VERSION ""

NS_ :

BS_:

BU_: SHVU_CCS_FD ARS_FD WPC_FD WPC2_FD SCM_FD SHVU_FRNT_FD FLLR_FD vDummy_FD_B2 GW_SAU_DRV_FD ATS_FD PSB_FD GW_PSU_RR_FD SHVU_RL_FD RWPC_FD CGW_CCU OHCL_FD SHVU_REAR_FD BLTN_CAM_FD GW_PSU_DRV_FD FCS_FD GW_PSU_AST_FD GW_PSU_3RD_FD RCS_FD GW_PSU_RL_FD SHVU_3RD_FD SHVU_RR_FD RCM_FD DCM_FD SGU_FD vFD_B2

BO_ 745 PDC_FD_15_300ms: 32 CGW_CCU
 SG_ PDC_FD_Crc15Val : 0|16@1+ (1,0) [0|0] ""  ARS_FD,ATS_FD,BLTN_CAM_FD,FCS_FD,GW_PSU_3RD_FD,GW_PSU_AST_FD,GW_PSU_DRV_FD,GW_PSU_RL_FD,GW_PSU_RR_FD,GW_SAU_DRV_FD,OHCL_FD,PSB_FD,RCM_FD,RCS_FD,RWPC_FD,SCM_FD,SGU_FD,SHVU_3RD_FD,SHVU_FRNT_FD,SHVU_REAR_FD,SHVU_RL_FD,SHVU_RR_FD,WPC2_FD,WPC_FD
 SG_ PDC_CurrAtReset : 104|12@1+ (10,-40940) [-40940|0] "mA" Vector__XXX
 SG_ PDC_AvgCurrAtReset : 120|12@1+ (10,-40940) [-40940|0] "mA" Vector__XXX
 SG_ PDC_ResetReason : 132|3@1+ (1,0) [0|0] "" Vector__XXX
 SG_ PDC_CumulativeCountOf12VReq : 136|10@1+ (1,0) [0|0] "" Vector__XXX
 SG_ PDC_CumulativeCountOfCCUReq : 146|10@1+ (1,0) [0|0] "" Vector__XXX
 SG_ PDC_VehCondiForReset : 156|2@1+ (1,0) [0|0] "" Vector__XXX
 SG_ PDC_FD_AlvCnt15Val : 16|8@1+ (1,0) [0|0] ""  ARS_FD,ATS_FD,BLTN_CAM_FD,FCS_FD,GW_PSU_3RD_FD,GW_PSU_AST_FD,GW_PSU_DRV_FD,GW_PSU_RL_FD,GW_PSU_RR_FD,GW_SAU_DRV_FD,OHCL_FD,PSB_FD,RCM_FD,RCS_FD,RWPC_FD,SCM_FD,SGU_FD,SHVU_3RD_FD,SHVU_FRNT_FD,SHVU_REAR_FD,SHVU_RL_FD,SHVU_RR_FD,WPC2_FD,WPC_FD
 SG_ PDC_LDConReq : 184|2@1+ (1,0) [0|0] ""  BLTN_CAM_FD
 SG_ PDC_LDConReq_By_LVBat : 186|2@1+ (1,0) [0|0] ""  BLTN_CAM_FD
 SG_ PDC_LDConReq_By_OTA : 188|2@1+ (1,0) [0|0] "" Vector__XXX
 SG_ PDC_LDConReq_By_Load : 190|2@1+ (1,0) [0|0] "" Vector__XXX
 SG_ PDC_LDConReq_By_ActiveOn : 192|2@1+ (1,0) [0|0] ""  BLTN_CAM_FD
 SG_ PDC_ResetPreWrngForCCU : 40|2@1+ (1,0) [0|0] "" Vector__XXX
 SG_ PDC_ResetPreWrngForOthers : 42|2@1+ (1,0) [0|0] ""  ARS_FD,ATS_FD,BLTN_CAM_FD,DCM_FD,FCS_FD,GW_PSU_3RD_FD,GW_PSU_AST_FD,GW_PSU_DRV_FD,GW_PSU_RL_FD,GW_PSU_RR_FD,GW_SAU_DRV_FD,OHCL_FD,PSB_FD,RCM_FD,RCS_FD,RWPC_FD,SCM_FD,SGU_FD,SHVU_3RD_FD,SHVU_FRNT_FD,SHVU_REAR_FD,SHVU_RL_FD,SHVU_RR_FD,WPC2_FD,WPC_FD
 SG_ PDC_ResetReqForCCU : 44|2@1+ (1,0) [0|0] "" Vector__XXX
 SG_ PDC_ResetReqForOthers : 46|2@1+ (1,0) [0|0] ""  ARS_FD,ATS_FD,BLTN_CAM_FD,DCM_FD,FCS_FD,GW_PSU_3RD_FD,GW_PSU_AST_FD,GW_PSU_DRV_FD,GW_PSU_RL_FD,GW_PSU_RR_FD,GW_SAU_DRV_FD,OHCL_FD,PSB_FD,RCM_FD,RCS_FD,RWPC_FD,SCM_FD,SGU_FD,SHVU_3RD_FD,SHVU_FRNT_FD,SHVU_REAR_FD,SHVU_RL_FD,SHVU_RR_FD,WPC2_FD,WPC_FD
 SG_ PDC_ResetFuncOpt : 48|2@1+ (1,0) [0|0] ""  DCM_FD,RWPC_FD,WPC2_FD,WPC_FD
 SG_ PDC_12VRlyCtrl : 50|2@1+ (1,0) [0|0] "" Vector__XXX
 SG_ PDC_CurrentValueForReset : 52|8@1+ (50,0) [0|0] "mA" Vector__XXX
 SG_ PDC_WakeUpReqForReset : 60|2@1+ (1,0) [0|0] "" Vector__XXX
 SG_ PDC_TimeValueForReset : 64|8@1+ (0.5,0) [0|0] "h" Vector__XXX
 SG_ PDC_12VRlyOffHoldingTime : 72|5@1+ (0.5,0) [0|0] "s" Vector__XXX
 SG_ PDC_ResetCountSetting : 77|2@1+ (1,0) [0|0] "" Vector__XXX
 SG_ PDC_ResetCount : 79|2@1+ (1,0) [0|0] "" Vector__XXX
 SG_ PDC_ResetCumulativeCount : 81|10@1+ (1,0) [0|0] "" Vector__XXX
 SG_ PDC_ResetOpsta : 91|2@1+ (1,0) [0|0] "" Vector__XXX
 SG_ PDC_ReadyTimeValueForReset : 96|8@1+ (10,0) [0|255] "Min" Vector__XXX

BO_ 64 TCU_01_10ms: 32 CGW_CCU
 SG_ TCU_Crc1Val : 0|16@1+ (1,0) [0|0] "" Vector__XXX
 SG_ TCU_DcmlVehSpdKphVal : 104|8@1+ (0.0078125,0) [0|0] "km/h" Vector__XXX
 SG_ TCU_SprkRtrdReq : 112|8@1+ (0.375,-23.625) [0|0] "˚" Vector__XXX
 SG_ TCU_EngRpmDisSta : 120|2@1+ (1,0) [0|0] "" Vector__XXX
 SG_ TCU_GearLmpBlnkngReq : 122|2@1+ (1,0) [0|0] "" Vector__XXX
 SG_ TCU_FuelCutInhbtReq : 124|2@1+ (1,0) [0|0] "" Vector__XXX
 SG_ TCU_IdleUpReq : 126|2@1+ (1,0) [0|0] "" Vector__XXX
 SG_ TCU_EngRpmDis : 128|16@1+ (0.25,0) [0|0] "rpm" Vector__XXX
 SG_ TCU_SlpVal : 144|6@1+ (0.5,-16) [0|0] "%" Vector__XXX
 SG_ TCU_EngSpdIncReq : 150|2@1+ (1,0) [0|0] "" Vector__XXX
 SG_ TCU_ObdSta : 152|3@1+ (1,0) [0|0] "" Vector__XXX
 SG_ TCU_SprtyIndxSta : 155|5@1+ (1,0) [0|0] "" Vector__XXX
 SG_ TCU_AlvCnt1Val : 16|8@1+ (1,0) [0|0] "" Vector__XXX
 SG_ TCU_DrvngModDis : 160|3@1+ (1,0) [0|0] "" Vector__XXX
 SG_ TCU_DrvngModReq : 163|3@1+ (1,0) [0|0] "" Vector__XXX
 SG_ TCU_SmrtShftSta : 166|2@1+ (1,0) [0|0] "" Vector__XXX
 SG_ TCU_LupTrgtEngSpdVal : 168|8@1+ (10,500) [0|0] "rpm" Vector__XXX
 SG_ TCU_FrtStcShftSta : 176|2@1+ (1,0) [0|0] "" Vector__XXX
 SG_ TCU_IsgInhbtReq : 178|2@1+ (1,0) [0|0] "" Vector__XXX
 SG_ TCU_CdaInhbtReq : 180|2@1+ (1,0) [0|0] "" Vector__XXX
 SG_ TCU_BrkOnReq : 182|2@1+ (1,0) [0|0] "" Vector__XXX
 SG_ TCU_TqGrdntLimVal : 184|8@1+ (10,0) [0|0] "Nm/s" Vector__XXX
 SG_ TCU_NetrlCtrlSta : 192|2@1+ (1,0) [0|0] "" Vector__XXX
 SG_ TCU_ShftPtrnSta : 194|4@1+ (1,0) [0|0] "" Vector__XXX
 SG_ TCU_VgisInhbtReq : 198|2@1+ (1,0) [0|0] "" Vector__XXX
 SG_ TCU_EngTqIncReqVal : 200|12@1- (1,0) [0|0] "Nm" Vector__XXX
 SG_ TCU_EPBReq : 212|1@1+ (1,0) [0|0] "" Vector__XXX
 SG_ IMT_EOLstate : 213|1@1+ (1,0) [0|0] "" Vector__XXX
 SG_ IMT_DisCmd : 214|2@1+ (1,0) [0|0] "" Vector__XXX
 SG_ IMT_CltchPdlPos : 216|8@1+ (0.390625,0) [0|0] "%" Vector__XXX
 SG_ DCT_RegenInhbt : 224|2@1+ (1,0) [0|0] "" Vector__XXX
 SG_ DCT_EngIdleReq : 226|2@1+ (1,0) [0|0] "" Vector__XXX
 SG_ DCT_CltchState : 228|2@1+ (1,0) [0|0] "" Vector__XXX
 SG_ DCT_FuelCutReq : 230|2@1+ (1,0) [0|0] "" Vector__XXX
 SG_ DCT_TqIncReq : 232|2@1+ (1,0) [0|0] "" Vector__XXX
 SG_ DCT_CrpTqReq : 234|10@1+ (1,-512) [0|0] "Nm" Vector__XXX
 SG_ DCT_ShftTqReq : 244|12@1- (1,0) [0|0] "Nm" Vector__XXX
 SG_ TCU_GearSlctDis : 32|4@1+ (1,0) [0|0] ""  BLTN_CAM_FD,DCM_FD,FCS_FD,GW_PSU_3RD_FD,GW_PSU_AST_FD,GW_PSU_RL_FD,GW_PSU_RR_FD,SHVU_RL_FD,SHVU_RR_FD
 SG_ TCU_Typ : 36|4@1+ (1,0) [0|0] ""  GW_PSU_3RD_FD,GW_PSU_AST_FD
 SG_ TCU_TqRdctnVal : 40|12@1- (1,0) [0|0] "Nm" Vector__XXX
 SG_ CF_TCU_AES_Flag : 52|1@1+ (1,0) [0|0] "" Vector__XXX
 SG_ TCU_GearStepTyp : 56|4@1+ (1,0) [0|0] "" Vector__XXX
 SG_ TCU_GearShftSta : 60|2@1+ (1,0) [0|0] "" Vector__XXX
 SG_ TCU_TqCnvrtrSta : 62|2@1+ (1,0) [0|0] "" Vector__XXX
 SG_ TCU_CurrGearSta : 64|4@1+ (1,0) [0|0] "" Vector__XXX
 SG_ TCU_TrgtGearSta : 68|4@1+ (1,0) [0|0] "" Vector__XXX
 SG_ TCU_CluTrgtGearSta : 72|4@1+ (1,0) [0|0] "" Vector__XXX
 SG_ TCH_EngTrgtGearSta : 76|4@1+ (1,0) [0|0] "" Vector__XXX
 SG_ TCU_EngTqLimVal : 80|12@1- (1,0) [0|0] "Nm" Vector__XXX
 SG_ TCU_CluTrgtGearConfg : 92|2@1+ (1,0) [0|0] "" Vector__XXX
 SG_ TCU_DesiBoost : 94|1@1+ (1,0) [0|0] "" Vector__XXX
 SG_ TCU_VehSpdKphVal : 96|8@1+ (1,0) [0|0] "km/h" Vector__XXX

BO_ 1308 CCU_VAPI_BLTNCAM_01_00ms: 32 CGW_CCU
 SG_ VAPI_BltnCamInsideSwEnable_Set : 24|2@1+ (1,0) [0|0] ""  BLTN_CAM_FD

BO_ 613 EMS_08_100ms: 32 CGW_CCU
 SG_ EMS_Crc8Val : 0|16@1+ (1,0) [0|0] "" Vector__XXX
 SG_ HEV_EstClntTempVal : 128|8@1+ (0.75,-48) [0|0] "℃" Vector__XXX
 SG_ HEV_AptVal : 136|8@1+ (2,0) [0|0] "PSI" Vector__XXX
 SG_ HEV_EstAmbtAirTempVal : 144|8@1+ (0.75,-48) [0|0] "℃" Vector__XXX
 SG_ HEV_RbmSta : 152|7@1+ (1,0) [0|0] "" Vector__XXX
 SG_ HEV_WarmUpReq_For_DATC : 159|1@1+ (1,0) [0|0] "" Vector__XXX
 SG_ EMS_AlvCnt8Val : 16|8@1+ (1,0) [0|0] "" Vector__XXX
 SG_ HEV_RbmInhbtSta : 160|2@1+ (1,0) [0|0] "" Vector__XXX
 SG_ HEV_EhrsTempSta : 162|2@1+ (1,0) [0|0] "" Vector__XXX
 SG_ HEV_Aaf_WrnLamp : 164|2@1+ (1,0) [0|0] "" Vector__XXX
 SG_ HEV_OPSFail : 166|2@1+ (1,0) [0|0] "" Vector__XXX
 SG_ HEV_EngDsplceTyp : 168|8@1+ (0.1,0) [0|0] "liter" Vector__XXX
 SG_ HEV_EngTyp2 : 176|4@1+ (1,0) [0|0] "" Vector__XXX
 SG_ HEV_EngTyp1 : 180|4@1+ (1,0) [0|0] "" Vector__XXX
 SG_ HEV_S_F : 184|2@1+ (1,0) [0|0] "" Vector__XXX
 SG_ HEV_S_F_GEN : 186|3@1+ (1,0) [0|0] "" Vector__XXX
 SG_ HEV_RbmSta_2nd : 192|7@1+ (1,0) [0|0] "" Vector__XXX
 SG_ HEV_RECTrigSta : 200|1@1+ (1,0) [0|0] "" Vector__XXX
 SG_ HEV_PendingTrigSta : 201|1@1+ (1,0) [0|0] "" Vector__XXX
 SG_ HEV_OilLifeRatio : 202|7@1+ (1,0) [0|0] "%" Vector__XXX
 SG_ HEV_OilLifeEna : 209|2@1+ (1,0) [0|0] "" Vector__XXX
 SG_ HEV_OilLifeWarn : 211|3@1+ (1,0) [0|0] "" Vector__XXX
 SG_ HEV_ExtSoakTimeVal : 214|6@1+ (5,0) [0|0] "" Vector__XXX
 SG_ HEV_AmbPrs : 220|12@1+ (1.3269841,0) [0|0] "hPa" Vector__XXX
 SG_ HEV_EngClntTempVal : 24|8@1+ (0.75,-48) [0|0] "℃" Vector__XXX
 SG_ HEV_EngOilTempVal : 32|8@1+ (1,-40) [0|0] "℃" Vector__XXX
 SG_ HEV_VbOffActSta : 40|2@1+ (1,0) [0|0] "" Vector__XXX
 SG_ HEV_AirCompOffReq : 42|2@1+ (1,0) [0|0] "" Vector__XXX
 SG_ HEV_MilConfgVal : 44|3@1+ (1,0) [0|0] "" Vector__XXX
 SG_ HEV_CF_EMS_LOCKUP : 47|1@1+ (1,0) [0|0] "" Vector__XXX
 SG_ HEV_OilLvlSta : 48|2@1+ (1,0) [0|0] "" Vector__XXX
 SG_ HEV_ImmoLmpReq : 50|2@1+ (1,0) [0|0] "" Vector__XXX
 SG_ HEV_MilReq : 52|2@1+ (1,0) [0|0] "" Vector__XXX
 SG_ HEV_WiperSwSta : 54|2@1+ (1,0) [0|0] "" Vector__XXX
 SG_ HEV_FanOpSta : 56|2@1+ (1,0) [0|0] "" Vector__XXX
 SG_ HEV_FanSta : 58|2@1+ (1,0) [0|0] "" Vector__XXX
 SG_ HEV_BrkLtSwSta : 62|2@1+ (1,0) [0|0] ""  BLTN_CAM_FD
 SG_ HEV_IgnCycCntVal : 64|16@1+ (1,0) [0|0] "" Vector__XXX
 SG_ HEV_SoakTimeVal : 80|8@1+ (1,0) [0|0] "Min" Vector__XXX
 SG_ HEV_SoakTimeErrSta : 88|2@1+ (1,0) [0|0] "" Vector__XXX
 SG_ HEV_SoakTimeOvrSta : 90|2@1+ (1,0) [0|0] "" Vector__XXX
 SG_ HEV_FuelRunOutSta : 92|2@1+ (1,0) [0|0] "" Vector__XXX
 SG_ HEV_FuelRunOutDetSta : 94|2@1+ (1,0) [0|0] "" Vector__XXX
 SG_ HEV_FuelCnsmptSumVal : 96|32@1+ (0.0001280018,0) [0|0] "ml" Vector__XXX

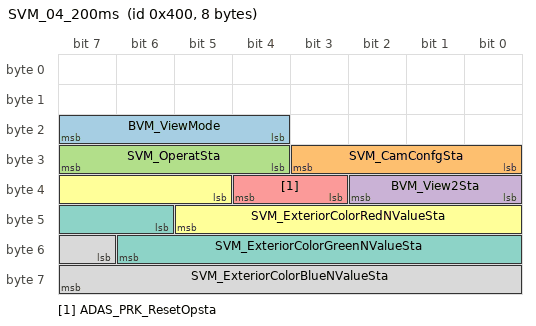
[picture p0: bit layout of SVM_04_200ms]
BO_ 1024 SVM_04_200ms: 8 CGW_CCU
 SG_ BVM_ViewMode : 20|4@1+ (1,0) [0|0] "" Vector__XXX
 SG_ SVM_CamConfgSta : 24|4@1+ (1,0) [0|0] ""  BLTN_CAM_FD
 SG_ SVM_OperatSta : 28|4@1+ (1,0) [0|0] ""  BLTN_CAM_FD
 SG_ BVM_View2Sta : 32|3@1+ (1,0) [0|0] "" Vector__XXX
 SG_ ADAS_PRK_ResetOpsta : 35|2@1+ (1,0) [0|0] "" Vector__XXX
 SG_ SVM_ExteriorColorRedNValueSta : 37|9@1+ (1,0) [0|0] "" Vector__XXX
 SG_ SVM_ExteriorColorGreenNValueSta : 46|9@1+ (1,0) [0|0] "" Vector__XXX
 SG_ SVM_ExteriorColorBlueNValueSta : 55|9@1+ (1,0) [0|0] "" Vector__XXX

BO_ 1026 BDC_FD_SMK_03_200ms: 32 CGW_CCU
 SG_ BDC_FD_SMK_Crc3Val : 0|16@1+ (1,0) [0|0] "" Vector__XXX
 SG_ SMK_TrmnlCtrlStaBDCEV : 104|5@1+ (1,0) [0|0] ""  BLTN_CAM_FD
 SG_ SMK_PwrOnModeSta : 109|2@1+ (1,0) [0|0] ""  SGU_FD
 SG_ SMK_StndbyMdTmrMin : 112|6@1+ (1,0) [0|0] "" Vector__XXX
 SG_ SMK_PwrTransitionReq : 118|2@1+ (1,0) [0|0] "" Vector__XXX
 SG_ SMK_StndbyMdTmrSec : 120|6@1+ (1,0) [0|0] "" Vector__XXX
 SG_ SMK_VhclSlpSta : 126|2@1+ (1,0) [0|0] "" Vector__XXX
 SG_ USM_SmrtSldngModSta : 128|3@1+ (1,0) [0|0] "" Vector__XXX
 SG_ SMK_EVPwrOffReq : 131|2@1+ (1,0) [0|0] "" Vector__XXX
 SG_ SMK_MaintenanceSrvMdReq : 133|2@1+ (1,0) [0|0] "" Vector__XXX
 SG_ Warn_DisWrngSta3 : 135|5@1+ (1,0) [0|0] ""  ATS_FD
 SG_ SMK_CCUOTACrankInhState : 140|2@1+ (1,0) [0|0] "" Vector__XXX
 SG_ SMK_NParkModePwrOFFResult : 142|2@1+ (1,0) [0|0] "" Vector__XXX
 SG_ SMK_TwoPressStrtSta : 144|2@1+ (1,0) [0|0] "" Vector__XXX
 SG_ SMK_PwrOffDspBtnActvSta : 146|2@1+ (1,0) [0|0] "" Vector__XXX
 SG_ SMK_GetOffPopUpReq : 148|2@1+ (1,0) [0|0] "" Vector__XXX
 SG_ SMK_PwrOffHardBtnPopupReq : 150|3@1+ (1,0) [0|0] "" Vector__XXX
 SG_ SMK_EVRdyOffReq : 153|2@1+ (1,0) [0|0] "" Vector__XXX
 SG_ SMK_NTowMdAuthFailSta : 155|2@1+ (1,0) [0|0] "" Vector__XXX
 SG_ SMK_SftyMdExitOKSta : 157|2@1+ (1,0) [0|0] "" Vector__XXX
 SG_ SMK_SftyMdPopup : 159|3@1+ (1,0) [0|0] "" Vector__XXX
 SG_ BDC_FD_SMK_AlvCnt3Val : 16|8@1+ (1,0) [0|0] "" Vector__XXX
 SG_ SMK_HUOTACrankInhState : 162|2@1+ (1,0) [0|0] "" Vector__XXX
 SG_ SMK_EasyPwrOffOpt : 164|2@1+ (1,0) [0|0] "" Vector__XXX
 SG_ SMK_EasyPwrOffInProgress : 166|2@1+ (1,0) [0|0] "" Vector__XXX
 SG_ ESCL_EsclMngrSta : 24|4@1+ (1,0) [0|0] "" Vector__XXX
 SG_ ESCL_EsclPwrSupSta : 28|2@1+ (1,0) [0|0] "" Vector__XXX
 SG_ Fob_FoundExtrnlIntArea : 30|2@1+ (1,0) [0|0] "" Vector__XXX
 SG_ ESCL_EsclEnaSta : 32|2@1+ (1,0) [0|0] "" Vector__XXX
 SG_ ESCL_EsclUnitSta : 34|3@1+ (1,0) [0|0] "" Vector__XXX
 SG_ ESCL_EsclBoltSta : 37|3@1+ (1,0) [0|0] "" Vector__XXX
 SG_ ESCL_EsclLoBattSta : 40|3@1+ (1,0) [0|0] "" Vector__XXX
 SG_ ESCL_EsclUnLkSwSta : 43|3@1+ (1,0) [0|0] "" Vector__XXX
 SG_ Fob_FoundRrLftArea : 46|2@1+ (1,0) [0|0] "" Vector__XXX
 SG_ Fob_FoundRrRtArea : 48|2@1+ (1,0) [0|0] "" Vector__XXX
 SG_ Warn_StrtStpBtnWrngSta : 50|2@1+ (1,0) [0|0] "" Vector__XXX
 SG_ Warn_DeActvWrngSta : 52|2@1+ (1,0) [0|0] "" Vector__XXX
 SG_ Warn_GearPosPWrngReq : 54|2@1+ (1,0) [0|0] "" Vector__XXX
 SG_ Warn_ExtrnlBuzWrngSta : 56|4@1+ (1,0) [0|0] "" Vector__XXX
 SG_ Warn_IdOutWrngSta : 60|2@1+ (1,0) [0|0] "" Vector__XXX
 SG_ Warn_KeyBattLoWrngSta : 62|2@1+ (1,0) [0|0] "" Vector__XXX
 SG_ Warn_KeyOutLmpOnReq : 64|2@1+ (1,0) [0|0] "" Vector__XXX
 SG_ Warn_NotGearPosPWrngSta : 66|2@1+ (1,0) [0|0] "" Vector__XXX
 SG_ Warn_EsclFlWrngSta : 68|2@1+ (1,0) [0|0] "" Vector__XXX
 SG_ Warn_EsclNotLkWrngSta : 70|2@1+ (1,0) [0|0] "" Vector__XXX
 SG_ Warn_EsclNotUnLkWrngSta : 72|2@1+ (1,0) [0|0] "" Vector__XXX
 SG_ Warn_ImmoLmpOnReq : 74|2@1+ (1,0) [0|0] "" Vector__XXX
 SG_ Warn_DisWrngSta2 : 76|4@1+ (1,0) [0|0] "" Vector__XXX
 SG_ Warn_DisWrngSta : 80|5@1+ (1,0) [0|0] "" Vector__XXX
 SG_ SMK_OTACrankInhState : 85|3@1+ (1,0) [0|0] "" Vector__XXX
 SG_ SMK_TgltAwaySrchResult : 88|2@1+ (1,0) [0|0] "" Vector__XXX
 SG_ SMKFOBID_CHNAVNT : 90|3@1+ (1,0) [0|0] "" Vector__XXX
 SG_ SMK_TrmnlCtrlGrpStaBDC : 93|3@1+ (1,0) [0|0] ""  BLTN_CAM_FD
 SG_ SMK_TrmnlCtrlGrpStaBDCEV : 96|3@1+ (1,0) [0|0] ""  BLTN_CAM_FD
 SG_ SMK_TrmnlCtrlStaBDC : 99|5@1+ (1,0) [0|0] "" Vector__XXX

BO_ 193 BLTN_CAM_FD_01_00ms: 16 BLTN_CAM_FD
 SG_ BLTN_CAM_FD_Crc1Val : 0|16@1+ (1,0) [0|0] "" Vector__XXX
 SG_ BLTN_CAM_FD_AlvCnt1Val : 16|8@1+ (1,0) [0|0] "" Vector__XXX
 SG_ BLTN_CAM_UI_Mode_Tmt_Req : 64|2@1+ (1,0) [0|0] ""  CGW_CCU
 SG_ BLTN_CAM_PopUp_Req : 66|4@1+ (1,0) [0|0] ""  CGW_CCU
 SG_ BLTN_CAM_File_List_Renew : 70|2@1+ (1,0) [0|0] ""  CGW_CCU
 SG_ BLTN_CAM_Wifi_Pwd_Chg_State : 72|2@1+ (1,0) [0|0] ""  CGW_CCU
 SG_ BLTN_CAM_Dis_Touch_BeepSound : 74|2@1+ (1,0) [0|0] ""  CGW_CCU

BO_ 345 LBM_FD_02_100ms: 32 CGW_CCU
 SG_ LBM_FD_Crc2Val : 0|16@1+ (1,0) [0|0] "" Vector__XXX
 SG_ MainLBM_NormalPwrVal : 112|16@1+ (1,0) [0|0] "Watt" Vector__XXX
 SG_ MainLBM_NormalWhVal : 128|16@1+ (1,0) [0|0] "Wh" Vector__XXX
 SG_ MainLBM_NormalReserveTimeVal : 144|20@1+ (1,0) [0|0] "Sec" Vector__XXX
 SG_ LBM_FD_AlvCnt2Val : 16|8@1+ (1,0) [0|0] "" Vector__XXX
 SG_ MainLBM_SleepReserveTimeVal : 164|20@1+ (1,0) [0|0] "Min" Vector__XXX
 SG_ MainLBM_CurrVal : 24|16@1+ (0.01,-327) [0|0] "A"  BLTN_CAM_FD
 SG_ MainLBM_SocVal : 40|8@1+ (1,0) [0|0] ""  BLTN_CAM_FD
 SG_ MainLBM_VtgVal : 48|14@1+ (0.001,6) [0|0] "V"  BLTN_CAM_FD
 SG_ MainLBM_TempVal : 62|9@1+ (0.5,-40) [0|0] "℃"  BLTN_CAM_FD
 SG_ MainLBM_SocErrSta : 71|2@1+ (1,0) [0|0] ""  BLTN_CAM_FD
 SG_ MainLBM_SohVal : 73|8@1+ (1,0) [0|0] "%"  BLTN_CAM_FD
 SG_ MainLBM_SnsrInvldSta : 81|2@1+ (1,0) [0|0] ""  BLTN_CAM_FD
 SG_ MainLBM_RspErrSta : 83|2@1+ (1,0) [0|0] ""  BLTN_CAM_FD
 SG_ MainLBM_CapacityVal : 85|8@1+ (1,0) [0|0] ""  BLTN_CAM_FD
 SG_ MainLBM_SohErrSta : 93|2@1+ (1,0) [0|0] ""  BLTN_CAM_FD
 SG_ MainLBM_PeakLoadPwrVal : 96|16@1+ (1,0) [0|0] "Watt" Vector__XXX

BO_ 74 IMU_01_10ms: 32 CGW_CCU
 SG_ IMU_Crc1Val : 0|16@1+ (1,0) [0|0] "" Vector__XXX
 SG_ IMU_SnsrTempVal : 112|8@1+ (1,-68) [0|0] "℃" Vector__XXX
 SG_ IMU_SeralNumVal : 128|48@1+ (1,0) [0|0] "" Vector__XXX
 SG_ IMU_AlvCnt1Val : 16|8@1+ (1,0) [0|0] "" Vector__XXX
 SG_ IMU_RollRtVal : 192|16@1+ (0.005,-163.84) [0|0] "˚/s" Vector__XXX
 SG_ IMU_VerAccelVal : 208|16@1+ (0.000127465,-4.17677312) [0|0] "g" Vector__XXX
 SG_ IMU_PitchRtVal : 224|16@1+ (0.005,-163.84) [-163.84|163.83] "˚/s" Vector__XXX
 SG_ IMU_YawSigSta : 24|4@1+ (1,0) [0|0] ""  PSB_FD
 SG_ IMU_LatAccelSigSta : 28|4@1+ (1,0) [0|0] ""  BLTN_CAM_FD,PSB_FD
 SG_ IMU_LongAccelSigSta : 32|4@1+ (1,0) [0|0] ""  BLTN_CAM_FD,PSB_FD
 SG_ IMU_VerAccelSigSta : 36|4@1+ (1,0) [0|0] "" Vector__XXX
 SG_ IMU_McuVoltSta : 40|4@1+ (1,0) [0|0] "" Vector__XXX
 SG_ IMU_AcuRstSta : 44|4@1+ (1,0) [0|0] "" Vector__XXX
 SG_ IMU_SnsrTyp : 48|4@1+ (1,0) [0|0] "" Vector__XXX
 SG_ IMU_RollSigSta : 56|4@1+ (1,0) [0|0] "" Vector__XXX
 SG_ IMU_PitchSigSta : 60|4@1+ (1,0) [0|0] "" Vector__XXX
 SG_ IMU_YawRtVal : 64|16@1+ (0.005,-163.84) [0|0] "˚/s"  PSB_FD
 SG_ IMU_LatAccelVal : 80|16@1+ (0.000127465,-4.17677312) [0|0] "g"  BLTN_CAM_FD,PSB_FD
 SG_ IMU_LongAccelVal : 96|16@1+ (0.000127465,-4.17677312) [0|0] "g"  BLTN_CAM_FD,PSB_FD

BO_ 194 BMS_FD_01_00ms: 16 CGW_CCU
 SG_ BMS_FD_Crc1Val : 0|16@1+ (1,0) [0|0] "" Vector__XXX
 SG_ BMS_FD_AlvCnt1Val : 16|8@1+ (1,0) [0|0] "" Vector__XXX
 SG_ xEV_BatEvtAlarm_HS : 64|3@1+ (1,0) [0|0] "" Vector__XXX
 SG_ xEV_BMS_WakeUpReqfor12V : 67|2@1+ (1,0) [0|0] "" Vector__XXX
 SG_ xEV_AuxBattChrgReq_HS : 69|2@1+ (1,0) [0|0] ""  BLTN_CAM_FD
 SG_ xEV_12VBatAlarmReq_HS : 72|2@1+ (1,0) [0|0] ""  BLTN_CAM_FD
 SG_ BMS_ResetWakeup : 74|2@1+ (1,0) [0|0] "" Vector__XXX
 SG_ xEV_IG3OnReq : 76|4@1+ (1,0) [0|0] "" Vector__XXX

BO_ 1048 GNSS_06_1000ms: 32 CGW_CCU
 SG_ GNSS_Crc6Val : 0|16@1+ (1,0) [0|0] "" Vector__XXX
 SG_ HU_MM_Altitude : 128|32@1- (0.01,0) [0|0] "m"  BLTN_CAM_FD
 SG_ GNSS_AlvCnt6Val : 16|8@1+ (1,0) [0|0] "" Vector__XXX
 SG_ HU_MM_Heading : 160|32@1+ (1,0) [0|0] "˚"  BLTN_CAM_FD
 SG_ GNSS_MM_type : 192|4@1+ (1,0) [0|0] ""  BLTN_CAM_FD
 SG_ HU_MM_Latitude : 64|32@1- (1E-006,0) [0|0] "˚"  BLTN_CAM_FD
 SG_ HU_MM_Longitude : 96|32@1- (1E-006,0) [0|0] "˚"  BLTN_CAM_FD

BO_ 1051 HU_CLOCK_01_1000ms: 16 CGW_CCU
 SG_ HU_CLOCK_Crc1Val : 0|16@1+ (1,0) [0|0] "" Vector__XXX
 SG_ HU_DisplayYear1 : 102|2@1+ (1,0) [0|0] ""  ATS_FD,BLTN_CAM_FD
 SG_ HU_DisplayYear2 : 104|8@1+ (1,0) [0|0] ""  ATS_FD,BLTN_CAM_FD
 SG_ HU_DisplayDay : 112|8@1+ (1,0) [0|0] ""  ATS_FD,BLTN_CAM_FD
 SG_ HU_AM_PM_INFO : 120|2@1+ (1,0) [0|0] ""  ATS_FD,BLTN_CAM_FD
 SG_ HU_ComRefresh : 124|2@1+ (1,0) [0|0] ""  ATS_FD,BLTN_CAM_FD
 SG_ HU_ClockInfo : 126|2@1+ (1,0) [0|0] ""  ATS_FD,BLTN_CAM_FD
 SG_ HU_CLOCK_AlvCnt1Val : 16|8@1+ (1,0) [0|0] "" Vector__XXX
 SG_ HU_TimeSetting : 64|2@1+ (1,0) [0|0] ""  ATS_FD,BLTN_CAM_FD
 SG_ HU_Status : 66|4@1+ (1,0) [0|0] ""  ATS_FD,BLTN_CAM_FD
 SG_ HU_TimeFormat : 70|2@1+ (1,0) [0|0] ""  ATS_FD,BLTN_CAM_FD
 SG_ HU_DisplayHour : 72|8@1+ (1,0) [0|0] ""  ATS_FD,BLTN_CAM_FD
 SG_ HU_DisplayMinute : 80|8@1+ (1,0) [0|0] ""  ATS_FD,BLTN_CAM_FD
 SG_ HU_DisplaySecond : 88|8@1+ (1,0) [0|0] ""  ATS_FD,BLTN_CAM_FD
 SG_ HU_DisplayMonth : 98|4@1+ (1,0) [0|0] ""  ATS_FD,BLTN_CAM_FD

BO_ 1052 HU_CLU_02_1000ms: 16 CGW_CCU
 SG_ HU_CLU_Crc2Val : 0|16@1+ (1,0) [0|0] "" Vector__XXX
 SG_ HU_EVSupport : 104|2@1+ (1,0) [0|0] "" Vector__XXX
 SG_ HU_DayNightState : 108|2@1+ (1,0) [0|0] "" Vector__XXX
 SG_ HU_AutoBrightState_New : 118|10@1+ (1,0) [0|0] "" Vector__XXX
 SG_ HU_CLU_AlvCnt2Val : 16|8@1+ (1,0) [0|0] "" Vector__XXX
 SG_ HU_OffloadBtnReq : 24|2@1+ (1,0) [0|0] "" Vector__XXX
 SG_ HU_LanguageInfo : 64|8@1+ (1,0) [0|0] ""  ATS_FD,BLTN_CAM_FD,DCM_FD
 SG_ HU_MuteStatus : 78|2@1+ (1,0) [0|0] "" Vector__XXX
 SG_ HU_WelcomeReady : 80|2@1+ (1,0) [0|0] "" Vector__XXX
 SG_ HU_UsmSupport : 82|2@1+ (1,0) [0|0] "" Vector__XXX
 SG_ HU_NaviStatus : 84|2@1+ (1,0) [0|0] "" Vector__XXX
 SG_ HU_NaviDisp : 86|2@1+ (1,0) [0|0] "" Vector__XXX
 SG_ HU_BVM_Display_Message : 88|3@1+ (1,0) [0|0] "" Vector__XXX
 SG_ HU_NaviCamSettingStatus : 96|8@1+ (1,0) [0|0] "" Vector__XXX

CM_ BO_ 745 "[PE] Periodic and On Event";
CM_ SG_ 745 PDC_FD_Crc15Val "PDC_FD_CyclicRedundancyCheck15Value";
CM_ SG_ 745 PDC_CurrAtReset "This signal indicate the current at reset request";
CM_ SG_ 745 PDC_AvgCurrAtReset "This signal indicate the average current at reset request";
CM_ SG_ 745 PDC_ResetReason "This signal indicate the reason reset is operated";
CM_ SG_ 745 PDC_CumulativeCountOf12VReq "This signal indicates the cumulative number of 12V Controller req.";
CM_ SG_ 745 PDC_CumulativeCountOfCCUReq "This signal indicates the cumulative number of CCU_ForcedPowerOffReq";
CM_ SG_ 745 PDC_VehCondiForReset "This signal indicates whether the vehicle is in a state that allows for a reset or not.";
CM_ SG_ 745 PDC_FD_AlvCnt15Val "PDC_FD_AliveCounter15Value";
CM_ SG_ 745 PDC_LDConReq "LDC on request signal for High Voltage Battery Discharge";
CM_ SG_ 745 PDC_LDConReq_By_LVBat "LDC on request signal for High Voltage Battery Discharge by Low Voltage Battery";
CM_ SG_ 745 PDC_LDConReq_By_OTA "LDC on request signal for High Voltage Battery Discharge by OTA";
CM_ SG_ 745 PDC_LDConReq_By_Load "LDC on request signal for High Voltage Battery Discharge by Load";
CM_ SG_ 745 PDC_LDConReq_By_ActiveOn "LDC on request signal for High Voltage Battery Discharge by Active On";
CM_ SG_ 745 PDC_ResetPreWrngForCCU "This is a warning signal for reset.  This signal is used for preparing sideeffect of reset by Gateway";
CM_ SG_ 745 PDC_ResetPreWrngForOthers "This is a warning signal for reset.  This signal is used for preparing sideeffect of reset by Receivers";
CM_ SG_ 745 PDC_ResetReqForCCU "This is a request signal for SW reset of Gateway";
CM_ SG_ 745 PDC_ResetReqForOthers "This is a request signal for SW reset except for Gateway";
CM_ SG_ 745 PDC_ResetFuncOpt "This signal inform whether reset fucntion at PDC is appiled or not";
CM_ SG_ 745 PDC_12VRlyCtrl "This signal is request signal to control 12V battery internal relay for HW reset";
CM_ SG_ 745 PDC_CurrentValueForReset "This signal sets the average discharge current value to be measured for PDC_TimevalueForReset to be considered as a situation requiring reset.";
CM_ SG_ 745 PDC_WakeUpReqForReset "Request to transmit controller wake-up signal for receiving reset related signal";
CM_ SG_ 745 PDC_TimeValueForReset "This signal sets the time value to be considered as a situation requiring reset.";
CM_ SG_ 745 PDC_12VRlyOffHoldingTime "This signal sets how long the relay will be turned off when performing an HW reset using a 12 V battery internal relay.";
CM_ SG_ 745 PDC_ResetCountSetting "This signal sets the number of resets performed.";
CM_ SG_ 745 PDC_ResetCount "This signal indicates how much reset has occurred.";
CM_ SG_ 745 PDC_ResetCumulativeCount "This signal indicates the cumulative number of resets performed.";
CM_ SG_ 745 PDC_ResetOpsta "This signal indicates whether the reset operation has been completed or not";
CM_ SG_ 745 PDC_ReadyTimeValueForReset "This signal sets the time value to be considered as a situation of quiescent current";
CM_ BO_ 64 "[P] Periodic";
CM_ SG_ 64 TCU_Crc1Val "TCU_CyclicRedundancyCheck1Value";
CM_ SG_ 64 TCU_DcmlVehSpdKphVal "TCU_VehicleSpeedDecimalKphValue";
CM_ SG_ 64 TCU_SprkRtrdReq "TCU_SparkRetardAngleValue";
CM_ SG_ 64 TCU_EngRpmDisSta "TCU_EngineRpmDisplayStatus";
CM_ SG_ 64 TCU_GearLmpBlnkngReq "TCU_GearLampBlinkingRequest";
CM_ SG_ 64 TCU_FuelCutInhbtReq "TCU_FuelCutInhibitionRequest";
CM_ SG_ 64 TCU_IdleUpReq "TCU_IdleUpRequest";
CM_ SG_ 64 TCU_EngRpmDis "TCU_EngineRpmDisplay";
CM_ SG_ 64 TCU_SlpVal "TCU_SlopeValue";
CM_ SG_ 64 TCU_EngSpdIncReq "TCU_EngineSpeedIncreaseRequest";
CM_ SG_ 64 TCU_ObdSta "TCU_ObdStatus";
CM_ SG_ 64 TCU_SprtyIndxSta "TCU_SportyIndexStatus";
CM_ SG_ 64 TCU_AlvCnt1Val "TCU_AliveCounter1Value";
CM_ SG_ 64 TCU_DrvngModDis "TCU_DrivingModeDisplay";
CM_ SG_ 64 TCU_DrvngModReq "TCU_DrivingModeRequest";
CM_ SG_ 64 TCU_SmrtShftSta "TCU_SmartShiftStatus";
CM_ SG_ 64 TCU_LupTrgtEngSpdVal "TCU_LupTargetEngineSpeedValue";
CM_ SG_ 64 TCU_FrtStcShftSta "TCU_FirstStaticShiftStatus";
CM_ SG_ 64 TCU_IsgInhbtReq "TCU_IsgInhibitRequest";
CM_ SG_ 64 TCU_CdaInhbtReq "TCU_CdaInhibitRequest";
CM_ SG_ 64 TCU_BrkOnReq "TCU_BrakeOnRequest";
CM_ SG_ 64 TCU_TqGrdntLimVal "TCU_TorqueGradientLimitationValue";
CM_ SG_ 64 TCU_NetrlCtrlSta "TCU_NeutralControlStatus";
CM_ SG_ 64 TCU_ShftPtrnSta "TCU_ShiftPatternStatus";
CM_ SG_ 64 TCU_VgisInhbtReq "TCU_VgisInhibitionRequest";
CM_ SG_ 64 TCU_EngTqIncReqVal "TCU_EngineTorqueIncreaseReqValue";
CM_ SG_ 64 TCU_EPBReq "EPB Request signal for prevent P-D Shock on hill";
CM_ SG_ 64 IMT_EOLstate "Gear Display for EOL mode to cluster. This signal is for IMT system only.";
CM_ SG_ 64 IMT_DisCmd "Gear Display type command to cluster . this signal is for IMT system only.";
CM_ SG_ 64 IMT_CltchPdlPos "Clutch Pedal Position. This signal is for IMT system only.";
CM_ SG_ 64 DCT_RegenInhbt "The regen inhibit request from TCU";
CM_ SG_ 64 DCT_EngIdleReq "Engine Idle Request";
CM_ SG_ 64 DCT_CltchState "DCT clutch status";
CM_ SG_ 64 DCT_FuelCutReq "TCU require ECU to perform ‘Fuel Cut’";
CM_ SG_ 64 DCT_TqIncReq "Request for Torque Increase";
CM_ SG_ 64 DCT_CrpTqReq "Pre-control torque for creeping";
CM_ SG_ 64 DCT_ShftTqReq "Pre-control torque for shifting";
CM_ SG_ 64 TCU_GearSlctDis "TCU_GearSelectDisplay";
CM_ SG_ 64 TCU_Typ "TCU_Type";
CM_ SG_ 64 TCU_TqRdctnVal "TCU_TorqueReductionValue";
CM_ SG_ 64 CF_TCU_AES_Flag "AES Flag On/Off to ECU";
CM_ SG_ 64 TCU_GearStepTyp "TCU_GearStepType";
CM_ SG_ 64 TCU_GearShftSta "TCU_GearShiftStatus";
CM_ SG_ 64 TCU_TqCnvrtrSta "TCU_TorqueConverterStatus";
CM_ SG_ 64 TCU_CurrGearSta "TCU_CurrentGearStatus";
CM_ SG_ 64 TCU_TrgtGearSta "TCU_TargetGearStatus";
CM_ SG_ 64 TCU_CluTrgtGearSta "TCU_ClusterTargetGear";
CM_ SG_ 64 TCH_EngTrgtGearSta "TCU_EngineTargetGear";
CM_ SG_ 64 TCU_EngTqLimVal "TCU_EngineTorqueLimitValue";
CM_ SG_ 64 TCU_CluTrgtGearConfg "Signal source Configuration of  Target gear for CLU";
CM_ SG_ 64 TCU_DesiBoost "TCU DesiBoost Control On/Off";
CM_ SG_ 64 TCU_VehSpdKphVal "TCU_VehicleSpeedKphValue";
CM_ BO_ 1308 "[EC] On Event and On Change";
CM_ SG_ 1308 VAPI_BltnCamInsideSwEnable_Set "0x0:Default, 0x1:Enable, 0x2:Disable, 0x3:Error indicator";
CM_ BO_ 613 "[P] Periodic";
CM_ SG_ 613 EMS_Crc8Val "EMS_CyclicRedundancyCheck8Value";
CM_ SG_ 613 HEV_EstClntTempVal "HEV_EstimatedCoolantTemperatureValue";
CM_ SG_ 613 HEV_AptVal "HEV_AptValue";
CM_ SG_ 613 HEV_EstAmbtAirTempVal "HEV_EstimatedAmbientAirTemperatureValue";
CM_ SG_ 613 HEV_RbmSta "HEV_RateBasedMonitoringStatus";
CM_ SG_ 613 HEV_WarmUpReq_For_DATC "HEV_WarmUpRequest";
CM_ SG_ 613 EMS_AlvCnt8Val "EMS_AliveCounter8Value";
CM_ SG_ 613 HEV_RbmInhbtSta "HEV_RbmInhibitionStatus";
CM_ SG_ 613 HEV_EhrsTempSta "HEV_EhrsTemperatureStatus";
CM_ SG_ 613 HEV_Aaf_WrnLamp "Air Flap Warning Lamp/Message Request Signal indicates whether Warning Lamp/Message should be displayed in the display screen in order to warn AAF System failure to customer.";
CM_ SG_ 613 HEV_OPSFail "Oil Pressure Warning Lamp Status";
CM_ SG_ 613 HEV_EngDsplceTyp "HEV_EngineDisplacementType ##2G##EMS - EMS12 - ENG_VOL";
CM_ SG_ 613 HEV_EngTyp2 "HEV_EngineType2 ##2G##EMS - EMS23 - ENG_TYPE";
CM_ SG_ 613 HEV_EngTyp1 "HEV_EngineType1 ##2G##EMS - EMS12 - ENG_CHR";
CM_ SG_ 613 HEV_S_F "AMS/ISG system type indicator";
CM_ SG_ 613 HEV_S_F_GEN "system generation type indicator";
CM_ SG_ 613 HEV_RbmSta_2nd "HEV_RateBasedMonitoringStatus";
CM_ SG_ 613 HEV_RECTrigSta "VCRM trigger bit by REC";
CM_ SG_ 613 HEV_PendingTrigSta "VCRM trigger bit by pending DTC";
CM_ SG_ 613 HEV_OilLifeRatio "Remaining engine oil life with % unit";
CM_ SG_ 613 HEV_OilLifeEna "Enabling information if engine oil life monitoring from EMS is applied or not";
CM_ SG_ 613 HEV_OilLifeWarn "Request to activate engine oil life warning";
CM_ SG_ 613 HEV_ExtSoakTimeVal "The additional Soak Time information extended from HEV_SoakTimeVal of EMS_08_100ms";
CM_ SG_ 613 HEV_AmbPrs "Ambient Pressure";
CM_ SG_ 613 HEV_EngClntTempVal "HEV_EngineCoolantTemperatureValue";
CM_ SG_ 613 HEV_EngOilTempVal "HEV_EngineOilTemperatureValue";
CM_ SG_ 613 HEV_VbOffActSta "HEV_VbOffActStatus";
CM_ SG_ 613 HEV_AirCompOffReq "HEV_AirCompressorOffRequest";
CM_ SG_ 613 HEV_MilConfgVal "HEV_MilConfigurationValue";
CM_ SG_ 613 HEV_CF_EMS_LOCKUP "Engine lock up mainentance request state";
CM_ SG_ 613 HEV_OilLvlSta "HEV_OilLevelStatus";
CM_ SG_ 613 HEV_ImmoLmpReq "HEV_ImmobilizerLampRequest";
CM_ SG_ 613 HEV_MilReq "HEV_MalfunctionIndicationLampRequest";
CM_ SG_ 613 HEV_WiperSwSta "HEV_WiperSwitchStatus";
CM_ SG_ 613 HEV_FanOpSta "HEV_CoolingFanOperatingStatus";
CM_ SG_ 613 HEV_FanSta "HEV_CoolingFanStatus";
CM_ SG_ 613 HEV_BrkLtSwSta "HEV_BrakeLightSwitchStatus";
CM_ SG_ 613 HEV_IgnCycCntVal "HEV_IgnitionCycleCounterValue";
CM_ SG_ 613 HEV_SoakTimeVal "HEV_SoakTimeValue";
CM_ SG_ 613 HEV_SoakTimeErrSta "HEV_SoakTimeErrorStatus";
CM_ SG_ 613 HEV_SoakTimeOvrSta "HEV_SoakTimeOverStatus";
CM_ SG_ 613 HEV_FuelRunOutSta "HEV_FuelRunOutStatus";
CM_ SG_ 613 HEV_FuelRunOutDetSta "HEV_FuelRunOutDetectStatus";
CM_ SG_ 613 HEV_FuelCnsmptSumVal "HEV_FuelConsumptionSumValue";
CM_ BO_ 1024 "[PE] Periodic and On Event";
CM_ SG_ 1024 BVM_ViewMode "BVM View Mode";
CM_ SG_ 1024 SVM_CamConfgSta "SVM_CameraConfigurationStatus";
CM_ SG_ 1024 SVM_OperatSta "SVM_OperatSta";
CM_ SG_ 1024 BVM_View2Sta "BVM View 2 State";
CM_ SG_ 1024 ADAS_PRK_ResetOpsta "This signal indicates whether the reset operation has been completed or not";
CM_ BO_ 1026 "[PE] Periodic and On Event";
CM_ SG_ 1026 BDC_FD_SMK_Crc3Val "BDC_FD_SMK_CyclicRedundancyCheck3Value";
CM_ SG_ 1026 SMK_TrmnlCtrlStaBDCEV "SMK_TerminalControlStatus";
CM_ SG_ 1026 SMK_PwrTransitionReq "SMK Power Transition Request";
CM_ SG_ 1026 SMK_VhclSlpSta "This Signal is used to calculate slope of the vehicle and to determine whether vehicle is in inclined condition or vehicle is in flat(inclination within the limits) condition for remote start operation (2nd CAN - C_VehicleSlopeState)";
CM_ SG_ 1026 SMK_EVPwrOffReq "EV Power Off Request";
CM_ SG_ 1026 SMK_MaintenanceSrvMdReq "Maintenance Service mode request from BDC to VCU";
CM_ SG_ 1026 Warn_DisWrngSta3 "SMK Warnng Display signal";
CM_ SG_ 1026 SMK_CCUOTACrankInhState "This signal is state of Cranking Inhibit for CCUOTA";
CM_ SG_ 1026 SMK_NParkModePwrOFFResult "N Parking Mode Cancel Request(SMK→VCU)";
CM_ SG_ 1026 SMK_TwoPressStrtSta "progress state by two brake inputs start";
CM_ SG_ 1026 SMK_PwrOffDspBtnActvSta "This is activation of screen soft key for Power Off";
CM_ SG_ 1026 SMK_GetOffPopUpReq "This signal is used to request a pop-up for convenience when exiting the vehicle.";
CM_ SG_ 1026 SMK_PwrOffHardBtnPopupReq "This signal is used to separate the parking popup or driving popup when the power off hard key is pressed.";
CM_ SG_ 1026 SMK_EVRdyOffReq "This signal is used to request for READY → Power On";
CM_ SG_ 1026 SMK_NTowMdAuthFailSta "This is status about Authentication fail by N Tower Mode";
CM_ SG_ 1026 SMK_SftyMdExitOKSta "This signal is showed information that customer selected OK button to exit Safety Mode.";
CM_ SG_ 1026 SMK_SftyMdPopup "This signal is used to following Scenario 1) To check Safety Mode Exit, 2) Brake Pedal is pushed during Safety Mode, 3) EV is startable.";
CM_ SG_ 1026 BDC_FD_SMK_AlvCnt3Val "BDC_FD_SMK_AliveCounter3Value";
CM_ SG_ 1026 ESCL_EsclMngrSta "ESCL_EsclManagerStatus ##2G##SMK - SMKmsg19 - C_EsclManagerState";
CM_ SG_ 1026 ESCL_EsclPwrSupSta "ESCL_EsclPowerSupplyStatus ##2G##SMK - SMKmsg19 - C_EsclPowerSupplystatus";
CM_ SG_ 1026 ESCL_EsclEnaSta "ESCL_EsclEnableStatus ##2G##SMK - SMKmsg19 - C_EsclEnableStatus";
CM_ SG_ 1026 ESCL_EsclUnitSta "ESCL_EsclUnitStatus ##2G##SMK - SMKmsg19 - C_EsclUnitStatus";
CM_ SG_ 1026 ESCL_EsclBoltSta "ESCL_EsclBoltStatus ##2G##SMK - SMKmsg19 - C_EsclBoltStatus";
CM_ SG_ 1026 ESCL_EsclLoBattSta "ESCL_EsclLowBatteryStatus ##2G##SMK - SMKmsg19 - C_EsclLowBat";
CM_ SG_ 1026 ESCL_EsclUnLkSwSta "ESCL_UnLockSwitchStatus ##2G##SMK - SMKmsg19 - C_EsclUnlock";
CM_ SG_ 1026 Warn_StrtStpBtnWrngSta "Warn_StartStopButtonWarningStatus ##2G##SMK - SMKmsg17 - C_SSBWarn";
CM_ SG_ 1026 Warn_DeActvWrngSta "Warn_DeActivationWarningStatus ##2G##SMK - SMKmsg17 - C_DeactivationWarn";
CM_ SG_ 1026 Warn_GearPosPWrngReq "Warn_GearPositionPWarningRequest ##2G##SMK - SMKmsg17 - C_ShiftPWarn";
CM_ SG_ 1026 Warn_ExtrnlBuzWrngSta "Warn_ExternalBuzzelWarningStatus ##2G##SMK - SMKmsg17 - C_SMKExtBuzWarn";
CM_ SG_ 1026 Warn_IdOutWrngSta "Warn_IdOutWarningStatus ##2G##SMK - SMKmsg17 - C_IDoutWarn";
CM_ SG_ 1026 Warn_KeyBattLoWrngSta "Warn_KeyBatteryLowWarningStatus ##2G##SMK - SMKmsg17 - C_KeyBATDischargeWarn";
CM_ SG_ 1026 Warn_KeyOutLmpOnReq "Warn_KeyOutLampOnRequest ##2G##SMK - SMKmsg17 - C_KeyoutLp";
CM_ SG_ 1026 Warn_NotGearPosPWrngSta "Warn_NotGearPositionPWarningStatus ##2G##SMK - SMKmsg17 - C_VehicleNotPWarn";
CM_ SG_ 1026 Warn_EsclFlWrngSta "Warn_EsclFailWarningStatus ##2G##SMK - SMKmsg17 - C_ESCLFailWarn";
CM_ SG_ 1026 Warn_EsclNotLkWrngSta "Warn_EsclNotLockWarningStatus ##2G##SMK - SMKmsg17 - C_ESCLNotLockedWarn";
CM_ SG_ 1026 Warn_EsclNotUnLkWrngSta "Warn_EsclNotUnLockWarningStatus ##2G##SMK - SMKmsg17 - C_ESCLNotUnlockWarn";
CM_ SG_ 1026 Warn_ImmoLmpOnReq "Warn_ImmobilizerLampOnRequest ##2G##SMK - SMKmsg17 - C_ImmoLp";
CM_ SG_ 1026 Warn_DisWrngSta2 "Request to SMK Display warning on CLU ##2G ## SMK - SMKmsg17 - C_SMKDispWarn2";
CM_ SG_ 1026 Warn_DisWrngSta "Warn_DisplayWarningStatus ##2G##SMK - SMKmsg17 - C_SMKDispWarn";
CM_ SG_ 1026 SMKFOBID_CHNAVNT "SMK FOB ID information for china AVNT personalization function##2G##SMK-SMKmsg17-C_SMKFobID_CHNAVNT";
CM_ SG_ 1026 SMK_TrmnlCtrlGrpStaBDC "SMK_TerminalControlStatus";
CM_ SG_ 1026 SMK_TrmnlCtrlGrpStaBDCEV "SMK_TerminalControlStatus";
CM_ SG_ 1026 SMK_TrmnlCtrlStaBDC "SMK_TerminalControlStatus";
CM_ BO_ 193 "[EC] On Event and On Change";
CM_ SG_ 193 BLTN_CAM_FD_Crc1Val "BLTN_CAM_FD_CyclicRedundancyCheck1Value";
CM_ SG_ 193 BLTN_CAM_FD_AlvCnt1Val "BLTN_CAM_FD_AliveCounter1Value";
CM_ SG_ 193 BLTN_CAM_UI_Mode_Tmt_Req "Built-in Cam UI Mode terminate request.";
CM_ SG_ 193 BLTN_CAM_PopUp_Req "Built-in Cam Operating and SD Card related Popup Request on HU Display.";
CM_ SG_ 193 BLTN_CAM_File_List_Renew "The Storage information is renewed inform to HU.";
CM_ SG_ 193 BLTN_CAM_Wifi_Pwd_Chg_State "The Response, when HU change Wifi Passowrd via SOME/IP";
CM_ SG_ 193 BLTN_CAM_Dis_Touch_BeepSound "Display Touch Beep Sound of valid space touch.";
CM_ BO_ 345 "[P] Periodic";
CM_ SG_ 345 LBM_FD_Crc2Val "LBM_FD_CyclicRedundancyCheck2Value";
CM_ SG_ 345 MainLBM_NormalPwrVal "Main Lithium Battery Normal Power Value";
CM_ SG_ 345 MainLBM_NormalWhVal "Main Lithium Battery Normal Watt Hour Value";
CM_ SG_ 345 MainLBM_NormalReserveTimeVal "Main Lithium Battery Normal Reserved Time Value(Over 1A)";
CM_ SG_ 345 LBM_FD_AlvCnt2Val "LBM_FD_AliveCounter2Value";
CM_ SG_ 345 MainLBM_SleepReserveTimeVal "Main Lithium Battery Sleep Reserved Time Value(Below 1A)";
CM_ SG_ 345 MainLBM_CurrVal "Main Lithium Battery Current";
CM_ SG_ 345 MainLBM_SocVal "Main Lithium Battery Stage Of Charge";
CM_ SG_ 345 MainLBM_VtgVal "Main Lithium Battery Module Voltage";
CM_ SG_ 345 MainLBM_TempVal "Main Lithium Battery Module Temperature";
CM_ SG_ 345 MainLBM_SocErrSta "Main Lithium Battery Soc Error State";
CM_ SG_ 345 MainLBM_SohVal "Main Lithium Battery State Of Health";
CM_ SG_ 345 MainLBM_SnsrInvldSta "Main Lithium Battery Sensor Invalid Status";
CM_ SG_ 345 MainLBM_RspErrSta "Main Lithium Battery Response Error Status";
CM_ SG_ 345 MainLBM_CapacityVal "Battery Capacity Value";
CM_ SG_ 345 MainLBM_SohErrSta "It consists of bits to inform whether the current battery state extraction values are reliable and bits to inform the generation of dark currents at a level that needs to be checked.";
CM_ SG_ 345 MainLBM_PeakLoadPwrVal "Main Lithium Battery Peak Load Power Value";
CM_ BO_ 74 "[P] Periodic";
CM_ SG_ 74 IMU_Crc1Val "IMU_CyclicRedundancyCheck1Value";
CM_ SG_ 74 IMU_SnsrTempVal "IMU_SensorTemperatureValue ##2G##YRS - YRS12 - YRS_Temp";
CM_ SG_ 74 IMU_SeralNumVal "IMU_SerialNumberValue ##2G##YRS - YRS13 - YRS_SeralNo";
CM_ SG_ 74 IMU_AlvCnt1Val "IMU_AliveCounter1Value";
CM_ SG_ 74 IMU_RollRtVal "IMU_Roll rate signal value";
CM_ SG_ 74 IMU_VerAccelVal "IMU_Vertial Acceleration value";
CM_ SG_ 74 IMU_PitchRtVal "IMU_PitchRateValue";
CM_ SG_ 74 IMU_YawSigSta "IMU_YawSignalStatus ##2G##YRS - YRS11 - CF_Yrs_YrStat";
CM_ SG_ 74 IMU_LatAccelSigSta "IMU_LateralAccelerationSignalStatus ##2G##YRS - YRS11 - CF_Yrs_LatAcStat";
CM_ SG_ 74 IMU_LongAccelSigSta "IMU_LongitudinalAccelerationSignalStatus ##2G##YRS - YRS12 - CF_Yrs_LongAcStat";
CM_ SG_ 74 IMU_VerAccelSigSta "IMU_Vertial Acceleration Signal Status";
CM_ SG_ 74 IMU_McuVoltSta "IMU_McuVoltageStatus ##2G##YRS - YRS11 - CF_Yrs_MCUStat";
CM_ SG_ 74 IMU_AcuRstSta "IMU_AcuResetStatus ##2G##YRS - YRS12 - CF_IMU_ResetStat";
CM_ SG_ 74 IMU_SnsrTyp "IMU SensorType (Axis information)##2G##YRS - YRS12 - CF_Yrs_Type";
CM_ SG_ 74 IMU_RollSigSta "IMU Rollrate signal status";
CM_ SG_ 74 IMU_PitchSigSta "IMU_PitchSignalStatus";
CM_ SG_ 74 IMU_YawRtVal "IMU_YawRateValue ##2G##YRS - YRS11 - CR_Yrs_Yr";
CM_ SG_ 74 IMU_LatAccelVal "IMU_LateralAccelerationValue ##2G##YRS - YRS11 - CR_Yrs_LatAc";
CM_ SG_ 74 IMU_LongAccelVal "IMU_LongitudinalAccelerationValue ##2G##YRS - YRS12 - CR_Yrs_LongAc";
CM_ BO_ 194 "[EW] On Event and On Write";
CM_ SG_ 194 BMS_FD_Crc1Val "BMS_FD_CyclicRedundancyCheck1Value";
CM_ SG_ 194 BMS_FD_AlvCnt1Val "BMS_FD_AliveCounter1Value";
CM_ SG_ 194 xEV_BMS_WakeUpReqfor12V "BMS-PDC/ICU Wake Up, PLBM Discharge Reqest Signal for12V Li-thium Battery";
CM_ SG_ 194 xEV_AuxBattChrgReq_HS "(12V Lithium Battery) Aux. Battery Charge Request Flag (HS-CAN)";
CM_ SG_ 194 xEV_12VBatAlarmReq_HS "BMS-PDC/ICU 3rd Cut-off, Alarm Request for12V Li-thium Battery";
CM_ SG_ 194 BMS_ResetWakeup "All vehicle controller reset functions (12V LFP BMS controller only)";
CM_ BO_ 1048 "[P] Periodic";
CM_ SG_ 1048 GNSS_Crc6Val "GNSS_CyclicRedundancyCheck6Value";
CM_ SG_ 1048 HU_MM_Altitude "Mapmatching Altitude";
CM_ SG_ 1048 GNSS_AlvCnt6Val "GNSS_AliveCounter6Value";
CM_ SG_ 1048 HU_MM_Heading "Map matching heading";
CM_ SG_ 1048 GNSS_MM_type "Map matching type info.";
CM_ SG_ 1048 HU_MM_Latitude "Map matching Latitude";
CM_ SG_ 1048 HU_MM_Longitude "Mapmatching Longitude";
CM_ BO_ 1051 "[PE] Periodic and On Event";
CM_ SG_ 1051 HU_CLOCK_Crc1Val "HU_CLOCK_CyclicRedundancyCheck1Value";
CM_ SG_ 1051 HU_DisplayYear1 "Information for Year (XXOO)
XX : HU_DisplayYear1
OO: HU_DisplayYear2";
CM_ SG_ 1051 HU_DisplayYear2 "Information for Year (XXOO)
XX : HU_DisplayYear1
OO: HU_DisplayYear2";
CM_ SG_ 1051 HU_DisplayDay "Information for Day";
CM_ SG_ 1051 HU_AM_PM_INFO "Information for AM/PM";
CM_ SG_ 1051 HU_CLOCK_AlvCnt1Val "HU_CLOCK_AliveCounter1Value";
CM_ SG_ 1051 HU_TimeSetting "Information for current time setting";
CM_ SG_ 1051 HU_Status "Information for H/U status
Transmitted on H/U status changing";
CM_ SG_ 1051 HU_TimeFormat "Information for time format
Digital CLOCK only";
CM_ SG_ 1051 HU_DisplayHour "Information for time display in Hour unit";
CM_ SG_ 1051 HU_DisplayMinute "Information for time display in Minute unit";
CM_ SG_ 1051 HU_DisplaySecond "Information for time display in Second unit";
CM_ SG_ 1051 HU_DisplayMonth "Information for Month";
CM_ BO_ 1052 "[PE] Periodic and On Event";
CM_ SG_ 1052 HU_CLU_Crc2Val "HU_CLU_CyclicRedundancyCheck2Value";
CM_ SG_ 1052 HU_EVSupport "Notification whether EV function support or not.";
CM_ SG_ 1052 HU_AutoBrightState_New "HU Display Brightness State(When automatically adjusted)";
CM_ SG_ 1052 HU_CLU_AlvCnt2Val "HU_CLU_AliveCounter2Value";
CM_ SG_ 1052 HU_OffloadBtnReq "Request to switch to off-road page";
CM_ SG_ 1052 HU_LanguageInfo "Information for System Language (for Display Font)";
CM_ SG_ 1052 HU_MuteStatus "Information for System Mute Display";
CM_ SG_ 1052 HU_WelcomeReady "H/U playback ready signal to play welcome/goodbye animation video.";
CM_ SG_ 1052 HU_UsmSupport "Information whether HU can support USM or not";
CM_ SG_ 1052 HU_NaviStatus "Information for Navigation Status (Booting, Normal Operation, No SD card)
-AVN NAVI Transmission Signal";
CM_ SG_ 1052 HU_NaviDisp "Information for Navi Display status on Front Monitor";
CM_ SG_ 1052 HU_BVM_Display_Message "BVM Operation Message";
CM_ SG_ 1052 HU_NaviCamSettingStatus "Information for Navi Camera alert setting status

+ Bit-coded field (On 1, Off 0)
   - bit 0 : Fixed Camera
   - bit 1 : Signal/Speed Violation Camera
   - bit 2 : Movable Camera
   - bit 3 : User Registration Fixed Camera
   - bit 4 : User Registration Signal/Speed Violation Camera
   - bit 5~6 : RESERVED
-AVN NAVI Transmission Signal";
BA_DEF_ BO_  "GenMsgEVName" STRING ;
BA_DEF_ BO_  "NmAsrMessage" ENUM  "No","Yes";
BA_DEF_ BO_  "DiagState" ENUM  "No","Yes";
BA_DEF_ BO_  "DiagRequest" ENUM  "No","Yes";
BA_DEF_ BO_  "TpMessage" ENUM  "No","Yes";
BA_DEF_ BO_  "UsrMsgIDSforwardDeviation" INT 0 100;
BA_DEF_ BO_  "UsrMsgIDSbackwardDeviation" INT 50 1000;
BA_DEF_ BO_  "GenMsgCycleTime" INT 0 2000;
BA_DEF_ BO_  "GenMsgStartDelayTime" INT 0 2000;
BA_DEF_ BO_  "GenMsgSendType" ENUM  "Cyclic","NoMsgSendType";
BA_DEF_ BO_  "GenMsgCycleTimeFast" INT 0 500;
BA_DEF_ BO_  "GenMsgDelayTime" INT 0 20;
BA_DEF_ BO_  "GenMsgILSupport" ENUM  "No","Yes";
BA_DEF_ BO_  "GenMsgNrOfRepetition" INT 0 3;
BA_DEF_ BO_  "VFrameFormat" ENUM  "StandardCAN","ExtendedCAN","reserved","reserved","reserved","reserved","reserved","reserved","reserved","reserved","reserved","reserved","reserved","reserved","StandardCAN_FD","ExtendedCAN_FD";
BA_DEF_ SG_  "UserSigValidity" ENUM  "B+","ACC","IG","IG1","IG2","IG3","IG1 or IG2","IG1 or IG3","Undef";
BA_DEF_ SG_  "TimeoutValue" STRING ;
BA_DEF_ SG_  "UsrSigPurpose" ENUM  "Undef","FN","DIAG","DIAG(Req)","DIAG(Res)","DIAG(Func)","DEV","CCP","NM","TP";
BA_DEF_ SG_  "GenSigStartValue" INT 0 1215752192;
BA_DEF_ SG_  "NetworkRequest" ENUM  "Yes","No";
BA_DEF_ SG_  "NetworkRequestHoldingTime" INT 0 65535;
BA_DEF_ SG_  "Description" STRING ;
BA_DEF_ SG_  "Version" STRING ;
BA_DEF_ SG_  "GenSigEnvVarType" ENUM  "Int","Float","Undef";
BA_DEF_ SG_  "GenSigSendType" ENUM  "Cyclic","OnWrite","OnWriteWithRepetition","OnChange","OnChangeWithRepetition","IfActive","IfActiveWithRepetition","NoSigSendType","OnChangeAndIfActive","OnChangeAndIfActiveWithRepetition";
BA_DEF_ SG_  "GwSigLatencyTime" INT 0 65536;
BA_DEF_ SG_  "GwSigMissingSourceType" ENUM  "Undef","OldValue","DefaultValue","InitialValue";
BA_DEF_ SG_  "NWM-WakeupAllowed" ENUM  "<n.a.>";
BA_DEF_ SG_  "RoutingFactor" INT 1 1215752192;
BA_DEF_ SG_  "SystemSignalLongSymbol" STRING ;
BA_DEF_REL_ BU_SG_REL_  "GenSigTimeoutTime" INT 0 7000;
BA_DEF_DEF_  "GenMsgEVName" "@Signame";
BA_DEF_DEF_  "NmAsrMessage" "No";
BA_DEF_DEF_  "DiagState" "No";
BA_DEF_DEF_  "DiagRequest" "No";
BA_DEF_DEF_  "TpMessage" "No";
BA_DEF_DEF_  "UsrMsgIDSforwardDeviation" 10;
BA_DEF_DEF_  "UsrMsgIDSbackwardDeviation" 100;
BA_DEF_DEF_  "GenMsgCycleTime" 200;
BA_DEF_DEF_  "GenMsgStartDelayTime" 0;
BA_DEF_DEF_  "GenMsgSendType" "NoMsgSendType";
BA_DEF_DEF_  "GenMsgCycleTimeFast" 40;
BA_DEF_DEF_  "GenMsgDelayTime" 20;
BA_DEF_DEF_  "GenMsgILSupport" "Yes";
BA_DEF_DEF_  "GenMsgNrOfRepetition" 3;
BA_DEF_DEF_  "VFrameFormat" "StandardCAN";
BA_DEF_DEF_  "UserSigValidity" "IG";
BA_DEF_DEF_  "TimeoutValue" "";
BA_DEF_DEF_  "UsrSigPurpose" "FN";
BA_DEF_DEF_  "GenSigStartValue" 0;
BA_DEF_DEF_  "NetworkRequest" "No";
BA_DEF_DEF_  "NetworkRequestHoldingTime" 0;
BA_DEF_DEF_  "Description" "";
BA_DEF_DEF_  "Version" "";
BA_DEF_DEF_  "GenSigEnvVarType" "Undef";
BA_DEF_DEF_  "GenSigSendType" "NoSigSendType";
BA_DEF_DEF_  "GwSigLatencyTime" 40;
BA_DEF_DEF_  "GwSigMissingSourceType" "Undef";
BA_DEF_DEF_  "NWM-WakeupAllowed" "<n.a.>";
BA_DEF_DEF_  "RoutingFactor" 1;
BA_DEF_DEF_REL_ "GenSigTimeoutTime" 500;
BA_DEF_DEF_  "SystemSignalLongSymbol" "";
BA_ "GenMsgCycleTime" BO_ 745 300;
BA_ "GenMsgSendType" BO_ 745 0;
BA_ "VFrameFormat" BO_ 745 14;
BA_ "GenMsgNrOfRepetition" BO_ 64 0;
BA_ "GenMsgCycleTimeFast" BO_ 64 0;
BA_ "GenMsgCycleTime" BO_ 64 50;
BA_ "GenMsgSendType" BO_ 64 0;
BA_ "VFrameFormat" BO_ 64 14;
BA_ "GenMsgCycleTime" BO_ 1308 0;
BA_ "VFrameFormat" BO_ 1308 14;
BA_ "GenMsgNrOfRepetition" BO_ 613 0;
BA_ "GenMsgCycleTimeFast" BO_ 613 0;
BA_ "GenMsgSendType" BO_ 613 0;
BA_ "VFrameFormat" BO_ 613 14;
BA_ "GenMsgSendType" BO_ 1024 0;
BA_ "VFrameFormat" BO_ 1024 14;
BA_ "GenMsgStartDelayTime" BO_ 1026 30;
BA_ "GenMsgSendType" BO_ 1026 0;
BA_ "VFrameFormat" BO_ 1026 14;
BA_ "GenMsgCycleTime" BO_ 193 0;
BA_ "VFrameFormat" BO_ 193 14;
BA_ "GenMsgNrOfRepetition" BO_ 345 0;
BA_ "GenMsgCycleTimeFast" BO_ 345 0;
BA_ "GenMsgCycleTime" BO_ 345 300;
BA_ "GenMsgSendType" BO_ 345 0;
BA_ "VFrameFormat" BO_ 345 14;
BA_ "GenMsgNrOfRepetition" BO_ 74 0;
BA_ "GenMsgCycleTimeFast" BO_ 74 0;
BA_ "GenMsgCycleTime" BO_ 74 50;
BA_ "GenMsgSendType" BO_ 74 0;
BA_ "VFrameFormat" BO_ 74 14;
BA_ "GenMsgDelayTime" BO_ 194 10;
BA_ "GenMsgNrOfRepetition" BO_ 194 0;
BA_ "GenMsgCycleTime" BO_ 194 0;
BA_ "VFrameFormat" BO_ 194 14;
BA_ "GenMsgNrOfRepetition" BO_ 1048 0;
BA_ "GenMsgCycleTimeFast" BO_ 1048 0;
BA_ "GenMsgCycleTime" BO_ 1048 1000;
BA_ "GenMsgSendType" BO_ 1048 0;
BA_ "VFrameFormat" BO_ 1048 14;
BA_ "GenMsgStartDelayTime" BO_ 1051 10;
BA_ "GenMsgCycleTime" BO_ 1051 1000;
BA_ "GenMsgSendType" BO_ 1051 0;
BA_ "VFrameFormat" BO_ 1051 14;
BA_ "GenMsgStartDelayTime" BO_ 1052 10;
BA_ "GenMsgCycleTime" BO_ 1052 1000;
BA_ "GenMsgSendType" BO_ 1052 0;
BA_ "VFrameFormat" BO_ 1052 14;
BA_ "Version" SG_ 745 PDC_FD_Crc15Val "24.04.08";
BA_ "UserSigValidity" SG_ 745 PDC_FD_Crc15Val 3;
BA_ "GenSigStartValue" SG_ 745 PDC_FD_Crc15Val 65535;
BA_ "GenSigSendType" SG_ 745 PDC_FD_Crc15Val 4;
BA_ "Description" SG_ 745 PDC_FD_Crc15Val "The data area for CRC calculation is based on the data length (DLC) of the message DB.

The CRC shall be calculated over the entire data block (excluding the CRC bytes) including the user data, alive counter and Data ID



- CRC Polynomial (0x1021) , Ini";
BA_ "Version" SG_ 745 PDC_CurrAtReset "24.07.06";
BA_ "UserSigValidity" SG_ 745 PDC_CurrAtReset 0;
BA_ "GenSigSendType" SG_ 745 PDC_CurrAtReset 4;
BA_ "Description" SG_ 745 PDC_CurrAtReset "This signal indicate the current at reset request";
BA_ "Version" SG_ 745 PDC_AvgCurrAtReset "24.07.06";
BA_ "UserSigValidity" SG_ 745 PDC_AvgCurrAtReset 0;
BA_ "GenSigSendType" SG_ 745 PDC_AvgCurrAtReset 4;
BA_ "Description" SG_ 745 PDC_AvgCurrAtReset "This signal indicate the average current at reset request";
BA_ "Version" SG_ 745 PDC_ResetReason "24.07.06";
BA_ "UserSigValidity" SG_ 745 PDC_ResetReason 0;
BA_ "GenSigSendType" SG_ 745 PDC_ResetReason 4;
BA_ "Description" SG_ 745 PDC_ResetReason "This signal indicate the reason reset is operated";
BA_ "Version" SG_ 745 PDC_CumulativeCountOf12VReq "24.07.06";
BA_ "UserSigValidity" SG_ 745 PDC_CumulativeCountOf12VReq 0;
BA_ "GenSigSendType" SG_ 745 PDC_CumulativeCountOf12VReq 4;
BA_ "Description" SG_ 745 PDC_CumulativeCountOf12VReq "This signal indicates the cumulative number of 12V Controller req.";
BA_ "Version" SG_ 745 PDC_CumulativeCountOfCCUReq "24.07.06";
BA_ "UserSigValidity" SG_ 745 PDC_CumulativeCountOfCCUReq 0;
BA_ "GenSigSendType" SG_ 745 PDC_CumulativeCountOfCCUReq 4;
BA_ "Description" SG_ 745 PDC_CumulativeCountOfCCUReq "This signal indicates the cumulative number of CCU_ForcedPowerOffReq";
BA_ "Version" SG_ 745 PDC_VehCondiForReset "25.07.02";
BA_ "UserSigValidity" SG_ 745 PDC_VehCondiForReset 0;
BA_ "GenSigSendType" SG_ 745 PDC_VehCondiForReset 4;
BA_ "Description" SG_ 745 PDC_VehCondiForReset "This signal indicates whether the vehicle is in a state that allows for a reset or not.";
BA_ "Version" SG_ 745 PDC_FD_AlvCnt15Val "24.04.08";
BA_ "UserSigValidity" SG_ 745 PDC_FD_AlvCnt15Val 3;
BA_ "GenSigSendType" SG_ 745 PDC_FD_AlvCnt15Val 4;
BA_ "Description" SG_ 745 PDC_FD_AlvCnt15Val "For the first transmission request for a data element the counter shall be initialized with 0 and shall be incremented by 1 for every subsequent send request. 

When the counter reaches the maximum value(0xFF), then it shall restart with 0 for the next s";
BA_ "Version" SG_ 745 PDC_LDConReq "24.07.05";
BA_ "UserSigValidity" SG_ 745 PDC_LDConReq 0;
BA_ "GenSigSendType" SG_ 745 PDC_LDConReq 4;
BA_ "Description" SG_ 745 PDC_LDConReq "LDC on request signal for High Voltage Battery Discharge";
BA_ "Version" SG_ 745 PDC_LDConReq_By_LVBat "24.07.05";
BA_ "UserSigValidity" SG_ 745 PDC_LDConReq_By_LVBat 0;
BA_ "GenSigSendType" SG_ 745 PDC_LDConReq_By_LVBat 4;
BA_ "Description" SG_ 745 PDC_LDConReq_By_LVBat "LDC on request signal for High Voltage Battery Discharge by Low Voltage Battery";
BA_ "Version" SG_ 745 PDC_LDConReq_By_OTA "24.07.05";
BA_ "UserSigValidity" SG_ 745 PDC_LDConReq_By_OTA 0;
BA_ "GenSigSendType" SG_ 745 PDC_LDConReq_By_OTA 4;
BA_ "Description" SG_ 745 PDC_LDConReq_By_OTA "LDC on request signal for High Voltage Battery Discharge by OTA";
BA_ "Version" SG_ 745 PDC_LDConReq_By_Load "24.07.05";
BA_ "UserSigValidity" SG_ 745 PDC_LDConReq_By_Load 0;
BA_ "GenSigSendType" SG_ 745 PDC_LDConReq_By_Load 4;
BA_ "Description" SG_ 745 PDC_LDConReq_By_Load "LDC on request signal for High Voltage Battery Discharge by Load";
BA_ "Version" SG_ 745 PDC_LDConReq_By_ActiveOn "24.07.05";
BA_ "UserSigValidity" SG_ 745 PDC_LDConReq_By_ActiveOn 0;
BA_ "GenSigSendType" SG_ 745 PDC_LDConReq_By_ActiveOn 4;
BA_ "Description" SG_ 745 PDC_LDConReq_By_ActiveOn "LDC on request signal for High Voltage Battery Discharge by Active On";
BA_ "Version" SG_ 745 PDC_ResetPreWrngForCCU "24.05.05";
BA_ "UserSigValidity" SG_ 745 PDC_ResetPreWrngForCCU 0;
BA_ "GenSigSendType" SG_ 745 PDC_ResetPreWrngForCCU 4;
BA_ "Description" SG_ 745 PDC_ResetPreWrngForCCU "This is a warning signal for reset.  This signal is used for preparing sideeffect of reset by Gateway";
BA_ "Version" SG_ 745 PDC_ResetPreWrngForOthers "24.05.05";
BA_ "UserSigValidity" SG_ 745 PDC_ResetPreWrngForOthers 0;
BA_ "GenSigSendType" SG_ 745 PDC_ResetPreWrngForOthers 4;
BA_ "Description" SG_ 745 PDC_ResetPreWrngForOthers "This is a warning signal for reset.  This signal is used for preparing sideeffect of reset by Receivers";
BA_ "Version" SG_ 745 PDC_ResetReqForCCU "24.05.05";
BA_ "UserSigValidity" SG_ 745 PDC_ResetReqForCCU 0;
BA_ "GenSigSendType" SG_ 745 PDC_ResetReqForCCU 4;
BA_ "Description" SG_ 745 PDC_ResetReqForCCU "This is a request signal for SW reset of Gateway";
BA_ "Version" SG_ 745 PDC_ResetReqForOthers "24.05.05";
BA_ "UserSigValidity" SG_ 745 PDC_ResetReqForOthers 0;
BA_ "GenSigSendType" SG_ 745 PDC_ResetReqForOthers 4;
BA_ "Description" SG_ 745 PDC_ResetReqForOthers "This is a request signal for SW reset except for Gateway";
BA_ "Version" SG_ 745 PDC_ResetFuncOpt "24.05.05";
BA_ "UserSigValidity" SG_ 745 PDC_ResetFuncOpt 0;
BA_ "GenSigSendType" SG_ 745 PDC_ResetFuncOpt 4;
BA_ "Description" SG_ 745 PDC_ResetFuncOpt "This signal inform whether reset fucntion at PDC is appiled or not";
BA_ "Version" SG_ 745 PDC_12VRlyCtrl "24.05.05";
BA_ "UserSigValidity" SG_ 745 PDC_12VRlyCtrl 0;
BA_ "GenSigSendType" SG_ 745 PDC_12VRlyCtrl 4;
BA_ "Description" SG_ 745 PDC_12VRlyCtrl "This signal is request signal to control 12V battery internal relay for HW reset";
BA_ "Version" SG_ 745 PDC_CurrentValueForReset "24.07.03";
BA_ "UserSigValidity" SG_ 745 PDC_CurrentValueForReset 0;
BA_ "GenSigSendType" SG_ 745 PDC_CurrentValueForReset 4;
BA_ "Description" SG_ 745 PDC_CurrentValueForReset "This signal sets the average discharge current value to be measured for PDC_TimevalueForReset to be considered as a situation requiring reset.";
BA_ "Version" SG_ 745 PDC_WakeUpReqForReset "25.01.00";
BA_ "UserSigValidity" SG_ 745 PDC_WakeUpReqForReset 0;
BA_ "GenSigSendType" SG_ 745 PDC_WakeUpReqForReset 4;
BA_ "Description" SG_ 745 PDC_WakeUpReqForReset "Request to transmit controller wake-up signal for receiving reset related signal";
BA_ "Version" SG_ 745 PDC_TimeValueForReset "24.07.03";
BA_ "UserSigValidity" SG_ 745 PDC_TimeValueForReset 0;
BA_ "GenSigSendType" SG_ 745 PDC_TimeValueForReset 4;
BA_ "Description" SG_ 745 PDC_TimeValueForReset "This signal sets the time value to be considered as a situation requiring reset.";
BA_ "Version" SG_ 745 PDC_12VRlyOffHoldingTime "24.05.05";
BA_ "UserSigValidity" SG_ 745 PDC_12VRlyOffHoldingTime 0;
BA_ "GenSigSendType" SG_ 745 PDC_12VRlyOffHoldingTime 4;
BA_ "Description" SG_ 745 PDC_12VRlyOffHoldingTime "This signal sets how long the relay will be turned off when performing an HW reset using a 12 V battery internal relay.";
BA_ "Version" SG_ 745 PDC_ResetCountSetting "24.05.05";
BA_ "UserSigValidity" SG_ 745 PDC_ResetCountSetting 0;
BA_ "GenSigSendType" SG_ 745 PDC_ResetCountSetting 4;
BA_ "Description" SG_ 745 PDC_ResetCountSetting "This signal sets the number of resets performed.";
BA_ "Version" SG_ 745 PDC_ResetCount "24.05.05";
BA_ "UserSigValidity" SG_ 745 PDC_ResetCount 0;
BA_ "GenSigSendType" SG_ 745 PDC_ResetCount 4;
BA_ "Description" SG_ 745 PDC_ResetCount "This signal indicates how much reset has occurred.";
BA_ "Version" SG_ 745 PDC_ResetCumulativeCount "24.05.05";
BA_ "UserSigValidity" SG_ 745 PDC_ResetCumulativeCount 0;
BA_ "GenSigSendType" SG_ 745 PDC_ResetCumulativeCount 4;
BA_ "Description" SG_ 745 PDC_ResetCumulativeCount "This signal indicates the cumulative number of resets performed.";
BA_ "Version" SG_ 745 PDC_ResetOpsta "24.05.05";
BA_ "UserSigValidity" SG_ 745 PDC_ResetOpsta 0;
BA_ "GenSigSendType" SG_ 745 PDC_ResetOpsta 4;
BA_ "Description" SG_ 745 PDC_ResetOpsta "This signal indicates whether the reset operation has been completed or not";
BA_ "Version" SG_ 745 PDC_ReadyTimeValueForReset "24.07.06";
BA_ "UserSigValidity" SG_ 745 PDC_ReadyTimeValueForReset 0;
BA_ "GenSigSendType" SG_ 745 PDC_ReadyTimeValueForReset 4;
BA_ "Description" SG_ 745 PDC_ReadyTimeValueForReset "This signal sets the time value to be considered as a situation of quiescent current

if receiver receive the value of no setting, do not operate the logic related to this signal";
BA_ "Version" SG_ 64 TCU_Crc1Val "18.11.08";
BA_ "RoutingFactor" SG_ 64 TCU_Crc1Val 5;
BA_ "UserSigValidity" SG_ 64 TCU_Crc1Val 3;
BA_ "GenSigStartValue" SG_ 64 TCU_Crc1Val 65535;
BA_ "Description" SG_ 64 TCU_Crc1Val "The data area for CRC calculation is based on the data length (DLC) of the message DB.

The CRC shall be calculated over the entire data block (excluding the CRC bytes) including the user data, alive counter and Data ID

 

- CRC Polynomial (0x1021) , In";
BA_ "Version" SG_ 64 TCU_DcmlVehSpdKphVal "17.11.00";
BA_ "RoutingFactor" SG_ 64 TCU_DcmlVehSpdKphVal 5;
BA_ "UserSigValidity" SG_ 64 TCU_DcmlVehSpdKphVal 3;
BA_ "Description" SG_ 64 TCU_DcmlVehSpdKphVal "The signal VS_TCU_DECIAMAL means the value which is below decimal point of the vehicle speed.

For instance, if a vehicle speed is 13.75Km/h, VS_TCU means 13Km/h and VS_TCU_DECIMAL means 0.75Km/h.



Example)   VS_TCU = 13,  VS_TCU_DECIAMAL  = 96

Vehicl";
BA_ "Version" SG_ 64 TCU_SprkRtrdReq "17.11.00";
BA_ "RoutingFactor" SG_ 64 TCU_SprkRtrdReq 5;
BA_ "UserSigValidity" SG_ 64 TCU_SprkRtrdReq 3;
BA_ "GenSigStartValue" SG_ 64 TCU_SprkRtrdReq 255;
BA_ "Description" SG_ 64 TCU_SprkRtrdReq "The TCU requests a spark angle retard via the signal SPK_RTD_TCU to the EMS for torque reduction during the gear engage condition.



(PH) = ((HEX) - 3FH) * 0.375 (Advance) (PH) = (3FH - (HEX)) * (-0.375) (Retard)

-15˚  ... 0˚= 17H .. 3FH (Retard)

0.";
BA_ "Version" SG_ 64 TCU_EngRpmDisSta "17.11.00";
BA_ "RoutingFactor" SG_ 64 TCU_EngRpmDisSta 5;
BA_ "UserSigValidity" SG_ 64 TCU_EngRpmDisSta 3;
BA_ "Description" SG_ 64 TCU_EngRpmDisSta "Flag for Engine RPM(from TCU) Display on Cluster, Only when this flag is set to 1, Cluster shall display the Engine RPM from TCU";
BA_ "Version" SG_ 64 TCU_GearLmpBlnkngReq "17.11.00";
BA_ "RoutingFactor" SG_ 64 TCU_GearLmpBlnkngReq 5;
BA_ "UserSigValidity" SG_ 64 TCU_GearLmpBlnkngReq 3;
BA_ "Description" SG_ 64 TCU_GearLmpBlnkngReq "Cluster controls blinking of Gear lamp receiving the request signal from TCU.";
BA_ "Version" SG_ 64 TCU_FuelCutInhbtReq "17.11.00";
BA_ "RoutingFactor" SG_ 64 TCU_FuelCutInhbtReq 5;
BA_ "UserSigValidity" SG_ 64 TCU_FuelCutInhbtReq 3;
BA_ "Description" SG_ 64 TCU_FuelCutInhbtReq "During coast down shifting, EMS may cut off fuel injection and as a result, a driver can feel bad shift feeling. In this case, to enhance shift quality, TCU needs inhibition of fuel cut off control.

This signal indicates inhibition of engine fuel cut of";
BA_ "Version" SG_ 64 TCU_IdleUpReq "17.11.00";
BA_ "RoutingFactor" SG_ 64 TCU_IdleUpReq 5;
BA_ "UserSigValidity" SG_ 64 TCU_IdleUpReq 3;
BA_ "Description" SG_ 64 TCU_IdleUpReq "When ATF(Automatic Transmission Fluid) rises in high temperauture, the TCU requests engine idle RPM up via the signal IDLE_UP_TCU to the EMS for reduction of gearshift time form Neutral to Reverse.



THIS SIGNAL IS FOR “LAMBDA ENGINE” SYSTEM ONLY.";
BA_ "Version" SG_ 64 TCU_EngRpmDis "17.11.00";
BA_ "RoutingFactor" SG_ 64 TCU_EngRpmDis 5;
BA_ "UserSigValidity" SG_ 64 TCU_EngRpmDis 3;
BA_ "Description" SG_ 64 TCU_EngRpmDis "Engine RPM from TCU (Only for the display on Cluster)";
BA_ "Version" SG_ 64 TCU_SlpVal "17.11.00";
BA_ "RoutingFactor" SG_ 64 TCU_SlpVal 5;
BA_ "UserSigValidity" SG_ 64 TCU_SlpVal 3;
BA_ "GenSigStartValue" SG_ 64 TCU_SlpVal 32;
BA_ "Description" SG_ 64 TCU_SlpVal "This signal is used to avoid busy shifting during uphill driving.

It is calculated using engine torque, turbine torque and gearbox torque so on.

It has some restrictions like the following sentences

- No slope calculation during shifting, braking, 1st";
BA_ "Version" SG_ 64 TCU_EngSpdIncReq "17.11.00";
BA_ "RoutingFactor" SG_ 64 TCU_EngSpdIncReq 5;
BA_ "UserSigValidity" SG_ 64 TCU_EngSpdIncReq 3;
BA_ "Description" SG_ 64 TCU_EngSpdIncReq "This signal is a target engine speed requirement start flag signal by TCU, 

which is sent to ECU. It is synchronized to the signal engine speed increasing target speed value.";
BA_ "Version" SG_ 64 TCU_ObdSta "19.02.07";
BA_ "RoutingFactor" SG_ 64 TCU_ObdSta 5;
BA_ "UserSigValidity" SG_ 64 TCU_ObdSta 3;
BA_ "Description" SG_ 64 TCU_ObdSta "The signal TCU_OBD is used to inform the OBD master (EMS-ECU) in case a OBD relevant fault is detected. According to the OBD regulations the TCU could request MIL on. If a freeze frame request by the TCU has not been acknowledged (OBD_FRF_ACK) within 2 s";
BA_ "Version" SG_ 64 TCU_SprtyIndxSta "17.11.00";
BA_ "RoutingFactor" SG_ 64 TCU_SprtyIndxSta 5;
BA_ "UserSigValidity" SG_ 64 TCU_SprtyIndxSta 3;
BA_ "Description" SG_ 64 TCU_SprtyIndxSta "Sporty index based on the driver's driving behaviour";
BA_ "Version" SG_ 64 TCU_AlvCnt1Val "18.11.08";
BA_ "RoutingFactor" SG_ 64 TCU_AlvCnt1Val 5;
BA_ "UserSigValidity" SG_ 64 TCU_AlvCnt1Val 3;
BA_ "Description" SG_ 64 TCU_AlvCnt1Val "For the first transmission request for a data element the counter shall be initialized with 0 and shall be incremented by 1 for every subsequent send request. 

When the counter reaches the maximum value(0xFF), then it shall restart with 0 for the next s";
BA_ "Version" SG_ 64 TCU_DrvngModDis "17.11.00";
BA_ "RoutingFactor" SG_ 64 TCU_DrvngModDis 5;
BA_ "UserSigValidity" SG_ 64 TCU_DrvngModDis 3;
BA_ "Description" SG_ 64 TCU_DrvngModDis "Driving mode display by TCU";
BA_ "Version" SG_ 64 TCU_DrvngModReq "17.11.00";
BA_ "RoutingFactor" SG_ 64 TCU_DrvngModReq 5;
BA_ "UserSigValidity" SG_ 64 TCU_DrvngModReq 3;
BA_ "Description" SG_ 64 TCU_DrvngModReq "Driving mode request with Normal, Eco, Eco+, Sport, Sport+

and Snow only TCU automode is on, otherwise, inactive";
BA_ "Version" SG_ 64 TCU_SmrtShftSta "17.11.00";
BA_ "RoutingFactor" SG_ 64 TCU_SmrtShftSta 5;
BA_ "UserSigValidity" SG_ 64 TCU_SmrtShftSta 3;
BA_ "Description" SG_ 64 TCU_SmrtShftSta "Information of SmartShift";
BA_ "Version" SG_ 64 TCU_LupTrgtEngSpdVal "17.11.00";
BA_ "RoutingFactor" SG_ 64 TCU_LupTrgtEngSpdVal 5;
BA_ "UserSigValidity" SG_ 64 TCU_LupTrgtEngSpdVal 3;
BA_ "GenSigStartValue" SG_ 64 TCU_LupTrgtEngSpdVal 255;
BA_ "Description" SG_ 64 TCU_LupTrgtEngSpdVal "This signal is a target engine speed requested by TCU, which is sent to ECU. 

It is intended for OFF-SLIP to be more successful in triggering fuel cut-off under more various driving conditions.";
BA_ "Version" SG_ 64 TCU_FrtStcShftSta "17.11.00";
BA_ "RoutingFactor" SG_ 64 TCU_FrtStcShftSta 5;
BA_ "UserSigValidity" SG_ 64 TCU_FrtStcShftSta 3;
BA_ "Description" SG_ 64 TCU_FrtStcShftSta "Status of fisrt static shift";
BA_ "Version" SG_ 64 TCU_IsgInhbtReq "17.11.00";
BA_ "RoutingFactor" SG_ 64 TCU_IsgInhbtReq 5;
BA_ "UserSigValidity" SG_ 64 TCU_IsgInhbtReq 3;
BA_ "Description" SG_ 64 TCU_IsgInhbtReq "TCU requests ECU to inhibit the ISG function when ISG start condition of AT is not met (oil temp is too low , AT ISG system malfunction, etc … )";
BA_ "Version" SG_ 64 TCU_CdaInhbtReq "17.11.00";
BA_ "RoutingFactor" SG_ 64 TCU_CdaInhbtReq 5;
BA_ "UserSigValidity" SG_ 64 TCU_CdaInhbtReq 3;
BA_ "Description" SG_ 64 TCU_CdaInhbtReq "TCU requests ECU to prohibit the CDA transition during gear shifting or lock-up clutch operation in the automatic transmission in order to prevent a shock on the vehicle. Without gear shifting and lock-up clutch operation, CDA transition can be performed";
BA_ "Version" SG_ 64 TCU_BrkOnReq "17.11.00";
BA_ "RoutingFactor" SG_ 64 TCU_BrkOnReq 5;
BA_ "UserSigValidity" SG_ 64 TCU_BrkOnReq 3;
BA_ "Description" SG_ 64 TCU_BrkOnReq "The TCU request the ESC to activate the Brake.

The ESC holds the Brake ON during the TCU’s Brake ON Request.";
BA_ "Version" SG_ 64 TCU_TqGrdntLimVal "17.11.00";
BA_ "RoutingFactor" SG_ 64 TCU_TqGrdntLimVal 5;
BA_ "UserSigValidity" SG_ 64 TCU_TqGrdntLimVal 3;
BA_ "Description" SG_ 64 TCU_TqGrdntLimVal "TCU requests EMS to perform the engine torque gradient limitation control with a rate of Nm per second(Nm/sec).



Downshift : The engine torque gradient limitation for downshift will be a function of pedal and shift-time. 

Upshift : The engine torque g";
BA_ "Version" SG_ 64 TCU_NetrlCtrlSta "17.11.00";
BA_ "RoutingFactor" SG_ 64 TCU_NetrlCtrlSta 5;
BA_ "UserSigValidity" SG_ 64 TCU_NetrlCtrlSta 3;
BA_ "Description" SG_ 64 TCU_NetrlCtrlSta "This signal indicates the status of Neutral Control.";
BA_ "Version" SG_ 64 TCU_ShftPtrnSta "17.11.00";
BA_ "RoutingFactor" SG_ 64 TCU_ShftPtrnSta 5;
BA_ "UserSigValidity" SG_ 64 TCU_ShftPtrnSta 3;
BA_ "Description" SG_ 64 TCU_ShftPtrnSta "It is an ID of current shift pattern which is being used by TCU.

The ID is assigned for each TCU.";
BA_ "Version" SG_ 64 TCU_VgisInhbtReq "17.11.00";
BA_ "RoutingFactor" SG_ 64 TCU_VgisInhbtReq 5;
BA_ "UserSigValidity" SG_ 64 TCU_VgisInhbtReq 3;
BA_ "Description" SG_ 64 TCU_VgisInhbtReq "TCU requests ECU to inhibit the VGIS fuction from changing its status.";
BA_ "Version" SG_ 64 TCU_EngTqIncReqVal "20.03.05";
BA_ "RoutingFactor" SG_ 64 TCU_EngTqIncReqVal 5;
BA_ "UserSigValidity" SG_ 64 TCU_EngTqIncReqVal 3;
BA_ "Description" SG_ 64 TCU_EngTqIncReqVal "The TCU requests the engine torque increase via this signal to the EMS.



If MSB is 1, this signal is - value.

else, this signal is +value.

0~10bit is used for absolute value.";
BA_ "Version" SG_ 64 TCU_EPBReq "19.03.09";
BA_ "RoutingFactor" SG_ 64 TCU_EPBReq 5;
BA_ "UserSigValidity" SG_ 64 TCU_EPBReq 3;
BA_ "Description" SG_ 64 TCU_EPBReq "This is EPB Request signal for prevent P-D Shift shock on the hill";
BA_ "Version" SG_ 64 IMT_EOLstate "19.02.06";
BA_ "RoutingFactor" SG_ 64 IMT_EOLstate 5;
BA_ "UserSigValidity" SG_ 64 IMT_EOLstate 3;
BA_ "Description" SG_ 64 IMT_EOLstate "If this signal is set, Cluster should display gear info using alphabet 'E' regardless the signal 'TCU_GearSlctDis'";
BA_ "Version" SG_ 64 IMT_DisCmd "19.02.06";
BA_ "RoutingFactor" SG_ 64 IMT_DisCmd 5;
BA_ "UserSigValidity" SG_ 64 IMT_DisCmd 3;
BA_ "Description" SG_ 64 IMT_DisCmd "This signal is used for cluster to change gear display type. 

Always Display / Not Display / Blinking";
BA_ "Version" SG_ 64 IMT_CltchPdlPos "19.02.06";
BA_ "RoutingFactor" SG_ 64 IMT_CltchPdlPos 5;
BA_ "UserSigValidity" SG_ 64 IMT_CltchPdlPos 3;
BA_ "Description" SG_ 64 IMT_CltchPdlPos "Clutch Position Sensor value for 3 pedal IMT system.

This value is not supported by 2 pedal IMT system.



0% means pedal off 

99.21875% (0xFE) means pedal fully pressed

99.609375 (0xFF) means  error";
BA_ "Version" SG_ 64 DCT_RegenInhbt "18.08.02";
BA_ "RoutingFactor" SG_ 64 DCT_RegenInhbt 5;
BA_ "UserSigValidity" SG_ 64 DCT_RegenInhbt 3;
BA_ "Description" SG_ 64 DCT_RegenInhbt "The regen inhibit request from TCU.

ECU is received regen inhibit flag from TCU, then ECU is limited the regen state.";
BA_ "Version" SG_ 64 DCT_EngIdleReq "18.08.02";
BA_ "RoutingFactor" SG_ 64 DCT_EngIdleReq 5;
BA_ "UserSigValidity" SG_ 64 DCT_EngIdleReq 3;
BA_ "Description" SG_ 64 DCT_EngIdleReq "Engine Idle Request from TCU";
BA_ "Version" SG_ 64 DCT_CltchState "18.08.02";
BA_ "RoutingFactor" SG_ 64 DCT_CltchState 5;
BA_ "UserSigValidity" SG_ 64 DCT_CltchState 3;
BA_ "Description" SG_ 64 DCT_CltchState "Status of DCT clutches. This signal gives information about the frictional connection between the engine and the drive train.";
BA_ "Version" SG_ 64 DCT_FuelCutReq "18.08.02";
BA_ "RoutingFactor" SG_ 64 DCT_FuelCutReq 5;
BA_ "UserSigValidity" SG_ 64 DCT_FuelCutReq 3;
BA_ "Description" SG_ 64 DCT_FuelCutReq "Fuel Cut request bit signal to let EMS perform ‘Fuel Cut torque intervention’ during shift";
BA_ "Version" SG_ 64 DCT_TqIncReq "18.08.02";
BA_ "RoutingFactor" SG_ 64 DCT_TqIncReq 5;
BA_ "UserSigValidity" SG_ 64 DCT_TqIncReq 3;
BA_ "Description" SG_ 64 DCT_TqIncReq "An Identifier of a DCT TCU controller for increasing torque intervention. 

This bit is to prevent the triggering of unintended DCT TCU interventions.



In the case of a torque increase, following conditions must be fulfilled.

DCT_TqIncReq = 1 and TCU_";
BA_ "Version" SG_ 64 DCT_CrpTqReq "18.08.02";
BA_ "RoutingFactor" SG_ 64 DCT_CrpTqReq 5;
BA_ "UserSigValidity" SG_ 64 DCT_CrpTqReq 3;
BA_ "GenSigStartValue" SG_ 64 DCT_CrpTqReq 512;
BA_ "Description" SG_ 64 DCT_CrpTqReq "During creep mode (engine in idle, brake pedal not pressed, gear engaged) clutch torque will be applied. In order to support the engine’s idle controller DCT_CrpTqReq gives the information how much clutch torque will be applied within the next 50 ms.";
BA_ "Version" SG_ 64 DCT_ShftTqReq "20.03.05";
BA_ "RoutingFactor" SG_ 64 DCT_ShftTqReq 5;
BA_ "UserSigValidity" SG_ 64 DCT_ShftTqReq 3;
BA_ "Description" SG_ 64 DCT_ShftTqReq "To ensure a torque increasing during gear shift within short time, ECU needs to build up a torque reserve determined by the pre-control torque. 

Open throttle valve (more air) and automatic ignition angle reduction (within limited range based on engine ";
BA_ "Version" SG_ 64 TCU_GearSlctDis "24.12.01";
BA_ "RoutingFactor" SG_ 64 TCU_GearSlctDis 5;
BA_ "UserSigValidity" SG_ 64 TCU_GearSlctDis 3;
BA_ "GenSigStartValue" SG_ 64 TCU_GearSlctDis 9;
BA_ "Description" SG_ 64 TCU_GearSlctDis "Position (P, R, N..), which was identified by the gear selector.

In case the gear selector is in a intermediate position, the last clear recognized position is used.

There is no specific phase relationship between the output and any other signal.



Th";
BA_ "Version" SG_ 64 TCU_Typ "18.12.02";
BA_ "RoutingFactor" SG_ 64 TCU_Typ 5;
BA_ "UserSigValidity" SG_ 64 TCU_Typ 3;
BA_ "Description" SG_ 64 TCU_Typ "Information regarding the type of transmission - Step A/T or CVT or DCT / AMT / eClutch";
BA_ "Version" SG_ 64 TCU_TqRdctnVal "20.03.05";
BA_ "RoutingFactor" SG_ 64 TCU_TqRdctnVal 5;
BA_ "UserSigValidity" SG_ 64 TCU_TqRdctnVal 3;
BA_ "GenSigStartValue" SG_ 64 TCU_TqRdctnVal 2047;
BA_ "Description" SG_ 64 TCU_TqRdctnVal "The TCU requests a torque reduction via this signal to the EMS. 



If MSB is 1, this signal is - value.

else, this signal is +value.

0~10bit is used for absolute value.";
BA_ "Version" SG_ 64 CF_TCU_AES_Flag "25.03.01";
BA_ "RoutingFactor" SG_ 64 CF_TCU_AES_Flag 5;
BA_ "UserSigValidity" SG_ 64 CF_TCU_AES_Flag 3;
BA_ "Description" SG_ 64 CF_TCU_AES_Flag "AES Flag On/Off to ECU (for EURO6e-Bis regulation)";
BA_ "Version" SG_ 64 TCU_GearStepTyp "19.02.07";
BA_ "RoutingFactor" SG_ 64 TCU_GearStepTyp 5;
BA_ "UserSigValidity" SG_ 64 TCU_GearStepTyp 3;
BA_ "Description" SG_ 64 TCU_GearStepTyp "This signal indicates number of gear steps of step type automatic transmission(A/T) or Dual Clutch Transmission(DCT). A vehicle can have A/T or DCT variant according to its option, for example 4-speed A/T or 5-speed A/T can be equipped in the same kind o";
BA_ "Version" SG_ 64 TCU_GearShftSta "17.11.00";
BA_ "RoutingFactor" SG_ 64 TCU_GearShftSta 5;
BA_ "UserSigValidity" SG_ 64 TCU_GearShftSta 3;
BA_ "Description" SG_ 64 TCU_GearShftSta "SWI_GS indicates whether a gear change is being executed in the gearbox.



Note : Gear change means a gear shift at D-range and Garage shift(PRND).";
BA_ "Version" SG_ 64 TCU_TqCnvrtrSta "17.11.00";
BA_ "RoutingFactor" SG_ 64 TCU_TqCnvrtrSta 5;
BA_ "UserSigValidity" SG_ 64 TCU_TqCnvrtrSta 3;
BA_ "Description" SG_ 64 TCU_TqCnvrtrSta "Status converter clutch



There is no specific phase relationship between the output and any other signal.";
BA_ "Version" SG_ 64 TCU_CurrGearSta "17.11.00";
BA_ "RoutingFactor" SG_ 64 TCU_CurrGearSta 5;
BA_ "UserSigValidity" SG_ 64 TCU_CurrGearSta 3;
BA_ "Description" SG_ 64 TCU_CurrGearSta "CUR_GR indicates the gear speed which is currently engaged in the gearbox.";
BA_ "Version" SG_ 64 TCU_TrgtGearSta "17.11.00";
BA_ "RoutingFactor" SG_ 64 TCU_TrgtGearSta 5;
BA_ "UserSigValidity" SG_ 64 TCU_TrgtGearSta 3;
BA_ "Description" SG_ 64 TCU_TrgtGearSta "CF_Tcu_TarGr informs about the speed, which is currently engaged in the gearbox, or, in case of a gear change (SWI_GS), which speed is reached.



Note: Gear changes covering more than one speed are also possible.

In the P and N positions, the frictiona";
BA_ "Version" SG_ 64 TCU_CluTrgtGearSta "17.11.00";
BA_ "RoutingFactor" SG_ 64 TCU_CluTrgtGearSta 5;
BA_ "UserSigValidity" SG_ 64 TCU_CluTrgtGearSta 3;
BA_ "Description" SG_ 64 TCU_CluTrgtGearSta "TCH_CluTrgtGearSta informs about target gear of SS timing 

(For indicating Paddle shift or Manual mode on cluster)";
BA_ "Version" SG_ 64 TCH_EngTrgtGearSta "17.11.00";
BA_ "RoutingFactor" SG_ 64 TCH_EngTrgtGearSta 5;
BA_ "UserSigValidity" SG_ 64 TCH_EngTrgtGearSta 3;
BA_ "Description" SG_ 64 TCH_EngTrgtGearSta "TCH_EngTrgtGearSta informs about target gear of SS timing 

(For indicating Paddle shift or Manual mode on cluster)";
BA_ "Version" SG_ 64 TCU_EngTqLimVal "20.03.05";
BA_ "RoutingFactor" SG_ 64 TCU_EngTqLimVal 5;
BA_ "UserSigValidity" SG_ 64 TCU_EngTqLimVal 3;
BA_ "GenSigStartValue" SG_ 64 TCU_EngTqLimVal 2047;
BA_ "Description" SG_ 64 TCU_EngTqLimVal "The TCU requests a engine torque limit(ETL) from the EMS. 

There is no time limitation of the intervention.

TCU requests engine torque limit below the TCU requesting torque.

The engine torque request signal means the absolute torque limitation.

TCU s";
BA_ "Version" SG_ 64 TCU_CluTrgtGearConfg "18.08.01";
BA_ "RoutingFactor" SG_ 64 TCU_CluTrgtGearConfg 5;
BA_ "UserSigValidity" SG_ 64 TCU_CluTrgtGearConfg 3;
BA_ "Description" SG_ 64 TCU_CluTrgtGearConfg "This signal indicates the signal source configuration of target gear for CLU";
BA_ "Version" SG_ 64 TCU_DesiBoost "24.03.00";
BA_ "RoutingFactor" SG_ 64 TCU_DesiBoost 5;
BA_ "UserSigValidity" SG_ 64 TCU_DesiBoost 3;
BA_ "Description" SG_ 64 TCU_DesiBoost "TCU DesiBoost Control On/Off";
BA_ "Version" SG_ 64 TCU_VehSpdKphVal "17.11.00";
BA_ "RoutingFactor" SG_ 64 TCU_VehSpdKphVal 5;
BA_ "UserSigValidity" SG_ 64 TCU_VehSpdKphVal 3;
BA_ "Description" SG_ 64 TCU_VehSpdKphVal "The vehicle speed calculated by TCU is transferred. 

If a vehicle has no vehicle speed sensor, no wheel speed sensor and no ABS(TCS/ESC) then it is impossible for an EMS to calculate veficle speed. In this case a TCU should calculate vehicle speed and s";
BA_ "Version" SG_ 1308 VAPI_BltnCamInsideSwEnable_Set "25.07.04";
BA_ "RoutingFactor" SG_ 1308 VAPI_BltnCamInsideSwEnable_Set 0;
BA_ "UserSigValidity" SG_ 1308 VAPI_BltnCamInsideSwEnable_Set 0;
BA_ "GenSigSendType" SG_ 1308 VAPI_BltnCamInsideSwEnable_Set 4;
BA_ "Description" SG_ 1308 VAPI_BltnCamInsideSwEnable_Set "Built-in Cam manual button Enable/Disable request.";
BA_ "Version" SG_ 613 EMS_Crc8Val "21.09.03";
BA_ "RoutingFactor" SG_ 613 EMS_Crc8Val 2;
BA_ "UserSigValidity" SG_ 613 EMS_Crc8Val 3;
BA_ "GenSigStartValue" SG_ 613 EMS_Crc8Val 65535;
BA_ "Description" SG_ 613 EMS_Crc8Val "The data area for CRC calculation is based on the data length (DLC) of the message DB.

The CRC shall be calculated over the entire data block (excluding the CRC bytes) including the user data, alive counter and Data ID



- CRC Polynomial (0x1021) , Ini";
BA_ "Version" SG_ 613 HEV_EstClntTempVal "17.11.00";
BA_ "RoutingFactor" SG_ 613 HEV_EstClntTempVal 2;
BA_ "UserSigValidity" SG_ 613 HEV_EstClntTempVal 3;
BA_ "Description" SG_ 613 HEV_EstClntTempVal "Estimated Engine Coolant Temperature";
BA_ "Version" SG_ 613 HEV_AptVal "17.11.00";
BA_ "RoutingFactor" SG_ 613 HEV_AptVal 2;
BA_ "UserSigValidity" SG_ 613 HEV_AptVal 3;
BA_ "Description" SG_ 613 HEV_AptVal "APT Value";
BA_ "Version" SG_ 613 HEV_EstAmbtAirTempVal "17.11.00";
BA_ "RoutingFactor" SG_ 613 HEV_EstAmbtAirTempVal 2;
BA_ "UserSigValidity" SG_ 613 HEV_EstAmbtAirTempVal 3;
BA_ "GenSigStartValue" SG_ 613 HEV_EstAmbtAirTempVal 91;
BA_ "Description" SG_ 613 HEV_EstAmbtAirTempVal "Estimated Ambient air temperature";
BA_ "Version" SG_ 613 HEV_RbmSta "19.11.11";
BA_ "RoutingFactor" SG_ 613 HEV_RbmSta 2;
BA_ "UserSigValidity" SG_ 613 HEV_RbmSta 3;
BA_ "Description" SG_ 613 HEV_RbmSta "Status of rate-based monitoring



Value Description



Bit0 : minimum trip length condition 

Bit1 : vehicle speed condition 

Bit2 : continuous idle condition 

Bit3 : ambient temperature condition 

Bit4 : maximum altitude condition 

Bit5 : fuel engi";
BA_ "Version" SG_ 613 HEV_WarmUpReq_For_DATC "19.09.04";
BA_ "RoutingFactor" SG_ 613 HEV_WarmUpReq_For_DATC 2;
BA_ "UserSigValidity" SG_ 613 HEV_WarmUpReq_For_DATC 3;
BA_ "Description" SG_ 613 HEV_WarmUpReq_For_DATC "Flag indicating an EMS request not to stop the engine.

 * This signal is for reference on the DATC.

 * This signal is same as HEV_WarmUpReq (@EMS_09_10ms).";
BA_ "Version" SG_ 613 EMS_AlvCnt8Val "21.09.03";
BA_ "RoutingFactor" SG_ 613 EMS_AlvCnt8Val 2;
BA_ "UserSigValidity" SG_ 613 EMS_AlvCnt8Val 3;
BA_ "Description" SG_ 613 EMS_AlvCnt8Val "For the first transmission request for a data element the counter shall be initialized with 0 and shall be incremented by 1 for every subsequent send request. 

When the counter reaches the maximum value(0xFF), then it shall restart with 0 for the next s";
BA_ "Version" SG_ 613 HEV_RbmInhbtSta "24.12.02";
BA_ "RoutingFactor" SG_ 613 HEV_RbmInhbtSta 2;
BA_ "UserSigValidity" SG_ 613 HEV_RbmInhbtSta 3;
BA_ "Description" SG_ 613 HEV_RbmInhbtSta "Inhibition of rate based monitoring

[Bit0] 0:Enable of standardized vehicle operation and all numerators/denominators for RBM

[Bit0] 1:Inhibition of standardized vehicle operation and all numerators/denominators for RMB

[Bit1] 0:Enable of standardized";
BA_ "Version" SG_ 613 HEV_EhrsTempSta "17.11.00";
BA_ "RoutingFactor" SG_ 613 HEV_EhrsTempSta 2;
BA_ "UserSigValidity" SG_ 613 HEV_EhrsTempSta 3;
BA_ "Description" SG_ 613 HEV_EhrsTempSta "The  signal is condition about EHRS' temperature";
BA_ "Version" SG_ 613 HEV_Aaf_WrnLamp "19.11.11";
BA_ "RoutingFactor" SG_ 613 HEV_Aaf_WrnLamp 2;
BA_ "UserSigValidity" SG_ 613 HEV_Aaf_WrnLamp 3;
BA_ "Description" SG_ 613 HEV_Aaf_WrnLamp "Air Flap Warning Lamp/Message Request Signal indicates whether Warning Lamp/Message should be displayed in the display screen in order to warn AAF System failure to customer.";
BA_ "Version" SG_ 613 HEV_OPSFail "18.05.04";
BA_ "RoutingFactor" SG_ 613 HEV_OPSFail 2;
BA_ "UserSigValidity" SG_ 613 HEV_OPSFail 3;
BA_ "Description" SG_ 613 HEV_OPSFail "The signal indicates the status of the 'Oil Pressure Warning Lamp'";
BA_ "Version" SG_ 613 HEV_EngDsplceTyp "19.07.01";
BA_ "RoutingFactor" SG_ 613 HEV_EngDsplceTyp 2;
BA_ "UserSigValidity" SG_ 613 HEV_EngDsplceTyp 3;
BA_ "Description" SG_ 613 HEV_EngDsplceTyp "This signal indicates the engine displacement (volume).";
BA_ "Version" SG_ 613 HEV_EngTyp2 "19.07.01";
BA_ "RoutingFactor" SG_ 613 HEV_EngTyp2 2;
BA_ "UserSigValidity" SG_ 613 HEV_EngTyp2 3;
BA_ "Version" SG_ 613 HEV_EngTyp1 "19.07.01";
BA_ "RoutingFactor" SG_ 613 HEV_EngTyp1 2;
BA_ "UserSigValidity" SG_ 613 HEV_EngTyp1 3;
BA_ "Version" SG_ 613 HEV_S_F "19.07.01";
BA_ "RoutingFactor" SG_ 613 HEV_S_F 2;
BA_ "UserSigValidity" SG_ 613 HEV_S_F 3;
BA_ "Description" SG_ 613 HEV_S_F "AMS/ISG system type indicator";
BA_ "Version" SG_ 613 HEV_S_F_GEN "19.07.01";
BA_ "RoutingFactor" SG_ 613 HEV_S_F_GEN 2;
BA_ "UserSigValidity" SG_ 613 HEV_S_F_GEN 3;
BA_ "Description" SG_ 613 HEV_S_F_GEN "system generation type indicator";
BA_ "Version" SG_ 613 HEV_RbmSta_2nd "19.10.00";
BA_ "RoutingFactor" SG_ 613 HEV_RbmSta_2nd 2;
BA_ "UserSigValidity" SG_ 613 HEV_RbmSta_2nd 3;
BA_ "Description" SG_ 613 HEV_RbmSta_2nd "Status of rate-based monitoring



Value Description

Bit0 : cold start condition for PHEV

Bit1 : cold start inhibition condition for HEV/PHEV

Bit2 : reserved

Bit3 : reserved

Bit4 : reserved

Bit5 : reserved

Bit6 : reserved";
BA_ "Version" SG_ 613 HEV_RECTrigSta "20.02.02";
BA_ "RoutingFactor" SG_ 613 HEV_RECTrigSta 2;
BA_ "UserSigValidity" SG_ 613 HEV_RECTrigSta 3;
BA_ "Description" SG_ 613 HEV_RECTrigSta "Trigger signal(10 event) - when REC is occurred in the HEV ECU(Engine controller)";
BA_ "Version" SG_ 613 HEV_PendingTrigSta "20.02.02";
BA_ "RoutingFactor" SG_ 613 HEV_PendingTrigSta 2;
BA_ "UserSigValidity" SG_ 613 HEV_PendingTrigSta 3;
BA_ "Description" SG_ 613 HEV_PendingTrigSta "Trigger signal(10 event) - when Pending DTC is occurred in the HEV ECU(Engine controller)";
BA_ "Version" SG_ 613 HEV_OilLifeRatio "20.12.04";
BA_ "RoutingFactor" SG_ 613 HEV_OilLifeRatio 2;
BA_ "UserSigValidity" SG_ 613 HEV_OilLifeRatio 3;
BA_ "Description" SG_ 613 HEV_OilLifeRatio "EMS calculates remaining engine oil life, and Cluster displays this information with % unit, in order to guide driver to change engine oil.";
BA_ "Version" SG_ 613 HEV_OilLifeEna "20.12.04";
BA_ "RoutingFactor" SG_ 613 HEV_OilLifeEna 2;
BA_ "UserSigValidity" SG_ 613 HEV_OilLifeEna 3;
BA_ "Description" SG_ 613 HEV_OilLifeEna "Cluster displays engine oil life warning and life ratio signal if this enabling bit is true.";
BA_ "Version" SG_ 613 HEV_OilLifeWarn "20.12.04";
BA_ "RoutingFactor" SG_ 613 HEV_OilLifeWarn 2;
BA_ "UserSigValidity" SG_ 613 HEV_OilLifeWarn 3;
BA_ "Description" SG_ 613 HEV_OilLifeWarn "This signal indicates status of engine oil life warning.";
BA_ "Version" SG_ 613 HEV_ExtSoakTimeVal "21.06.08";
BA_ "RoutingFactor" SG_ 613 HEV_ExtSoakTimeVal 2;
BA_ "UserSigValidity" SG_ 613 HEV_ExtSoakTimeVal 3;
BA_ "Description" SG_ 613 HEV_ExtSoakTimeVal "The SoakTimeExt is the Additional soak time information, which start to increase from the moment that Soak Time is over 255 min.



Total Soak Time [min] = 1 * HEV_SoakTimeVal (EMS_08_100ms) [min] + 5 * HEV_ExtSoakTimeVal (EMS_08_100ms) [min]";
BA_ "Version" SG_ 613 HEV_AmbPrs "24.04.06";
BA_ "RoutingFactor" SG_ 613 HEV_AmbPrs 2;
BA_ "UserSigValidity" SG_ 613 HEV_AmbPrs 3;
BA_ "Description" SG_ 613 HEV_AmbPrs "Value of Ambient Pressure Sensor (Embedded in ECU)



0x000 ~ 0xFFE : 0 ~ 5,433 hPa

0xFFF : Error Value";
BA_ "Version" SG_ 613 HEV_EngClntTempVal "17.11.00";
BA_ "RoutingFactor" SG_ 613 HEV_EngClntTempVal 2;
BA_ "UserSigValidity" SG_ 613 HEV_EngClntTempVal 3;
BA_ "Description" SG_ 613 HEV_EngClntTempVal "Engine coolant temperature";
BA_ "Version" SG_ 613 HEV_EngOilTempVal "17.11.00";
BA_ "RoutingFactor" SG_ 613 HEV_EngOilTempVal 2;
BA_ "UserSigValidity" SG_ 613 HEV_EngOilTempVal 3;
BA_ "Description" SG_ 613 HEV_EngOilTempVal "Engine Oil Temperature";
BA_ "Version" SG_ 613 HEV_VbOffActSta "17.11.00";
BA_ "RoutingFactor" SG_ 613 HEV_VbOffActSta 2;
BA_ "UserSigValidity" SG_ 613 HEV_VbOffActSta 3;
BA_ "Description" SG_ 613 HEV_VbOffActSta "ECU adaptive values and failure memory erase after battery disconnection";
BA_ "Version" SG_ 613 HEV_AirCompOffReq "17.11.00";
BA_ "RoutingFactor" SG_ 613 HEV_AirCompOffReq 2;
BA_ "UserSigValidity" SG_ 613 HEV_AirCompOffReq 3;
BA_ "Description" SG_ 613 HEV_AirCompOffReq "air conditioner compressor off request";
BA_ "Version" SG_ 613 HEV_MilConfgVal "17.11.00";
BA_ "RoutingFactor" SG_ 613 HEV_MilConfgVal 2;
BA_ "UserSigValidity" SG_ 613 HEV_MilConfgVal 3;
BA_ "Description" SG_ 613 HEV_MilConfgVal "Configuration of MIL handing and failure memory management";
BA_ "Version" SG_ 613 HEV_CF_EMS_LOCKUP "18.10.12";
BA_ "RoutingFactor" SG_ 613 HEV_CF_EMS_LOCKUP 2;
BA_ "UserSigValidity" SG_ 613 HEV_CF_EMS_LOCKUP 3;
BA_ "Description" SG_ 613 HEV_CF_EMS_LOCKUP "Engine lock up maintenance request state

0x0 : Engine doesn't require lock up maintenance

0x1 : Engine require lock up mainentance";
BA_ "Version" SG_ 613 HEV_OilLvlSta "20.12.04";
BA_ "RoutingFactor" SG_ 613 HEV_OilLvlSta 2;
BA_ "UserSigValidity" SG_ 613 HEV_OilLvlSta 3;
BA_ "Description" SG_ 613 HEV_OilLvlSta "This signal indicates the replace time of engine oil.";
BA_ "Version" SG_ 613 HEV_ImmoLmpReq "17.11.00";
BA_ "RoutingFactor" SG_ 613 HEV_ImmoLmpReq 2;
BA_ "UserSigValidity" SG_ 613 HEV_ImmoLmpReq 3;
BA_ "Description" SG_ 613 HEV_ImmoLmpReq "Immobilizer Lamp";
BA_ "Version" SG_ 613 HEV_MilReq "17.11.00";
BA_ "RoutingFactor" SG_ 613 HEV_MilReq 2;
BA_ "UserSigValidity" SG_ 613 HEV_MilReq 3;
BA_ "Description" SG_ 613 HEV_MilReq "This signal indicates the status of MIL physical output.";
BA_ "Version" SG_ 613 HEV_WiperSwSta "17.11.00";
BA_ "RoutingFactor" SG_ 613 HEV_WiperSwSta 2;
BA_ "UserSigValidity" SG_ 613 HEV_WiperSwSta 3;
BA_ "Description" SG_ 613 HEV_WiperSwSta "This signal indicates the status of a wiper switch.";
BA_ "Version" SG_ 613 HEV_FanOpSta "17.11.00";
BA_ "RoutingFactor" SG_ 613 HEV_FanOpSta 2;
BA_ "UserSigValidity" SG_ 613 HEV_FanOpSta 3;
BA_ "Description" SG_ 613 HEV_FanOpSta "This signal indicates whether the cooling/condenser fan is operating or not.";
BA_ "Version" SG_ 613 HEV_FanSta "17.11.00";
BA_ "RoutingFactor" SG_ 613 HEV_FanSta 2;
BA_ "UserSigValidity" SG_ 613 HEV_FanSta 3;
BA_ "Description" SG_ 613 HEV_FanSta "This signal indicates the operating state of the cooling/condenser fan.";
BA_ "Version" SG_ 613 HEV_BrkLtSwSta "17.11.00";
BA_ "RoutingFactor" SG_ 613 HEV_BrkLtSwSta 2;
BA_ "UserSigValidity" SG_ 613 HEV_BrkLtSwSta 3;
BA_ "Description" SG_ 613 HEV_BrkLtSwSta "Brake light Switch";
BA_ "Version" SG_ 613 HEV_IgnCycCntVal "17.11.00";
BA_ "RoutingFactor" SG_ 613 HEV_IgnCycCntVal 2;
BA_ "UserSigValidity" SG_ 613 HEV_IgnCycCntVal 3;
BA_ "Description" SG_ 613 HEV_IgnCycCntVal "Number of driving cycle since first ECU power-up. The counter increases each time a driving cycle with engine running for a specified time duration is detected. This value is only initialized with 0 on saved RAM lost (or reprogramming).";
BA_ "Version" SG_ 613 HEV_SoakTimeVal "17.11.00";
BA_ "RoutingFactor" SG_ 613 HEV_SoakTimeVal 2;
BA_ "UserSigValidity" SG_ 613 HEV_SoakTimeVal 3;
BA_ "Description" SG_ 613 HEV_SoakTimeVal "Engine soaking time";
BA_ "Version" SG_ 613 HEV_SoakTimeErrSta "19.11.11";
BA_ "RoutingFactor" SG_ 613 HEV_SoakTimeErrSta 2;
BA_ "UserSigValidity" SG_ 613 HEV_SoakTimeErrSta 3;
BA_ "Description" SG_ 613 HEV_SoakTimeErrSta "If the HEV_SoakTimeErrSta = 1 then the engine is in fuel cut off state, i.e. e. no injection is applied.";
BA_ "Version" SG_ 613 HEV_SoakTimeOvrSta "18.12.01";
BA_ "RoutingFactor" SG_ 613 HEV_SoakTimeOvrSta 2;
BA_ "UserSigValidity" SG_ 613 HEV_SoakTimeOvrSta 3;
BA_ "Version" SG_ 613 HEV_FuelRunOutSta "17.11.00";
BA_ "RoutingFactor" SG_ 613 HEV_FuelRunOutSta 2;
BA_ "UserSigValidity" SG_ 613 HEV_FuelRunOutSta 3;
BA_ "Version" SG_ 613 HEV_FuelRunOutDetSta "17.11.00";
BA_ "RoutingFactor" SG_ 613 HEV_FuelRunOutDetSta 2;
BA_ "UserSigValidity" SG_ 613 HEV_FuelRunOutDetSta 3;
BA_ "Version" SG_ 613 HEV_FuelCnsmptSumVal "17.11.00";
BA_ "RoutingFactor" SG_ 613 HEV_FuelCnsmptSumVal 2;
BA_ "UserSigValidity" SG_ 613 HEV_FuelCnsmptSumVal 3;
BA_ "Description" SG_ 613 HEV_FuelCnsmptSumVal "Fuel Comsumption summed";
BA_ "Version" SG_ 1024 BVM_ViewMode "22.10.19";
BA_ "UserSigValidity" SG_ 1024 BVM_ViewMode 3;
BA_ "GenSigSendType" SG_ 1024 BVM_ViewMode 4;
BA_ "Description" SG_ 1024 BVM_ViewMode "This signal indicates Mode of BVM View";
BA_ "Version" SG_ 1024 SVM_CamConfgSta "25.10.00";
BA_ "UserSigValidity" SG_ 1024 SVM_CamConfgSta 0;
BA_ "GenSigSendType" SG_ 1024 SVM_CamConfgSta 4;
BA_ "Description" SG_ 1024 SVM_CamConfgSta "For Mobis SVM or ADAS_PRK System communication with Built-in Cam for I2C Master authority";
BA_ "Version" SG_ 1024 SVM_OperatSta "25.04.01";
BA_ "UserSigValidity" SG_ 1024 SVM_OperatSta 0;
BA_ "GenSigSendType" SG_ 1024 SVM_OperatSta 4;
BA_ "Description" SG_ 1024 SVM_OperatSta "For Mobis SVM or ADAS_PRK System";
BA_ "Version" SG_ 1024 BVM_View2Sta "20.10.02";
BA_ "UserSigValidity" SG_ 1024 BVM_View2Sta 3;
BA_ "GenSigSendType" SG_ 1024 BVM_View2Sta 4;
BA_ "Description" SG_ 1024 BVM_View2Sta "This signal indicates New signal of BVM_ViewSta.

Apply this signal when Display Priority move cluster to BVM";
BA_ "Version" SG_ 1024 ADAS_PRK_ResetOpsta "24.05.04";
BA_ "UserSigValidity" SG_ 1024 ADAS_PRK_ResetOpsta 0;
BA_ "GenSigSendType" SG_ 1024 ADAS_PRK_ResetOpsta 4;
BA_ "Description" SG_ 1024 ADAS_PRK_ResetOpsta "This signal indicates whether the reset operation has been completed or not";
BA_ "Version" SG_ 1024 SVM_ExteriorColorRedNValueSta "20.06.05";
BA_ "UserSigValidity" SG_ 1024 SVM_ExteriorColorRedNValueSta 3;
BA_ "GenSigStartValue" SG_ 1024 SVM_ExteriorColorRedNValueSta 256;
BA_ "GenSigSendType" SG_ 1024 SVM_ExteriorColorRedNValueSta 4;
BA_ "Description" SG_ 1024 SVM_ExteriorColorRedNValueSta "SVM Exterior Color Setting - Red (RGB)";
BA_ "Version" SG_ 1024 SVM_ExteriorColorGreenNValueSta "20.06.05";
BA_ "UserSigValidity" SG_ 1024 SVM_ExteriorColorGreenNValueSta 3;
BA_ "GenSigStartValue" SG_ 1024 SVM_ExteriorColorGreenNValueSta 256;
BA_ "GenSigSendType" SG_ 1024 SVM_ExteriorColorGreenNValueSta 4;
BA_ "Description" SG_ 1024 SVM_ExteriorColorGreenNValueSta "SVM Exterior Color Setting - Green (RGB)";
BA_ "Version" SG_ 1024 SVM_ExteriorColorBlueNValueSta "20.06.05";
BA_ "UserSigValidity" SG_ 1024 SVM_ExteriorColorBlueNValueSta 3;
BA_ "GenSigStartValue" SG_ 1024 SVM_ExteriorColorBlueNValueSta 256;
BA_ "GenSigSendType" SG_ 1024 SVM_ExteriorColorBlueNValueSta 4;
BA_ "Description" SG_ 1024 SVM_ExteriorColorBlueNValueSta "SVM Exterior Color Setting - Blue (RGB)";
BA_ "Version" SG_ 1026 BDC_FD_SMK_Crc3Val "22.11.04";
BA_ "UserSigValidity" SG_ 1026 BDC_FD_SMK_Crc3Val 0;
BA_ "GenSigStartValue" SG_ 1026 BDC_FD_SMK_Crc3Val 65535;
BA_ "GenSigSendType" SG_ 1026 BDC_FD_SMK_Crc3Val 4;
BA_ "Description" SG_ 1026 BDC_FD_SMK_Crc3Val "The data area for CRC calculation is based on the data length (DLC) of the message DB.

The CRC shall be calculated over the entire data block (excluding the CRC bytes) including the user data, alive counter and Data ID



- CRC Polynomial (0x1021) , Ini";
BA_ "Version" SG_ 1026 SMK_TrmnlCtrlStaBDCEV "23.07.04";
BA_ "UserSigValidity" SG_ 1026 SMK_TrmnlCtrlStaBDCEV 0;
BA_ "GenSigSendType" SG_ 1026 SMK_TrmnlCtrlStaBDCEV 4;
BA_ "Description" SG_ 1026 SMK_TrmnlCtrlStaBDCEV "Mirror Value of TerminalControlState(BDC EV)";
BA_ "Version" SG_ 1026 SMK_PwrOnModeSta "23.07.04";
BA_ "UserSigValidity" SG_ 1026 SMK_PwrOnModeSta 0;
BA_ "GenSigSendType" SG_ 1026 SMK_PwrOnModeSta 4;
BA_ "Description" SG_ 1026 SMK_PwrOnModeSta "Value of Power mode(BDC)";
BA_ "Version" SG_ 1026 SMK_StndbyMdTmrMin "22.05.02";
BA_ "UserSigValidity" SG_ 1026 SMK_StndbyMdTmrMin 0;
BA_ "GenSigSendType" SG_ 1026 SMK_StndbyMdTmrMin 4;
BA_ "Description" SG_ 1026 SMK_StndbyMdTmrMin "Information of Standby Mode timer";
BA_ "Version" SG_ 1026 SMK_PwrTransitionReq "24.01.03";
BA_ "UserSigValidity" SG_ 1026 SMK_PwrTransitionReq 0;
BA_ "GenSigSendType" SG_ 1026 SMK_PwrTransitionReq 4;
BA_ "Description" SG_ 1026 SMK_PwrTransitionReq "SMK Power Transition Request";
BA_ "Version" SG_ 1026 SMK_StndbyMdTmrSec "22.05.02";
BA_ "UserSigValidity" SG_ 1026 SMK_StndbyMdTmrSec 0;
BA_ "GenSigSendType" SG_ 1026 SMK_StndbyMdTmrSec 4;
BA_ "Description" SG_ 1026 SMK_StndbyMdTmrSec "Information of Standby Mode Timer";
BA_ "Version" SG_ 1026 SMK_VhclSlpSta "23.10.09";
BA_ "UserSigValidity" SG_ 1026 SMK_VhclSlpSta 0;
BA_ "GenSigSendType" SG_ 1026 SMK_VhclSlpSta 4;
BA_ "Description" SG_ 1026 SMK_VhclSlpSta "This Signal is used to calculate slope of the vehicle and to determine whether vehicle is in inclined condition or vehicle is in flat(inclination within the limits) condition for remote start operation (2nd CAN - C_VehicleSlopeState)";
BA_ "Version" SG_ 1026 USM_SmrtSldngModSta "19.01.09";
BA_ "UserSigValidity" SG_ 1026 USM_SmrtSldngModSta 0;
BA_ "GenSigSendType" SG_ 1026 USM_SmrtSldngModSta 4;
BA_ "Description" SG_ 1026 USM_SmrtSldngModSta "Current USM setting value of Smart Sliding Door mode";
BA_ "Version" SG_ 1026 SMK_EVPwrOffReq "23.04.05";
BA_ "UserSigValidity" SG_ 1026 SMK_EVPwrOffReq 0;
BA_ "TimeoutValue" SG_ 1026 SMK_EVPwrOffReq "0x0";
BA_ "GenSigSendType" SG_ 1026 SMK_EVPwrOffReq 4;
BA_ "Description" SG_ 1026 SMK_EVPwrOffReq "EV Power Off Request";
BA_ "Version" SG_ 1026 SMK_MaintenanceSrvMdReq "23.07.04";
BA_ "UserSigValidity" SG_ 1026 SMK_MaintenanceSrvMdReq 0;
BA_ "TimeoutValue" SG_ 1026 SMK_MaintenanceSrvMdReq "0x0";
BA_ "GenSigSendType" SG_ 1026 SMK_MaintenanceSrvMdReq 4;
BA_ "Description" SG_ 1026 SMK_MaintenanceSrvMdReq "Maintenance Service mode request from BDC to VCU";
BA_ "Version" SG_ 1026 Warn_DisWrngSta3 "24.12.02";
BA_ "UserSigValidity" SG_ 1026 Warn_DisWrngSta3 0;
BA_ "GenSigSendType" SG_ 1026 Warn_DisWrngSta3 4;
BA_ "Description" SG_ 1026 Warn_DisWrngSta3 "SMK Warnng Display signal";
BA_ "Version" SG_ 1026 SMK_CCUOTACrankInhState "24.04.03";
BA_ "UserSigValidity" SG_ 1026 SMK_CCUOTACrankInhState 0;
BA_ "GenSigSendType" SG_ 1026 SMK_CCUOTACrankInhState 4;
BA_ "Version" SG_ 1026 SMK_NParkModePwrOFFResult "25.04.01";
BA_ "UserSigValidity" SG_ 1026 SMK_NParkModePwrOFFResult 0;
BA_ "GenSigSendType" SG_ 1026 SMK_NParkModePwrOFFResult 4;
BA_ "Description" SG_ 1026 SMK_NParkModePwrOFFResult "N Parking Mode Cancel Request(SMK→VCU)";
BA_ "Version" SG_ 1026 SMK_TwoPressStrtSta "25.01.00";
BA_ "UserSigValidity" SG_ 1026 SMK_TwoPressStrtSta 0;
BA_ "GenSigSendType" SG_ 1026 SMK_TwoPressStrtSta 4;
BA_ "Description" SG_ 1026 SMK_TwoPressStrtSta "progress state by two brake inputs start";
BA_ "Version" SG_ 1026 SMK_PwrOffDspBtnActvSta "25.10.00";
BA_ "UserSigValidity" SG_ 1026 SMK_PwrOffDspBtnActvSta 0;
BA_ "GenSigStartValue" SG_ 1026 SMK_PwrOffDspBtnActvSta 3;
BA_ "GenSigSendType" SG_ 1026 SMK_PwrOffDspBtnActvSta 4;
BA_ "Description" SG_ 1026 SMK_PwrOffDspBtnActvSta "EV Terminal phase 2 : This signal sends 0x1 or 0x2

No EV Terminal phase 2 : This signal sends 0x0";
BA_ "Version" SG_ 1026 SMK_GetOffPopUpReq "25.04.01";
BA_ "UserSigValidity" SG_ 1026 SMK_GetOffPopUpReq 0;
BA_ "GenSigSendType" SG_ 1026 SMK_GetOffPopUpReq 4;
BA_ "Version" SG_ 1026 SMK_PwrOffHardBtnPopupReq "25.04.01";
BA_ "UserSigValidity" SG_ 1026 SMK_PwrOffHardBtnPopupReq 0;
BA_ "GenSigSendType" SG_ 1026 SMK_PwrOffHardBtnPopupReq 4;
BA_ "Version" SG_ 1026 SMK_EVRdyOffReq "25.04.00";
BA_ "UserSigValidity" SG_ 1026 SMK_EVRdyOffReq 0;
BA_ "GenSigSendType" SG_ 1026 SMK_EVRdyOffReq 4;
BA_ "Version" SG_ 1026 SMK_NTowMdAuthFailSta "25.04.01";
BA_ "UserSigValidity" SG_ 1026 SMK_NTowMdAuthFailSta 0;
BA_ "GenSigSendType" SG_ 1026 SMK_NTowMdAuthFailSta 4;
BA_ "Version" SG_ 1026 SMK_SftyMdExitOKSta "25.04.01";
BA_ "UserSigValidity" SG_ 1026 SMK_SftyMdExitOKSta 0;
BA_ "GenSigSendType" SG_ 1026 SMK_SftyMdExitOKSta 4;
BA_ "Version" SG_ 1026 SMK_SftyMdPopup "25.04.01";
BA_ "UserSigValidity" SG_ 1026 SMK_SftyMdPopup 0;
BA_ "GenSigSendType" SG_ 1026 SMK_SftyMdPopup 4;
BA_ "Version" SG_ 1026 BDC_FD_SMK_AlvCnt3Val "22.11.04";
BA_ "UserSigValidity" SG_ 1026 BDC_FD_SMK_AlvCnt3Val 0;
BA_ "GenSigSendType" SG_ 1026 BDC_FD_SMK_AlvCnt3Val 4;
BA_ "Description" SG_ 1026 BDC_FD_SMK_AlvCnt3Val "For the first transmission request for a data element the counter shall be initialized with 0 and shall be incremented by 1 for every subsequent send request. 

When the counter reaches the maximum value(0xFF), then it shall restart with 0 for the next s";
BA_ "Version" SG_ 1026 SMK_HUOTACrankInhState "25.07.02";
BA_ "UserSigValidity" SG_ 1026 SMK_HUOTACrankInhState 0;
BA_ "GenSigSendType" SG_ 1026 SMK_HUOTACrankInhState 4;
BA_ "Description" SG_ 1026 SMK_HUOTACrankInhState "This signal is state of Cranking Inhibit for HU OTA";
BA_ "Version" SG_ 1026 SMK_EasyPwrOffOpt "25.08.00";
BA_ "UserSigValidity" SG_ 1026 SMK_EasyPwrOffOpt 0;
BA_ "GenSigSendType" SG_ 1026 SMK_EasyPwrOffOpt 4;
BA_ "Description" SG_ 1026 SMK_EasyPwrOffOpt "This signal is used to confirm whether Easy Power Off is applied or not.";
BA_ "Version" SG_ 1026 SMK_EasyPwrOffInProgress "25.08.00";
BA_ "UserSigValidity" SG_ 1026 SMK_EasyPwrOffInProgress 0;
BA_ "GenSigSendType" SG_ 1026 SMK_EasyPwrOffInProgress 4;
BA_ "Description" SG_ 1026 SMK_EasyPwrOffInProgress "This signal indicates whether Easy Power Off is in progress.";
BA_ "Version" SG_ 1026 ESCL_EsclMngrSta "17.12.00";
BA_ "UserSigValidity" SG_ 1026 ESCL_EsclMngrSta 0;
BA_ "GenSigSendType" SG_ 1026 ESCL_EsclMngrSta 4;
BA_ "Description" SG_ 1026 ESCL_EsclMngrSta "ESCL manager state";
BA_ "Version" SG_ 1026 ESCL_EsclPwrSupSta "17.12.00";
BA_ "UserSigValidity" SG_ 1026 ESCL_EsclPwrSupSta 0;
BA_ "GenSigSendType" SG_ 1026 ESCL_EsclPwrSupSta 4;
BA_ "Description" SG_ 1026 ESCL_EsclPwrSupSta "ESCL GND & BAT supply line status";
BA_ "Version" SG_ 1026 Fob_FoundExtrnlIntArea "20.06.02";
BA_ "UserSigValidity" SG_ 1026 Fob_FoundExtrnlIntArea 0;
BA_ "GenSigSendType" SG_ 1026 Fob_FoundExtrnlIntArea 4;
BA_ "Description" SG_ 1026 Fob_FoundExtrnlIntArea "Exterior and Interior FOB Position recognize for Approach close function";
BA_ "Version" SG_ 1026 ESCL_EsclEnaSta "17.12.00";
BA_ "UserSigValidity" SG_ 1026 ESCL_EsclEnaSta 0;
BA_ "GenSigSendType" SG_ 1026 ESCL_EsclEnaSta 4;
BA_ "Description" SG_ 1026 ESCL_EsclEnaSta "SMK ESCL Enable output status";
BA_ "Version" SG_ 1026 ESCL_EsclUnitSta "17.12.00";
BA_ "UserSigValidity" SG_ 1026 ESCL_EsclUnitSta 0;
BA_ "GenSigSendType" SG_ 1026 ESCL_EsclUnitSta 4;
BA_ "Description" SG_ 1026 ESCL_EsclUnitSta "ESCL unit status";
BA_ "Version" SG_ 1026 ESCL_EsclBoltSta "17.12.00";
BA_ "UserSigValidity" SG_ 1026 ESCL_EsclBoltSta 0;
BA_ "GenSigSendType" SG_ 1026 ESCL_EsclBoltSta 4;
BA_ "Description" SG_ 1026 ESCL_EsclBoltSta "ESCL bolt status";
BA_ "Version" SG_ 1026 ESCL_EsclLoBattSta "17.12.00";
BA_ "UserSigValidity" SG_ 1026 ESCL_EsclLoBattSta 0;
BA_ "GenSigSendType" SG_ 1026 ESCL_EsclLoBattSta 4;
BA_ "Description" SG_ 1026 ESCL_EsclLoBattSta "Mirror value of ESCL Low Battery bit in ESCL Status bytes";
BA_ "Version" SG_ 1026 ESCL_EsclUnLkSwSta "17.12.00";
BA_ "UserSigValidity" SG_ 1026 ESCL_EsclUnLkSwSta 0;
BA_ "GenSigSendType" SG_ 1026 ESCL_EsclUnLkSwSta 4;
BA_ "Description" SG_ 1026 ESCL_EsclUnLkSwSta "ESCL unlock switch status";
BA_ "Version" SG_ 1026 Fob_FoundRrLftArea "20.06.02";
BA_ "UserSigValidity" SG_ 1026 Fob_FoundRrLftArea 0;
BA_ "GenSigSendType" SG_ 1026 Fob_FoundRrLftArea 4;
BA_ "Description" SG_ 1026 Fob_FoundRrLftArea "This Signal Indicates direction of user approach to vehicle.

If Approach Open function is enabled and user Approach to vehicle Rear Left direction, 

This signal set On.";
BA_ "Version" SG_ 1026 Fob_FoundRrRtArea "20.06.02";
BA_ "UserSigValidity" SG_ 1026 Fob_FoundRrRtArea 0;
BA_ "GenSigSendType" SG_ 1026 Fob_FoundRrRtArea 4;
BA_ "Description" SG_ 1026 Fob_FoundRrRtArea "This Signal Indicates direction of user approach to vehicle.

If Approach Open function is enabled and user Approach to vehicle Rear Right direction, 

This signal set On.";
BA_ "Version" SG_ 1026 Warn_StrtStpBtnWrngSta "17.12.00";
BA_ "UserSigValidity" SG_ 1026 Warn_StrtStpBtnWrngSta 0;
BA_ "GenSigSendType" SG_ 1026 Warn_StrtStpBtnWrngSta 4;
BA_ "Description" SG_ 1026 Warn_StrtStpBtnWrngSta "-(Old)C_SSB_Warning";
BA_ "Version" SG_ 1026 Warn_DeActvWrngSta "17.12.00";
BA_ "UserSigValidity" SG_ 1026 Warn_DeActvWrngSta 0;
BA_ "GenSigSendType" SG_ 1026 Warn_DeActvWrngSta 4;
BA_ "Description" SG_ 1026 Warn_DeActvWrngSta "-(Old)C_Deactivation_Warning";
BA_ "Version" SG_ 1026 Warn_GearPosPWrngReq "17.12.00";
BA_ "UserSigValidity" SG_ 1026 Warn_GearPosPWrngReq 0;
BA_ "GenSigSendType" SG_ 1026 Warn_GearPosPWrngReq 4;
BA_ "Description" SG_ 1026 Warn_GearPosPWrngReq "-(Old)C_Shift_P_Warning";
BA_ "Version" SG_ 1026 Warn_ExtrnlBuzWrngSta "21.11.01";
BA_ "UserSigValidity" SG_ 1026 Warn_ExtrnlBuzWrngSta 0;
BA_ "GenSigSendType" SG_ 1026 Warn_ExtrnlBuzWrngSta 4;
BA_ "Description" SG_ 1026 Warn_ExtrnlBuzWrngSta "-(Old)C_PICWarning";
BA_ "Version" SG_ 1026 Warn_IdOutWrngSta "22.11.00";
BA_ "UserSigValidity" SG_ 1026 Warn_IdOutWrngSta 0;
BA_ "GenSigSendType" SG_ 1026 Warn_IdOutWrngSta 4;
BA_ "Description" SG_ 1026 Warn_IdOutWrngSta "-(Old)C_IDOUT_WNG";
BA_ "Version" SG_ 1026 Warn_KeyBattLoWrngSta "17.12.00";
BA_ "UserSigValidity" SG_ 1026 Warn_KeyBattLoWrngSta 0;
BA_ "GenSigSendType" SG_ 1026 Warn_KeyBattLoWrngSta 4;
BA_ "Description" SG_ 1026 Warn_KeyBattLoWrngSta "-(Old)C_KeyBATDischargeWarning";
BA_ "Version" SG_ 1026 Warn_KeyOutLmpOnReq "17.12.00";
BA_ "UserSigValidity" SG_ 1026 Warn_KeyOutLmpOnReq 0;
BA_ "GenSigSendType" SG_ 1026 Warn_KeyOutLmpOnReq 4;
BA_ "Description" SG_ 1026 Warn_KeyOutLmpOnReq "-(Old)C_KeyoutLpWngCluster";
BA_ "Version" SG_ 1026 Warn_NotGearPosPWrngSta "17.12.00";
BA_ "UserSigValidity" SG_ 1026 Warn_NotGearPosPWrngSta 0;
BA_ "GenSigSendType" SG_ 1026 Warn_NotGearPosPWrngSta 4;
BA_ "Description" SG_ 1026 Warn_NotGearPosPWrngSta "-(Old)C_Vehicle_not_P_Warning";
BA_ "Version" SG_ 1026 Warn_EsclFlWrngSta "17.12.00";
BA_ "UserSigValidity" SG_ 1026 Warn_EsclFlWrngSta 0;
BA_ "GenSigSendType" SG_ 1026 Warn_EsclFlWrngSta 4;
BA_ "Description" SG_ 1026 Warn_EsclFlWrngSta "-(Old)C_ESCL_Fail_Warning";
BA_ "Version" SG_ 1026 Warn_EsclNotLkWrngSta "17.12.00";
BA_ "UserSigValidity" SG_ 1026 Warn_EsclNotLkWrngSta 0;
BA_ "GenSigSendType" SG_ 1026 Warn_EsclNotLkWrngSta 4;
BA_ "Description" SG_ 1026 Warn_EsclNotLkWrngSta "-(Old)C_ESCL_Notlocked_Warning";
BA_ "Version" SG_ 1026 Warn_EsclNotUnLkWrngSta "17.12.00";
BA_ "UserSigValidity" SG_ 1026 Warn_EsclNotUnLkWrngSta 0;
BA_ "GenSigSendType" SG_ 1026 Warn_EsclNotUnLkWrngSta 4;
BA_ "Description" SG_ 1026 Warn_EsclNotUnLkWrngSta "-(Old)C_ESCLNotUnlockWarning";
BA_ "Version" SG_ 1026 Warn_ImmoLmpOnReq "17.12.00";
BA_ "UserSigValidity" SG_ 1026 Warn_ImmoLmpOnReq 0;
BA_ "GenSigSendType" SG_ 1026 Warn_ImmoLmpOnReq 4;
BA_ "Description" SG_ 1026 Warn_ImmoLmpOnReq "-(Old)C_ImmoLp";
BA_ "Version" SG_ 1026 Warn_DisWrngSta2 "23.07.04";
BA_ "UserSigValidity" SG_ 1026 Warn_DisWrngSta2 0;
BA_ "GenSigSendType" SG_ 1026 Warn_DisWrngSta2 4;
BA_ "Description" SG_ 1026 Warn_DisWrngSta2 "This signal is used for a request to SMK Display Warning on CLU.";
BA_ "Version" SG_ 1026 Warn_DisWrngSta "24.10.03";
BA_ "UserSigValidity" SG_ 1026 Warn_DisWrngSta 0;
BA_ "GenSigSendType" SG_ 1026 Warn_DisWrngSta 4;
BA_ "Description" SG_ 1026 Warn_DisWrngSta "-(Old)C_PICWarningIND



*Changed Value Table ('15 1/12)

: 0x4 : Not Locked Warning → AC_Plug_Connected_Warning

for EV/PHEV SMK Warning Logic(Cranking Trial with AC Plug Connected)



*Changed Value Table('18.11/15)

: 0xF : Vehicle_is_On(FingerPrint)";
BA_ "Version" SG_ 1026 SMK_OTACrankInhState "24.10.03";
BA_ "UserSigValidity" SG_ 1026 SMK_OTACrankInhState 0;
BA_ "GenSigSendType" SG_ 1026 SMK_OTACrankInhState 4;
BA_ "Description" SG_ 1026 SMK_OTACrankInhState "Crank inhibit control state of OTA";
BA_ "Version" SG_ 1026 SMK_TgltAwaySrchResult "19.01.09";
BA_ "UserSigValidity" SG_ 1026 SMK_TgltAwaySrchResult 0;
BA_ "GenSigSendType" SG_ 1026 SMK_TgltAwaySrchResult 4;
BA_ "Description" SG_ 1026 SMK_TgltAwaySrchResult "Fob key search result response for Tailgate Away Close function";
BA_ "Version" SG_ 1026 SMKFOBID_CHNAVNT "21.07.05";
BA_ "NetworkRequestHoldingTime" SG_ 1026 SMKFOBID_CHNAVNT 5000;
BA_ "NetworkRequest" SG_ 1026 SMKFOBID_CHNAVNT 0;
BA_ "UserSigValidity" SG_ 1026 SMKFOBID_CHNAVNT 0;
BA_ "GenSigSendType" SG_ 1026 SMKFOBID_CHNAVNT 4;
BA_ "Description" SG_ 1026 SMKFOBID_CHNAVNT "This signal is used for china AVNT personalization function.";
BA_ "Version" SG_ 1026 SMK_TrmnlCtrlGrpStaBDC "22.01.06";
BA_ "UserSigValidity" SG_ 1026 SMK_TrmnlCtrlGrpStaBDC 0;
BA_ "GenSigSendType" SG_ 1026 SMK_TrmnlCtrlGrpStaBDC 4;
BA_ "Description" SG_ 1026 SMK_TrmnlCtrlGrpStaBDC "Mirror Value of TerminalControlGroupState(BDC)";
BA_ "Version" SG_ 1026 SMK_TrmnlCtrlGrpStaBDCEV "23.07.04";
BA_ "UserSigValidity" SG_ 1026 SMK_TrmnlCtrlGrpStaBDCEV 0;
BA_ "GenSigSendType" SG_ 1026 SMK_TrmnlCtrlGrpStaBDCEV 4;
BA_ "Description" SG_ 1026 SMK_TrmnlCtrlGrpStaBDCEV "Mirror Value of TerminalControlGroupState(BDC-EV)";
BA_ "Version" SG_ 1026 SMK_TrmnlCtrlStaBDC "22.01.06";
BA_ "UserSigValidity" SG_ 1026 SMK_TrmnlCtrlStaBDC 0;
BA_ "GenSigSendType" SG_ 1026 SMK_TrmnlCtrlStaBDC 4;
BA_ "Description" SG_ 1026 SMK_TrmnlCtrlStaBDC "Mirror Value of TerminalControlState(BDC)";
BA_ "Version" SG_ 193 BLTN_CAM_FD_Crc1Val "22.11.04";
BA_ "UserSigValidity" SG_ 193 BLTN_CAM_FD_Crc1Val 3;
BA_ "GenSigStartValue" SG_ 193 BLTN_CAM_FD_Crc1Val 65535;
BA_ "GenSigSendType" SG_ 193 BLTN_CAM_FD_Crc1Val 4;
BA_ "Description" SG_ 193 BLTN_CAM_FD_Crc1Val "The data area for CRC calculation is based on the data length (DLC) of the message DB.

The CRC shall be calculated over the entire data block (excluding the CRC bytes) including the user data, alive counter and Data ID



- CRC Polynomial (0x1021) , Ini";
BA_ "Version" SG_ 193 BLTN_CAM_FD_AlvCnt1Val "22.11.04";
BA_ "UserSigValidity" SG_ 193 BLTN_CAM_FD_AlvCnt1Val 3;
BA_ "GenSigSendType" SG_ 193 BLTN_CAM_FD_AlvCnt1Val 4;
BA_ "Description" SG_ 193 BLTN_CAM_FD_AlvCnt1Val "For the first transmission request for a data element the counter shall be initialized with 0 and shall be incremented by 1 for every subsequent send request. 

When the counter reaches the maximum value(0xFF), then it shall restart with 0 for the next s";
BA_ "Version" SG_ 193 BLTN_CAM_UI_Mode_Tmt_Req "21.05.02";
BA_ "UserSigValidity" SG_ 193 BLTN_CAM_UI_Mode_Tmt_Req 1;
BA_ "GenSigSendType" SG_ 193 BLTN_CAM_UI_Mode_Tmt_Req 4;
BA_ "Description" SG_ 193 BLTN_CAM_UI_Mode_Tmt_Req "Built-in Cam UI Mode terminate request.";
BA_ "Version" SG_ 193 BLTN_CAM_PopUp_Req "25.07.04";
BA_ "UserSigValidity" SG_ 193 BLTN_CAM_PopUp_Req 0;
BA_ "GenSigSendType" SG_ 193 BLTN_CAM_PopUp_Req 4;
BA_ "Description" SG_ 193 BLTN_CAM_PopUp_Req "Built-in Cam Operating and SD Card related Popup Request on HU Display.";
BA_ "Version" SG_ 193 BLTN_CAM_File_List_Renew "21.05.02";
BA_ "UserSigValidity" SG_ 193 BLTN_CAM_File_List_Renew 1;
BA_ "GenSigSendType" SG_ 193 BLTN_CAM_File_List_Renew 4;
BA_ "Description" SG_ 193 BLTN_CAM_File_List_Renew "The Storage information is renewed inform to HU.";
BA_ "Version" SG_ 193 BLTN_CAM_Wifi_Pwd_Chg_State "21.05.04";
BA_ "UserSigValidity" SG_ 193 BLTN_CAM_Wifi_Pwd_Chg_State 1;
BA_ "GenSigSendType" SG_ 193 BLTN_CAM_Wifi_Pwd_Chg_State 4;
BA_ "Description" SG_ 193 BLTN_CAM_Wifi_Pwd_Chg_State "The Response, when HU change Wifi Passowrd via SOME/IP";
BA_ "Version" SG_ 193 BLTN_CAM_Dis_Touch_BeepSound "21.09.05";
BA_ "UserSigValidity" SG_ 193 BLTN_CAM_Dis_Touch_BeepSound 1;
BA_ "GenSigSendType" SG_ 193 BLTN_CAM_Dis_Touch_BeepSound 4;
BA_ "Description" SG_ 193 BLTN_CAM_Dis_Touch_BeepSound "Display Touch Beep Sound of valid space touch.";
BA_ "Version" SG_ 345 LBM_FD_Crc2Val "24.04.07";
BA_ "RoutingFactor" SG_ 345 LBM_FD_Crc2Val 2;
BA_ "UserSigValidity" SG_ 345 LBM_FD_Crc2Val 3;
BA_ "GenSigStartValue" SG_ 345 LBM_FD_Crc2Val 65535;
BA_ "Description" SG_ 345 LBM_FD_Crc2Val "The data area for CRC calculation is based on the data length (DLC) of the message DB.

The CRC shall be calculated over the entire data block (excluding the CRC bytes) including the user data, alive counter and Data ID



- CRC Polynomial (0x1021) , Ini";
BA_ "Version" SG_ 345 MainLBM_NormalPwrVal "25.01.00";
BA_ "RoutingFactor" SG_ 345 MainLBM_NormalPwrVal 2;
BA_ "UserSigValidity" SG_ 345 MainLBM_NormalPwrVal 0;
BA_ "Version" SG_ 345 MainLBM_NormalWhVal "25.01.00";
BA_ "RoutingFactor" SG_ 345 MainLBM_NormalWhVal 2;
BA_ "UserSigValidity" SG_ 345 MainLBM_NormalWhVal 0;
BA_ "Version" SG_ 345 MainLBM_NormalReserveTimeVal "25.01.00";
BA_ "RoutingFactor" SG_ 345 MainLBM_NormalReserveTimeVal 2;
BA_ "UserSigValidity" SG_ 345 MainLBM_NormalReserveTimeVal 0;
BA_ "Version" SG_ 345 LBM_FD_AlvCnt2Val "24.04.07";
BA_ "RoutingFactor" SG_ 345 LBM_FD_AlvCnt2Val 2;
BA_ "UserSigValidity" SG_ 345 LBM_FD_AlvCnt2Val 3;
BA_ "Description" SG_ 345 LBM_FD_AlvCnt2Val "For the first transmission request for a data element the counter shall be initialized with 0 and shall be incremented by 1 for every subsequent send request. 

When the counter reaches the maximum value(0xFF), then it shall restart with 0 for the next s";
BA_ "Version" SG_ 345 MainLBM_SleepReserveTimeVal "25.01.00";
BA_ "RoutingFactor" SG_ 345 MainLBM_SleepReserveTimeVal 2;
BA_ "UserSigValidity" SG_ 345 MainLBM_SleepReserveTimeVal 0;
BA_ "Version" SG_ 345 MainLBM_CurrVal "25.10.02";
BA_ "RoutingFactor" SG_ 345 MainLBM_CurrVal 2;
BA_ "UserSigValidity" SG_ 345 MainLBM_CurrVal 0;
BA_ "GenSigStartValue" SG_ 345 MainLBM_CurrVal 65535;
BA_ "Description" SG_ 345 MainLBM_CurrVal "This is Battery current as measured by battery sensor.

This value is  

   - IRANGE : 1 (medium current)

   - Resolution : 10mA";
BA_ "Version" SG_ 345 MainLBM_SocVal "24.04.07";
BA_ "RoutingFactor" SG_ 345 MainLBM_SocVal 2;
BA_ "UserSigValidity" SG_ 345 MainLBM_SocVal 0;
BA_ "Description" SG_ 345 MainLBM_SocVal "This signal is battery State of Charge as calculated by battery sensor.";
BA_ "Version" SG_ 345 MainLBM_VtgVal "24.04.07";
BA_ "RoutingFactor" SG_ 345 MainLBM_VtgVal 2;
BA_ "UserSigValidity" SG_ 345 MainLBM_VtgVal 0;
BA_ "GenSigStartValue" SG_ 345 MainLBM_VtgVal 16383;
BA_ "Description" SG_ 345 MainLBM_VtgVal "This is the actual battery voltage as measured on the battery pole by battery sensor.

The Resolution is 1mV.";
BA_ "Version" SG_ 345 MainLBM_TempVal "24.04.07";
BA_ "RoutingFactor" SG_ 345 MainLBM_TempVal 2;
BA_ "UserSigValidity" SG_ 345 MainLBM_TempVal 0;
BA_ "GenSigStartValue" SG_ 345 MainLBM_TempVal 511;
BA_ "Description" SG_ 345 MainLBM_TempVal "This is actual battery electrolyte temperature value by battery sensor.

The value is calculated by a Battery Temperature Model, depending on measured temperature of the battery pole.

The resolution is 0.5℃.";
BA_ "Version" SG_ 345 MainLBM_SocErrSta "24.04.07";
BA_ "RoutingFactor" SG_ 345 MainLBM_SocErrSta 2;
BA_ "UserSigValidity" SG_ 345 MainLBM_SocErrSta 0;
BA_ "GenSigStartValue" SG_ 345 MainLBM_SocErrSta 1;
BA_ "Description" SG_ 345 MainLBM_SocErrSta "This bit is flags for indication whether battery SOC detection value is plausible or not by battery sensor.

If it is set to value 0, then it means battery SOC is normal state.

If it is set to value 1, then it means battery SOC is implausible state.

 *";
BA_ "Version" SG_ 345 MainLBM_SohVal "24.04.07";
BA_ "RoutingFactor" SG_ 345 MainLBM_SohVal 2;
BA_ "UserSigValidity" SG_ 345 MainLBM_SohVal 0;
BA_ "GenSigStartValue" SG_ 345 MainLBM_SohVal 127;
BA_ "Description" SG_ 345 MainLBM_SohVal "This signal is battery State of Health(SOH) as calculated by battery sensor.

This value shows reduction rate of nominal capacity.

This value can be used for diagnosis information of application system.";
BA_ "Version" SG_ 345 MainLBM_SnsrInvldSta "24.04.07";
BA_ "RoutingFactor" SG_ 345 MainLBM_SnsrInvldSta 2;
BA_ "UserSigValidity" SG_ 345 MainLBM_SnsrInvldSta 0;
BA_ "GenSigStartValue" SG_ 345 MainLBM_SnsrInvldSta 1;
BA_ "Description" SG_ 345 MainLBM_SnsrInvldSta "This bit is Battery Sensor Invalid flag and setting condition is depending on Battery Sensor self diagnosis information.

 BS Invalid = 0 : BS is Valid Condition

 BS Invalid = 1 : BS is Invalid Condition";
BA_ "Version" SG_ 345 MainLBM_RspErrSta "24.04.07";
BA_ "RoutingFactor" SG_ 345 MainLBM_RspErrSta 2;
BA_ "UserSigValidity" SG_ 345 MainLBM_RspErrSta 0;
BA_ "GenSigStartValue" SG_ 345 MainLBM_RspErrSta 1;
BA_ "Description" SG_ 345 MainLBM_RspErrSta "Battery Sensor shall send one status bit signal, Response_Error. Response_Error shall be set whenever a frame received by the node or a frame transmitted by the node contains an error in the response field.

Response_Error shall be cleared after transmis";
BA_ "Version" SG_ 345 MainLBM_CapacityVal "24.04.07";
BA_ "RoutingFactor" SG_ 345 MainLBM_CapacityVal 2;
BA_ "UserSigValidity" SG_ 345 MainLBM_CapacityVal 0;
BA_ "Description" SG_ 345 MainLBM_CapacityVal "12V Battery Capacity Value";
BA_ "Version" SG_ 345 MainLBM_SohErrSta "24.04.07";
BA_ "RoutingFactor" SG_ 345 MainLBM_SohErrSta 2;
BA_ "UserSigValidity" SG_ 345 MainLBM_SohErrSta 0;
BA_ "Version" SG_ 345 MainLBM_PeakLoadPwrVal "25.01.00";
BA_ "RoutingFactor" SG_ 345 MainLBM_PeakLoadPwrVal 2;
BA_ "UserSigValidity" SG_ 345 MainLBM_PeakLoadPwrVal 0;
BA_ "Version" SG_ 74 IMU_Crc1Val "21.09.03";
BA_ "RoutingFactor" SG_ 74 IMU_Crc1Val 0;
BA_ "UserSigValidity" SG_ 74 IMU_Crc1Val 3;
BA_ "GenSigStartValue" SG_ 74 IMU_Crc1Val 65535;
BA_ "Description" SG_ 74 IMU_Crc1Val "The data area for CRC calculation is based on the data length (DLC) of the message DB.

The CRC shall be calculated over the entire data block (excluding the CRC bytes) including the user data, alive counter and Data ID



- CRC Polynomial (0x1021) , Ini";
BA_ "Version" SG_ 74 IMU_SnsrTempVal "20.03.05";
BA_ "RoutingFactor" SG_ 74 IMU_SnsrTempVal 0;
BA_ "UserSigValidity" SG_ 74 IMU_SnsrTempVal 3;
BA_ "GenSigStartValue" SG_ 74 IMU_SnsrTempVal 68;
BA_ "Description" SG_ 74 IMU_SnsrTempVal "The temperature is measured on sensing element chip in ACU, so it may be different from the display indicator temperature of the vehicle.



Physical range: -68°C = 00h, +60 °C = 80h, +187°C = FFh



Quantization LSB: 1[°C/digit]



Temperature [°C]";
BA_ "Version" SG_ 74 IMU_SeralNumVal "20.03.05";
BA_ "RoutingFactor" SG_ 74 IMU_SeralNumVal 0;
BA_ "UserSigValidity" SG_ 74 IMU_SeralNumVal 3;
BA_ "Description" SG_ 74 IMU_SeralNumVal "IMU serial number in range of 



0x000000000000 = 0......0xFFFFFFFFFFFF

※Initial value shall be actual value

※This information is only for chipset with yaw sensor.";
BA_ "Version" SG_ 74 IMU_AlvCnt1Val "21.09.03";
BA_ "RoutingFactor" SG_ 74 IMU_AlvCnt1Val 0;
BA_ "UserSigValidity" SG_ 74 IMU_AlvCnt1Val 3;
BA_ "Description" SG_ 74 IMU_AlvCnt1Val "For the first transmission request for a data element the counter shall be initialized with 0 and shall be incremented by 1 for every subsequent send request. 

When the counter reaches the maximum value(0xFF), then it shall restart with 0 for the next s";
BA_ "Version" SG_ 74 IMU_RollRtVal "20.03.05";
BA_ "RoutingFactor" SG_ 74 IMU_RollRtVal 0;
BA_ "UserSigValidity" SG_ 74 IMU_RollRtVal 3;
BA_ "GenSigStartValue" SG_ 74 IMU_RollRtVal 32768;
BA_ "Description" SG_ 74 IMU_RollRtVal "This signal indicates Information regarding Roll rate.



physical range : -163.84..163.83 ˚/s = 0000H..FFFEh



Conversion : (PH) = ((HEX)-8000H)*0.005[˚/s/digit]



                            = (HEX)*0.005[˚/s/digit] - 163.84[˚/s]



             ";
BA_ "Version" SG_ 74 IMU_VerAccelVal "20.03.05";
BA_ "RoutingFactor" SG_ 74 IMU_VerAccelVal 0;
BA_ "UserSigValidity" SG_ 74 IMU_VerAccelVal 3;
BA_ "GenSigStartValue" SG_ 74 IMU_VerAccelVal 32768;
BA_ "Description" SG_ 74 IMU_VerAccelVal "This signal indicates Information regarding Vertical acceleration.



physical range : -4.1768g..4.1765g = 0000H..FFFEh



Conversion : (PH) = ((HEX)-8000H)*0.000127465[g/digit]



                            = (HEX)*0.000127465[g/digit] - 4.17677312[g]

";
BA_ "Version" SG_ 74 IMU_PitchRtVal "25.03.01";
BA_ "RoutingFactor" SG_ 74 IMU_PitchRtVal 0;
BA_ "UserSigValidity" SG_ 74 IMU_PitchRtVal 3;
BA_ "GenSigStartValue" SG_ 74 IMU_PitchRtVal 32768;
BA_ "Description" SG_ 74 IMU_PitchRtVal "This signal indicates Information regarding Pitch rate.



physical range : -163.84..163.83 ˚/s = 0000H..FFFEh



Conversion : (PH) = ((HEX)-8000H)*0.005[˚/s/digit]



                            = (HEX)*0.005[˚/s/digit] - 163.84[˚/s]



            ";
BA_ "Version" SG_ 74 IMU_YawSigSta "25.06.01";
BA_ "RoutingFactor" SG_ 74 IMU_YawSigSta 0;
BA_ "UserSigValidity" SG_ 74 IMU_YawSigSta 3;
BA_ "GenSigStartValue" SG_ 74 IMU_YawSigSta 2;
BA_ "Description" SG_ 74 IMU_YawSigSta "This signal indicates failure status of yaw rate signal and yaw rate sensing element.



0000B : No failure 



xxx1B : IMU_Yawrate_failure



xx1xB : Initialization is running



x1xxB : Reserved



1xxxB : Not applied



This signal represents the phys";
BA_ "Version" SG_ 74 IMU_LatAccelSigSta "25.06.01";
BA_ "RoutingFactor" SG_ 74 IMU_LatAccelSigSta 0;
BA_ "UserSigValidity" SG_ 74 IMU_LatAccelSigSta 3;
BA_ "GenSigStartValue" SG_ 74 IMU_LatAccelSigSta 2;
BA_ "Description" SG_ 74 IMU_LatAccelSigSta "This signal indicates failure status of lateral acceleration signal and sensing element.



0000B : No failure



xxx1B : IMU_Lateral acceleration failure



xx1xB : Initialization is running



x1xxB : Reserved



1xxxB : Not applied



This signal repr";
BA_ "Version" SG_ 74 IMU_LongAccelSigSta "25.06.01";
BA_ "RoutingFactor" SG_ 74 IMU_LongAccelSigSta 0;
BA_ "UserSigValidity" SG_ 74 IMU_LongAccelSigSta 3;
BA_ "GenSigStartValue" SG_ 74 IMU_LongAccelSigSta 2;
BA_ "Description" SG_ 74 IMU_LongAccelSigSta "This signal indicates failure status of longitudinal acceleration signal and sensing element.



0000B : No failure 



xxx1B : IMU_Longitudial acceleration failure



xx1xB : Initialization is running



x1xxB : Reserved



1xxxB : Not applied



This s";
BA_ "Version" SG_ 74 IMU_VerAccelSigSta "25.06.01";
BA_ "RoutingFactor" SG_ 74 IMU_VerAccelSigSta 0;
BA_ "UserSigValidity" SG_ 74 IMU_VerAccelSigSta 3;
BA_ "GenSigStartValue" SG_ 74 IMU_VerAccelSigSta 2;
BA_ "Description" SG_ 74 IMU_VerAccelSigSta "This signal indicates failure status of  vertial acceleration signal and yaw rate sensing element.



0000B : No failure 



xxx1B : IMU_Vertial acceleration failure



xx1xB : Initialization is running



x1xxB : Reserved



1xxxB : Not applied



This ";
BA_ "Version" SG_ 74 IMU_McuVoltSta "20.03.05";
BA_ "RoutingFactor" SG_ 74 IMU_McuVoltSta 0;
BA_ "UserSigValidity" SG_ 74 IMU_McuVoltSta 3;
BA_ "Description" SG_ 74 IMU_McuVoltSta "This signal indicates the failure status of MCU.



0000B : No failure



xxx1B : MCU failure



xx1xB : Under voltage detected



x1xxB : Over voltage detected



1xxxB : Bus off failure



The status information(xxx1B) occurs when MCU error is detected";
BA_ "Version" SG_ 74 IMU_AcuRstSta "20.03.05";
BA_ "RoutingFactor" SG_ 74 IMU_AcuRstSta 0;
BA_ "UserSigValidity" SG_ 74 IMU_AcuRstSta 3;
BA_ "Description" SG_ 74 IMU_AcuRstSta "This signal indicates the status of IMU.



0000B : Normal mode 



xxx1B : IMU Reset mode



xx1xB : Reserved



x1xxB : Reserved



1xxxB : Reserved



If ACU reset is required, ACU will send IMU RESET bit(XXX1B) up to 30 times and perform a reset. If ";
BA_ "Version" SG_ 74 IMU_SnsrTyp "25.03.01";
BA_ "RoutingFactor" SG_ 74 IMU_SnsrTyp 0;
BA_ "UserSigValidity" SG_ 74 IMU_SnsrTyp 3;
BA_ "GenSigStartValue" SG_ 74 IMU_SnsrTyp 2;
BA_ "Description" SG_ 74 IMU_SnsrTyp "This signal indicates supported signals that are correspond to sensor type.

1000B = IMU (yaw rate and longitudinal / lateral acceleration)

1100B = IMU (yaw / roll rate and longitudinal / lateral acceleration)

1010B = IMU (yaw rate and longitudinal / l";
BA_ "Version" SG_ 74 IMU_RollSigSta "25.06.01";
BA_ "RoutingFactor" SG_ 74 IMU_RollSigSta 0;
BA_ "UserSigValidity" SG_ 74 IMU_RollSigSta 3;
BA_ "GenSigStartValue" SG_ 74 IMU_RollSigSta 2;
BA_ "Description" SG_ 74 IMU_RollSigSta "This signal indicates failure status of roll rate signal and roll rate sensing element.



0000B : No failure 



xxx1B : IMU_Roll rate failure



xx1xB : Initialization is running



x1xxB : Reserved



1xxxB : Not applied



This signal represents the ";
BA_ "Version" SG_ 74 IMU_PitchSigSta "25.06.01";
BA_ "RoutingFactor" SG_ 74 IMU_PitchSigSta 0;
BA_ "UserSigValidity" SG_ 74 IMU_PitchSigSta 3;
BA_ "GenSigStartValue" SG_ 74 IMU_PitchSigSta 2;
BA_ "Description" SG_ 74 IMU_PitchSigSta "This signal indicates failure status of pitch rate signal and pitch rate sensing element.



0000B : No failure 



xxx1B : IMU_Pitchrate_failure



xx1xB : Initialization is running



x1xxB : Reserved



1xxxB : Not applied



This signal represents th";
BA_ "Version" SG_ 74 IMU_YawRtVal "20.03.05";
BA_ "RoutingFactor" SG_ 74 IMU_YawRtVal 0;
BA_ "UserSigValidity" SG_ 74 IMU_YawRtVal 3;
BA_ "GenSigStartValue" SG_ 74 IMU_YawRtVal 32768;
BA_ "Description" SG_ 74 IMU_YawRtVal "This signal indicates Information regarding yaw rate.



physical range : -163.84..163.83 ˚/s = 0000H..FFFEh



Conversion : (PH) = ((HEX)-8000H)*0.005[˚/s/digit]



                            = (HEX)*0.005[˚/s/digit] - 163.84[˚/s]



              ";
BA_ "Version" SG_ 74 IMU_LatAccelVal "20.03.05";
BA_ "RoutingFactor" SG_ 74 IMU_LatAccelVal 0;
BA_ "UserSigValidity" SG_ 74 IMU_LatAccelVal 3;
BA_ "GenSigStartValue" SG_ 74 IMU_LatAccelVal 32768;
BA_ "Description" SG_ 74 IMU_LatAccelVal "This signal indicates Information regarding lateral acceleration.



physical range : -4.1768g..4.1765g = 0000H..FFFEh



Conversion : (PH) = ((HEX)-8000H)*0.000127465[g/digit]



                            = (HEX)*0.000127465[g/digit] - 4.17677312[g]

";
BA_ "Version" SG_ 74 IMU_LongAccelVal "20.03.05";
BA_ "RoutingFactor" SG_ 74 IMU_LongAccelVal 0;
BA_ "UserSigValidity" SG_ 74 IMU_LongAccelVal 3;
BA_ "GenSigStartValue" SG_ 74 IMU_LongAccelVal 32768;
BA_ "Description" SG_ 74 IMU_LongAccelVal "This signal indicates information regarding longitudinal acceleration.



physical range : -4.1768g..4.1765g = 0000H..FFFEh



Conversion : (PH) = ((HEX)-8000H)*0.000127465[g/digit]



                            = (HEX)*0.000127465[g/digit] - 4.17677312";
BA_ "Version" SG_ 194 BMS_FD_Crc1Val "22.10.20";
BA_ "UserSigValidity" SG_ 194 BMS_FD_Crc1Val 3;
BA_ "GenSigStartValue" SG_ 194 BMS_FD_Crc1Val 65535;
BA_ "GenSigSendType" SG_ 194 BMS_FD_Crc1Val 2;
BA_ "Description" SG_ 194 BMS_FD_Crc1Val "The data area for CRC calculation is based on the data length (DLC) of the message DB.

The CRC shall be calculated over the entire data block (excluding the CRC bytes) including the user data, alive counter and Data ID



- CRC Polynomial (0x1021) , Ini";
BA_ "Version" SG_ 194 BMS_FD_AlvCnt1Val "22.10.20";
BA_ "UserSigValidity" SG_ 194 BMS_FD_AlvCnt1Val 3;
BA_ "GenSigSendType" SG_ 194 BMS_FD_AlvCnt1Val 2;
BA_ "Description" SG_ 194 BMS_FD_AlvCnt1Val "For the first transmission request for a data element the counter shall be initialized with 0 and shall be incremented by 1 for every subsequent send request. 

When the counter reaches the maximum value(0xFF), then it shall restart with 0 for the next s";
BA_ "Version" SG_ 194 xEV_BatEvtAlarm_HS "20.04.06";
BA_ "UserSigValidity" SG_ 194 xEV_BatEvtAlarm_HS 0;
BA_ "GenSigSendType" SG_ 194 xEV_BatEvtAlarm_HS 2;
BA_ "Description" SG_ 194 xEV_BatEvtAlarm_HS "Battery Emergency Event Alarm Flag";
BA_ "Version" SG_ 194 xEV_BMS_WakeUpReqfor12V "22.04.02";
BA_ "UserSigValidity" SG_ 194 xEV_BMS_WakeUpReqfor12V 0;
BA_ "GenSigSendType" SG_ 194 xEV_BMS_WakeUpReqfor12V 2;
BA_ "Description" SG_ 194 xEV_BMS_WakeUpReqfor12V "BMS-PDC/ICU Wake Up, PLBM Discharge Reqest Signal for12V Li-thium Battery";
BA_ "Version" SG_ 194 xEV_AuxBattChrgReq_HS "23.02.01";
BA_ "UserSigValidity" SG_ 194 xEV_AuxBattChrgReq_HS 7;
BA_ "GenSigSendType" SG_ 194 xEV_AuxBattChrgReq_HS 2;
BA_ "Description" SG_ 194 xEV_AuxBattChrgReq_HS "(12V Lithium Battery) Aux. Battery Charge Request Flag (HS-CAN)

LV2 Charge Request : Battery Saver

LV1 Charge Request : Auxiliary Charge";
BA_ "Version" SG_ 194 xEV_12VBatAlarmReq_HS "21.05.01";
BA_ "UserSigValidity" SG_ 194 xEV_12VBatAlarmReq_HS 0;
BA_ "GenSigSendType" SG_ 194 xEV_12VBatAlarmReq_HS 2;
BA_ "Description" SG_ 194 xEV_12VBatAlarmReq_HS "BMS-PDC/ICU 3rd Cut-off, Alarm Request for12V Li-thium Battery";
BA_ "Version" SG_ 194 BMS_ResetWakeup "24.04.03";
BA_ "UserSigValidity" SG_ 194 BMS_ResetWakeup 0;
BA_ "GenSigSendType" SG_ 194 BMS_ResetWakeup 2;
BA_ "Description" SG_ 194 BMS_ResetWakeup "All vehicle controller reset functions

(12V LFP BMS controller only)

Send when reset condition is satisfied";
BA_ "Version" SG_ 194 xEV_IG3OnReq "25.11.00";
BA_ "NetworkRequest" SG_ 194 xEV_IG3OnReq 0;
BA_ "UserSigValidity" SG_ 194 xEV_IG3OnReq 5;
BA_ "GenSigSendType" SG_ 194 xEV_IG3OnReq 2;
BA_ "Version" SG_ 1048 GNSS_Crc6Val "22.10.20";
BA_ "UserSigValidity" SG_ 1048 GNSS_Crc6Val 3;
BA_ "GenSigStartValue" SG_ 1048 GNSS_Crc6Val 65535;
BA_ "Description" SG_ 1048 GNSS_Crc6Val "The data area for CRC calculation is based on the data length (DLC) of the message DB.

The CRC shall be calculated over the entire data block (excluding the CRC bytes) including the user data, alive counter and Data ID



- CRC Polynomial (0x1021) , Ini";
BA_ "Version" SG_ 1048 HU_MM_Altitude "22.07.05";
BA_ "UserSigValidity" SG_ 1048 HU_MM_Altitude 1;
BA_ "Description" SG_ 1048 HU_MM_Altitude "MSL

range = -40000 <= Value <= 1000000

unit = cm";
BA_ "Version" SG_ 1048 GNSS_AlvCnt6Val "22.10.20";
BA_ "UserSigValidity" SG_ 1048 GNSS_AlvCnt6Val 3;
BA_ "Description" SG_ 1048 GNSS_AlvCnt6Val "For the first transmission request for a data element the counter shall be initialized with 0 and shall be incremented by 1 for every subsequent send request. 

When the counter reaches the maximum value(0xFF), then it shall restart with 0 for the next s";
BA_ "Version" SG_ 1048 HU_MM_Heading "22.07.05";
BA_ "UserSigValidity" SG_ 1048 HU_MM_Heading 1;
BA_ "Description" SG_ 1048 HU_MM_Heading "range = 0<=Valud <360";
BA_ "Version" SG_ 1048 GNSS_MM_type "22.07.05";
BA_ "UserSigValidity" SG_ 1048 GNSS_MM_type 1;
BA_ "GenSigStartValue" SG_ 1048 GNSS_MM_type 15;
BA_ "Version" SG_ 1048 HU_MM_Latitude "22.07.05";
BA_ "UserSigValidity" SG_ 1048 HU_MM_Latitude 1;
BA_ "Description" SG_ 1048 HU_MM_Latitude "range = -90*1,000,000 <= Value <=90*1,000,000

unit = degree*1,000,000";
BA_ "Version" SG_ 1048 HU_MM_Longitude "22.07.05";
BA_ "UserSigValidity" SG_ 1048 HU_MM_Longitude 1;
BA_ "Description" SG_ 1048 HU_MM_Longitude "range = -180*1,000,000 <= Value <= 180*1,000,000

unit = degree*1,000,000";
BA_ "Version" SG_ 1051 HU_CLOCK_Crc1Val "22.10.20";
BA_ "UserSigValidity" SG_ 1051 HU_CLOCK_Crc1Val 3;
BA_ "GenSigStartValue" SG_ 1051 HU_CLOCK_Crc1Val 65535;
BA_ "GenSigSendType" SG_ 1051 HU_CLOCK_Crc1Val 4;
BA_ "Description" SG_ 1051 HU_CLOCK_Crc1Val "The data area for CRC calculation is based on the data length (DLC) of the message DB.

The CRC shall be calculated over the entire data block (excluding the CRC bytes) including the user data, alive counter and Data ID



- CRC Polynomial (0x1021) , Ini";
BA_ "Version" SG_ 1051 HU_DisplayYear1 "18.09.02";
BA_ "NetworkRequest" SG_ 1051 HU_DisplayYear1 0;
BA_ "UserSigValidity" SG_ 1051 HU_DisplayYear1 0;
BA_ "GenSigStartValue" SG_ 1051 HU_DisplayYear1 3;
BA_ "GenSigSendType" SG_ 1051 HU_DisplayYear1 4;
BA_ "Version" SG_ 1051 HU_DisplayYear2 "21.07.07";
BA_ "NetworkRequestHoldingTime" SG_ 1051 HU_DisplayYear2 200;
BA_ "NetworkRequest" SG_ 1051 HU_DisplayYear2 0;
BA_ "UserSigValidity" SG_ 1051 HU_DisplayYear2 0;
BA_ "GenSigStartValue" SG_ 1051 HU_DisplayYear2 255;
BA_ "GenSigSendType" SG_ 1051 HU_DisplayYear2 4;
BA_ "Version" SG_ 1051 HU_DisplayDay "21.07.07";
BA_ "NetworkRequestHoldingTime" SG_ 1051 HU_DisplayDay 200;
BA_ "NetworkRequest" SG_ 1051 HU_DisplayDay 0;
BA_ "UserSigValidity" SG_ 1051 HU_DisplayDay 0;
BA_ "GenSigStartValue" SG_ 1051 HU_DisplayDay 255;
BA_ "GenSigSendType" SG_ 1051 HU_DisplayDay 4;
BA_ "Version" SG_ 1051 HU_AM_PM_INFO "18.09.02";
BA_ "NetworkRequest" SG_ 1051 HU_AM_PM_INFO 0;
BA_ "UserSigValidity" SG_ 1051 HU_AM_PM_INFO 0;
BA_ "GenSigStartValue" SG_ 1051 HU_AM_PM_INFO 3;
BA_ "GenSigSendType" SG_ 1051 HU_AM_PM_INFO 4;
BA_ "Version" SG_ 1051 HU_ComRefresh "18.09.02";
BA_ "NetworkRequest" SG_ 1051 HU_ComRefresh 0;
BA_ "UserSigValidity" SG_ 1051 HU_ComRefresh 0;
BA_ "GenSigStartValue" SG_ 1051 HU_ComRefresh 3;
BA_ "GenSigSendType" SG_ 1051 HU_ComRefresh 4;
BA_ "Version" SG_ 1051 HU_ClockInfo "18.09.02";
BA_ "NetworkRequest" SG_ 1051 HU_ClockInfo 0;
BA_ "UserSigValidity" SG_ 1051 HU_ClockInfo 0;
BA_ "GenSigStartValue" SG_ 1051 HU_ClockInfo 3;
BA_ "GenSigSendType" SG_ 1051 HU_ClockInfo 4;
BA_ "Version" SG_ 1051 HU_CLOCK_AlvCnt1Val "22.10.20";
BA_ "UserSigValidity" SG_ 1051 HU_CLOCK_AlvCnt1Val 3;
BA_ "GenSigSendType" SG_ 1051 HU_CLOCK_AlvCnt1Val 4;
BA_ "Description" SG_ 1051 HU_CLOCK_AlvCnt1Val "For the first transmission request for a data element the counter shall be initialized with 0 and shall be incremented by 1 for every subsequent send request. 

When the counter reaches the maximum value(0xFF), then it shall restart with 0 for the next s";
BA_ "Version" SG_ 1051 HU_TimeSetting "18.09.02";
BA_ "NetworkRequest" SG_ 1051 HU_TimeSetting 0;
BA_ "UserSigValidity" SG_ 1051 HU_TimeSetting 0;
BA_ "GenSigStartValue" SG_ 1051 HU_TimeSetting 3;
BA_ "GenSigSendType" SG_ 1051 HU_TimeSetting 4;
BA_ "Version" SG_ 1051 HU_Status "21.07.07";
BA_ "NetworkRequestHoldingTime" SG_ 1051 HU_Status 200;
BA_ "NetworkRequest" SG_ 1051 HU_Status 0;
BA_ "UserSigValidity" SG_ 1051 HU_Status 0;
BA_ "GenSigStartValue" SG_ 1051 HU_Status 15;
BA_ "GenSigSendType" SG_ 1051 HU_Status 4;
BA_ "Version" SG_ 1051 HU_TimeFormat "18.09.02";
BA_ "NetworkRequest" SG_ 1051 HU_TimeFormat 0;
BA_ "UserSigValidity" SG_ 1051 HU_TimeFormat 0;
BA_ "GenSigStartValue" SG_ 1051 HU_TimeFormat 3;
BA_ "GenSigSendType" SG_ 1051 HU_TimeFormat 4;
BA_ "Version" SG_ 1051 HU_DisplayHour "21.07.07";
BA_ "NetworkRequestHoldingTime" SG_ 1051 HU_DisplayHour 200;
BA_ "NetworkRequest" SG_ 1051 HU_DisplayHour 0;
BA_ "UserSigValidity" SG_ 1051 HU_DisplayHour 0;
BA_ "GenSigStartValue" SG_ 1051 HU_DisplayHour 255;
BA_ "GenSigSendType" SG_ 1051 HU_DisplayHour 4;
BA_ "Version" SG_ 1051 HU_DisplayMinute "21.07.07";
BA_ "NetworkRequestHoldingTime" SG_ 1051 HU_DisplayMinute 200;
BA_ "NetworkRequest" SG_ 1051 HU_DisplayMinute 0;
BA_ "UserSigValidity" SG_ 1051 HU_DisplayMinute 0;
BA_ "GenSigStartValue" SG_ 1051 HU_DisplayMinute 255;
BA_ "GenSigSendType" SG_ 1051 HU_DisplayMinute 4;
BA_ "Version" SG_ 1051 HU_DisplaySecond "21.07.07";
BA_ "NetworkRequestHoldingTime" SG_ 1051 HU_DisplaySecond 200;
BA_ "NetworkRequest" SG_ 1051 HU_DisplaySecond 0;
BA_ "UserSigValidity" SG_ 1051 HU_DisplaySecond 0;
BA_ "GenSigStartValue" SG_ 1051 HU_DisplaySecond 255;
BA_ "GenSigSendType" SG_ 1051 HU_DisplaySecond 4;
BA_ "Version" SG_ 1051 HU_DisplayMonth "21.07.07";
BA_ "NetworkRequestHoldingTime" SG_ 1051 HU_DisplayMonth 200;
BA_ "NetworkRequest" SG_ 1051 HU_DisplayMonth 0;
BA_ "UserSigValidity" SG_ 1051 HU_DisplayMonth 0;
BA_ "GenSigStartValue" SG_ 1051 HU_DisplayMonth 15;
BA_ "GenSigSendType" SG_ 1051 HU_DisplayMonth 4;
BA_ "Version" SG_ 1052 HU_CLU_Crc2Val "22.10.20";
BA_ "UserSigValidity" SG_ 1052 HU_CLU_Crc2Val 3;
BA_ "GenSigStartValue" SG_ 1052 HU_CLU_Crc2Val 65535;
BA_ "GenSigSendType" SG_ 1052 HU_CLU_Crc2Val 4;
BA_ "Description" SG_ 1052 HU_CLU_Crc2Val "The data area for CRC calculation is based on the data length (DLC) of the message DB.

The CRC shall be calculated over the entire data block (excluding the CRC bytes) including the user data, alive counter and Data ID



- CRC Polynomial (0x1021) , Ini";
BA_ "Version" SG_ 1052 HU_EVSupport "22.06.01";
BA_ "UserSigValidity" SG_ 1052 HU_EVSupport 7;
BA_ "GenSigStartValue" SG_ 1052 HU_EVSupport 3;
BA_ "GenSigSendType" SG_ 1052 HU_EVSupport 4;
BA_ "Description" SG_ 1052 HU_EVSupport "Notification whether EV function support or not.";
BA_ "Version" SG_ 1052 HU_DayNightState "22.06.01";
BA_ "UserSigValidity" SG_ 1052 HU_DayNightState 0;
BA_ "GenSigSendType" SG_ 1052 HU_DayNightState 4;
BA_ "Description" SG_ 1052 HU_DayNightState "HU(AVNT) display day and night time state (When automatically adjusted)";
BA_ "Version" SG_ 1052 HU_AutoBrightState_New "22.06.01";
BA_ "UserSigValidity" SG_ 1052 HU_AutoBrightState_New 0;
BA_ "GenSigSendType" SG_ 1052 HU_AutoBrightState_New 4;
BA_ "Description" SG_ 1052 HU_AutoBrightState_New "HU Display Brightness State(When automatically adjusted)";
BA_ "Version" SG_ 1052 HU_CLU_AlvCnt2Val "22.10.20";
BA_ "UserSigValidity" SG_ 1052 HU_CLU_AlvCnt2Val 3;
BA_ "GenSigSendType" SG_ 1052 HU_CLU_AlvCnt2Val 4;
BA_ "Description" SG_ 1052 HU_CLU_AlvCnt2Val "For the first transmission request for a data element the counter shall be initialized with 0 and shall be incremented by 1 for every subsequent send request. 

When the counter reaches the maximum value(0xFF), then it shall restart with 0 for the next s";
BA_ "Version" SG_ 1052 HU_OffloadBtnReq "24.05.01";
BA_ "UserSigValidity" SG_ 1052 HU_OffloadBtnReq 1;
BA_ "GenSigStartValue" SG_ 1052 HU_OffloadBtnReq 3;
BA_ "GenSigSendType" SG_ 1052 HU_OffloadBtnReq 4;
BA_ "Description" SG_ 1052 HU_OffloadBtnReq "Request to switch to off-road page";
BA_ "Version" SG_ 1052 HU_LanguageInfo "24.07.04";
BA_ "NetworkRequestHoldingTime" SG_ 1052 HU_LanguageInfo 5000;
BA_ "NetworkRequest" SG_ 1052 HU_LanguageInfo 0;
BA_ "UserSigValidity" SG_ 1052 HU_LanguageInfo 1;
BA_ "GenSigStartValue" SG_ 1052 HU_LanguageInfo 255;
BA_ "GenSigSendType" SG_ 1052 HU_LanguageInfo 4;
BA_ "Version" SG_ 1052 HU_MuteStatus "22.06.01";
BA_ "NetworkRequest" SG_ 1052 HU_MuteStatus 0;
BA_ "UserSigValidity" SG_ 1052 HU_MuteStatus 1;
BA_ "GenSigStartValue" SG_ 1052 HU_MuteStatus 3;
BA_ "GenSigSendType" SG_ 1052 HU_MuteStatus 4;
BA_ "Version" SG_ 1052 HU_WelcomeReady "22.07.05";
BA_ "UserSigValidity" SG_ 1052 HU_WelcomeReady 0;
BA_ "GenSigSendType" SG_ 1052 HU_WelcomeReady 4;
BA_ "Description" SG_ 1052 HU_WelcomeReady "H/U playback ready signal to play welcome/goodbye animation video.";
BA_ "Version" SG_ 1052 HU_UsmSupport "22.06.01";
BA_ "UserSigValidity" SG_ 1052 HU_UsmSupport 1;
BA_ "GenSigStartValue" SG_ 1052 HU_UsmSupport 3;
BA_ "GenSigSendType" SG_ 1052 HU_UsmSupport 4;
BA_ "Version" SG_ 1052 HU_NaviStatus "22.06.01";
BA_ "NetworkRequest" SG_ 1052 HU_NaviStatus 0;
BA_ "UserSigValidity" SG_ 1052 HU_NaviStatus 1;
BA_ "GenSigSendType" SG_ 1052 HU_NaviStatus 4;
BA_ "Version" SG_ 1052 HU_NaviDisp "22.06.01";
BA_ "NetworkRequest" SG_ 1052 HU_NaviDisp 0;
BA_ "UserSigValidity" SG_ 1052 HU_NaviDisp 1;
BA_ "GenSigStartValue" SG_ 1052 HU_NaviDisp 3;
BA_ "GenSigSendType" SG_ 1052 HU_NaviDisp 4;
BA_ "Version" SG_ 1052 HU_BVM_Display_Message "22.06.01";
BA_ "UserSigValidity" SG_ 1052 HU_BVM_Display_Message 3;
BA_ "GenSigStartValue" SG_ 1052 HU_BVM_Display_Message 7;
BA_ "GenSigSendType" SG_ 1052 HU_BVM_Display_Message 4;
BA_ "Version" SG_ 1052 HU_NaviCamSettingStatus "22.06.01";
BA_ "NetworkRequest" SG_ 1052 HU_NaviCamSettingStatus 0;
BA_ "UserSigValidity" SG_ 1052 HU_NaviCamSettingStatus 1;
BA_ "GenSigStartValue" SG_ 1052 HU_NaviCamSettingStatus 255;
BA_ "GenSigSendType" SG_ 1052 HU_NaviCamSettingStatus 4;
BA_REL_ "GenSigTimeoutTime" BU_SG_REL_ ARS_FD SG_ 745 PDC_FD_Crc15Val 1500;
BA_REL_ "GenSigTimeoutTime" BU_SG_REL_ ATS_FD SG_ 745 PDC_FD_Crc15Val 1500;
BA_REL_ "GenSigTimeoutTime" BU_SG_REL_ BLTN_CAM_FD SG_ 745 PDC_FD_Crc15Val 1500;
BA_REL_ "GenSigTimeoutTime" BU_SG_REL_ FCS_FD SG_ 745 PDC_FD_Crc15Val 1500;
BA_REL_ "GenSigTimeoutTime" BU_SG_REL_ GW_PSU_3RD_FD SG_ 745 PDC_FD_Crc15Val 1500;
BA_REL_ "GenSigTimeoutTime" BU_SG_REL_ GW_PSU_AST_FD SG_ 745 PDC_FD_Crc15Val 1500;
BA_REL_ "GenSigTimeoutTime" BU_SG_REL_ GW_PSU_DRV_FD SG_ 745 PDC_FD_Crc15Val 1500;
BA_REL_ "GenSigTimeoutTime" BU_SG_REL_ GW_PSU_RL_FD SG_ 745 PDC_FD_Crc15Val 1500;
BA_REL_ "GenSigTimeoutTime" BU_SG_REL_ GW_PSU_RR_FD SG_ 745 PDC_FD_Crc15Val 1500;
BA_REL_ "GenSigTimeoutTime" BU_SG_REL_ GW_SAU_DRV_FD SG_ 745 PDC_FD_Crc15Val 1500;
BA_REL_ "GenSigTimeoutTime" BU_SG_REL_ OHCL_FD SG_ 745 PDC_FD_Crc15Val 1500;
BA_REL_ "GenSigTimeoutTime" BU_SG_REL_ PSB_FD SG_ 745 PDC_FD_Crc15Val 1500;
BA_REL_ "GenSigTimeoutTime" BU_SG_REL_ RCM_FD SG_ 745 PDC_FD_Crc15Val 1500;
BA_REL_ "GenSigTimeoutTime" BU_SG_REL_ RCS_FD SG_ 745 PDC_FD_Crc15Val 1500;
BA_REL_ "GenSigTimeoutTime" BU_SG_REL_ RWPC_FD SG_ 745 PDC_FD_Crc15Val 1500;
BA_REL_ "GenSigTimeoutTime" BU_SG_REL_ SCM_FD SG_ 745 PDC_FD_Crc15Val 1500;
BA_REL_ "GenSigTimeoutTime" BU_SG_REL_ SGU_FD SG_ 745 PDC_FD_Crc15Val 1500;
BA_REL_ "GenSigTimeoutTime" BU_SG_REL_ SHVU_3RD_FD SG_ 745 PDC_FD_Crc15Val 1500;
BA_REL_ "GenSigTimeoutTime" BU_SG_REL_ SHVU_FRNT_FD SG_ 745 PDC_FD_Crc15Val 1500;
BA_REL_ "GenSigTimeoutTime" BU_SG_REL_ SHVU_REAR_FD SG_ 745 PDC_FD_Crc15Val 1500;
BA_REL_ "GenSigTimeoutTime" BU_SG_REL_ SHVU_RL_FD SG_ 745 PDC_FD_Crc15Val 1500;
BA_REL_ "GenSigTimeoutTime" BU_SG_REL_ SHVU_RR_FD SG_ 745 PDC_FD_Crc15Val 1500;
BA_REL_ "GenSigTimeoutTime" BU_SG_REL_ WPC2_FD SG_ 745 PDC_FD_Crc15Val 1500;
BA_REL_ "GenSigTimeoutTime" BU_SG_REL_ WPC_FD SG_ 745 PDC_FD_Crc15Val 1500;
BA_REL_ "GenSigTimeoutTime" BU_SG_REL_ ARS_FD SG_ 745 PDC_FD_AlvCnt15Val 1500;
BA_REL_ "GenSigTimeoutTime" BU_SG_REL_ ATS_FD SG_ 745 PDC_FD_AlvCnt15Val 1500;
BA_REL_ "GenSigTimeoutTime" BU_SG_REL_ BLTN_CAM_FD SG_ 745 PDC_FD_AlvCnt15Val 1500;
BA_REL_ "GenSigTimeoutTime" BU_SG_REL_ FCS_FD SG_ 745 PDC_FD_AlvCnt15Val 1500;
BA_REL_ "GenSigTimeoutTime" BU_SG_REL_ GW_PSU_3RD_FD SG_ 745 PDC_FD_AlvCnt15Val 1500;
BA_REL_ "GenSigTimeoutTime" BU_SG_REL_ GW_PSU_AST_FD SG_ 745 PDC_FD_AlvCnt15Val 1500;
BA_REL_ "GenSigTimeoutTime" BU_SG_REL_ GW_PSU_DRV_FD SG_ 745 PDC_FD_AlvCnt15Val 1500;
BA_REL_ "GenSigTimeoutTime" BU_SG_REL_ GW_PSU_RL_FD SG_ 745 PDC_FD_AlvCnt15Val 1500;
BA_REL_ "GenSigTimeoutTime" BU_SG_REL_ GW_PSU_RR_FD SG_ 745 PDC_FD_AlvCnt15Val 1500;
BA_REL_ "GenSigTimeoutTime" BU_SG_REL_ GW_SAU_DRV_FD SG_ 745 PDC_FD_AlvCnt15Val 1500;
BA_REL_ "GenSigTimeoutTime" BU_SG_REL_ OHCL_FD SG_ 745 PDC_FD_AlvCnt15Val 1500;
BA_REL_ "GenSigTimeoutTime" BU_SG_REL_ PSB_FD SG_ 745 PDC_FD_AlvCnt15Val 1500;
BA_REL_ "GenSigTimeoutTime" BU_SG_REL_ RCM_FD SG_ 745 PDC_FD_AlvCnt15Val 1500;
BA_REL_ "GenSigTimeoutTime" BU_SG_REL_ RCS_FD SG_ 745 PDC_FD_AlvCnt15Val 1500;
BA_REL_ "GenSigTimeoutTime" BU_SG_REL_ RWPC_FD SG_ 745 PDC_FD_AlvCnt15Val 1500;
BA_REL_ "GenSigTimeoutTime" BU_SG_REL_ SCM_FD SG_ 745 PDC_FD_AlvCnt15Val 1500;
BA_REL_ "GenSigTimeoutTime" BU_SG_REL_ SGU_FD SG_ 745 PDC_FD_AlvCnt15Val 1500;
BA_REL_ "GenSigTimeoutTime" BU_SG_REL_ SHVU_3RD_FD SG_ 745 PDC_FD_AlvCnt15Val 1500;
BA_REL_ "GenSigTimeoutTime" BU_SG_REL_ SHVU_FRNT_FD SG_ 745 PDC_FD_AlvCnt15Val 1500;
BA_REL_ "GenSigTimeoutTime" BU_SG_REL_ SHVU_REAR_FD SG_ 745 PDC_FD_AlvCnt15Val 1500;
BA_REL_ "GenSigTimeoutTime" BU_SG_REL_ SHVU_RL_FD SG_ 745 PDC_FD_AlvCnt15Val 1500;
BA_REL_ "GenSigTimeoutTime" BU_SG_REL_ SHVU_RR_FD SG_ 745 PDC_FD_AlvCnt15Val 1500;
BA_REL_ "GenSigTimeoutTime" BU_SG_REL_ WPC2_FD SG_ 745 PDC_FD_AlvCnt15Val 1500;
BA_REL_ "GenSigTimeoutTime" BU_SG_REL_ WPC_FD SG_ 745 PDC_FD_AlvCnt15Val 1500;
BA_REL_ "GenSigTimeoutTime" BU_SG_REL_ BLTN_CAM_FD SG_ 745 PDC_LDConReq 1500;
BA_REL_ "GenSigTimeoutTime" BU_SG_REL_ BLTN_CAM_FD SG_ 745 PDC_LDConReq_By_LVBat 1500;
BA_REL_ "GenSigTimeoutTime" BU_SG_REL_ BLTN_CAM_FD SG_ 745 PDC_LDConReq_By_ActiveOn 1500;
BA_REL_ "GenSigTimeoutTime" BU_SG_REL_ ARS_FD SG_ 745 PDC_ResetPreWrngForOthers 1500;
BA_REL_ "GenSigTimeoutTime" BU_SG_REL_ ATS_FD SG_ 745 PDC_ResetPreWrngForOthers 1500;
BA_REL_ "GenSigTimeoutTime" BU_SG_REL_ BLTN_CAM_FD SG_ 745 PDC_ResetPreWrngForOthers 1500;
BA_REL_ "GenSigTimeoutTime" BU_SG_REL_ DCM_FD SG_ 745 PDC_ResetPreWrngForOthers 1500;
BA_REL_ "GenSigTimeoutTime" BU_SG_REL_ FCS_FD SG_ 745 PDC_ResetPreWrngForOthers 1500;
BA_REL_ "GenSigTimeoutTime" BU_SG_REL_ GW_PSU_3RD_FD SG_ 745 PDC_ResetPreWrngForOthers 1500;
BA_REL_ "GenSigTimeoutTime" BU_SG_REL_ GW_PSU_AST_FD SG_ 745 PDC_ResetPreWrngForOthers 1500;
BA_REL_ "GenSigTimeoutTime" BU_SG_REL_ GW_PSU_DRV_FD SG_ 745 PDC_ResetPreWrngForOthers 1500;
BA_REL_ "GenSigTimeoutTime" BU_SG_REL_ GW_PSU_RL_FD SG_ 745 PDC_ResetPreWrngForOthers 1500;
BA_REL_ "GenSigTimeoutTime" BU_SG_REL_ GW_PSU_RR_FD SG_ 745 PDC_ResetPreWrngForOthers 1500;
BA_REL_ "GenSigTimeoutTime" BU_SG_REL_ GW_SAU_DRV_FD SG_ 745 PDC_ResetPreWrngForOthers 1500;
BA_REL_ "GenSigTimeoutTime" BU_SG_REL_ OHCL_FD SG_ 745 PDC_ResetPreWrngForOthers 1500;
BA_REL_ "GenSigTimeoutTime" BU_SG_REL_ PSB_FD SG_ 745 PDC_ResetPreWrngForOthers 1500;
BA_REL_ "GenSigTimeoutTime" BU_SG_REL_ RCM_FD SG_ 745 PDC_ResetPreWrngForOthers 1500;
BA_REL_ "GenSigTimeoutTime" BU_SG_REL_ RCS_FD SG_ 745 PDC_ResetPreWrngForOthers 1500;
BA_REL_ "GenSigTimeoutTime" BU_SG_REL_ RWPC_FD SG_ 745 PDC_ResetPreWrngForOthers 1500;
BA_REL_ "GenSigTimeoutTime" BU_SG_REL_ SCM_FD SG_ 745 PDC_ResetPreWrngForOthers 1500;
BA_REL_ "GenSigTimeoutTime" BU_SG_REL_ SGU_FD SG_ 745 PDC_ResetPreWrngForOthers 1500;
BA_REL_ "GenSigTimeoutTime" BU_SG_REL_ SHVU_3RD_FD SG_ 745 PDC_ResetPreWrngForOthers 1500;
BA_REL_ "GenSigTimeoutTime" BU_SG_REL_ SHVU_FRNT_FD SG_ 745 PDC_ResetPreWrngForOthers 1500;
BA_REL_ "GenSigTimeoutTime" BU_SG_REL_ SHVU_REAR_FD SG_ 745 PDC_ResetPreWrngForOthers 1500;
BA_REL_ "GenSigTimeoutTime" BU_SG_REL_ SHVU_RL_FD SG_ 745 PDC_ResetPreWrngForOthers 1500;
BA_REL_ "GenSigTimeoutTime" BU_SG_REL_ SHVU_RR_FD SG_ 745 PDC_ResetPreWrngForOthers 1500;
BA_REL_ "GenSigTimeoutTime" BU_SG_REL_ WPC2_FD SG_ 745 PDC_ResetPreWrngForOthers 1500;
BA_REL_ "GenSigTimeoutTime" BU_SG_REL_ WPC_FD SG_ 745 PDC_ResetPreWrngForOthers 1500;
BA_REL_ "GenSigTimeoutTime" BU_SG_REL_ ARS_FD SG_ 745 PDC_ResetReqForOthers 1500;
BA_REL_ "GenSigTimeoutTime" BU_SG_REL_ ATS_FD SG_ 745 PDC_ResetReqForOthers 1500;
BA_REL_ "GenSigTimeoutTime" BU_SG_REL_ BLTN_CAM_FD SG_ 745 PDC_ResetReqForOthers 1500;
BA_REL_ "GenSigTimeoutTime" BU_SG_REL_ DCM_FD SG_ 745 PDC_ResetReqForOthers 1500;
BA_REL_ "GenSigTimeoutTime" BU_SG_REL_ FCS_FD SG_ 745 PDC_ResetReqForOthers 1500;
BA_REL_ "GenSigTimeoutTime" BU_SG_REL_ GW_PSU_3RD_FD SG_ 745 PDC_ResetReqForOthers 1500;
BA_REL_ "GenSigTimeoutTime" BU_SG_REL_ GW_PSU_AST_FD SG_ 745 PDC_ResetReqForOthers 1500;
BA_REL_ "GenSigTimeoutTime" BU_SG_REL_ GW_PSU_DRV_FD SG_ 745 PDC_ResetReqForOthers 1500;
BA_REL_ "GenSigTimeoutTime" BU_SG_REL_ GW_PSU_RL_FD SG_ 745 PDC_ResetReqForOthers 1500;
BA_REL_ "GenSigTimeoutTime" BU_SG_REL_ GW_PSU_RR_FD SG_ 745 PDC_ResetReqForOthers 1500;
BA_REL_ "GenSigTimeoutTime" BU_SG_REL_ GW_SAU_DRV_FD SG_ 745 PDC_ResetReqForOthers 1500;
BA_REL_ "GenSigTimeoutTime" BU_SG_REL_ OHCL_FD SG_ 745 PDC_ResetReqForOthers 1500;
BA_REL_ "GenSigTimeoutTime" BU_SG_REL_ PSB_FD SG_ 745 PDC_ResetReqForOthers 1500;
BA_REL_ "GenSigTimeoutTime" BU_SG_REL_ RCM_FD SG_ 745 PDC_ResetReqForOthers 1500;
BA_REL_ "GenSigTimeoutTime" BU_SG_REL_ RCS_FD SG_ 745 PDC_ResetReqForOthers 1500;
BA_REL_ "GenSigTimeoutTime" BU_SG_REL_ RWPC_FD SG_ 745 PDC_ResetReqForOthers 1500;
BA_REL_ "GenSigTimeoutTime" BU_SG_REL_ SCM_FD SG_ 745 PDC_ResetReqForOthers 1500;
BA_REL_ "GenSigTimeoutTime" BU_SG_REL_ SGU_FD SG_ 745 PDC_ResetReqForOthers 1500;
BA_REL_ "GenSigTimeoutTime" BU_SG_REL_ SHVU_3RD_FD SG_ 745 PDC_ResetReqForOthers 1500;
BA_REL_ "GenSigTimeoutTime" BU_SG_REL_ SHVU_FRNT_FD SG_ 745 PDC_ResetReqForOthers 1500;
BA_REL_ "GenSigTimeoutTime" BU_SG_REL_ SHVU_REAR_FD SG_ 745 PDC_ResetReqForOthers 1500;
BA_REL_ "GenSigTimeoutTime" BU_SG_REL_ SHVU_RL_FD SG_ 745 PDC_ResetReqForOthers 1500;
BA_REL_ "GenSigTimeoutTime" BU_SG_REL_ SHVU_RR_FD SG_ 745 PDC_ResetReqForOthers 1500;
BA_REL_ "GenSigTimeoutTime" BU_SG_REL_ WPC2_FD SG_ 745 PDC_ResetReqForOthers 1500;
BA_REL_ "GenSigTimeoutTime" BU_SG_REL_ WPC_FD SG_ 745 PDC_ResetReqForOthers 1500;
BA_REL_ "GenSigTimeoutTime" BU_SG_REL_ DCM_FD SG_ 745 PDC_ResetFuncOpt 1500;
BA_REL_ "GenSigTimeoutTime" BU_SG_REL_ RWPC_FD SG_ 745 PDC_ResetFuncOpt 1500;
BA_REL_ "GenSigTimeoutTime" BU_SG_REL_ WPC2_FD SG_ 745 PDC_ResetFuncOpt 1500;
BA_REL_ "GenSigTimeoutTime" BU_SG_REL_ WPC_FD SG_ 745 PDC_ResetFuncOpt 1500;
BA_REL_ "GenSigTimeoutTime" BU_SG_REL_ BLTN_CAM_FD SG_ 1308 VAPI_BltnCamInsideSwEnable_Set 0;
BA_REL_ "GenSigTimeoutTime" BU_SG_REL_ BLTN_CAM_FD SG_ 613 HEV_BrkLtSwSta 1500;
BA_REL_ "GenSigTimeoutTime" BU_SG_REL_ BLTN_CAM_FD SG_ 1024 SVM_CamConfgSta 1500;
BA_REL_ "GenSigTimeoutTime" BU_SG_REL_ BLTN_CAM_FD SG_ 1024 SVM_OperatSta 1500;
BA_REL_ "GenSigTimeoutTime" BU_SG_REL_ BLTN_CAM_FD SG_ 1026 SMK_TrmnlCtrlStaBDCEV 1500;
BA_REL_ "GenSigTimeoutTime" BU_SG_REL_ SGU_FD SG_ 1026 SMK_PwrOnModeSta 1500;
BA_REL_ "GenSigTimeoutTime" BU_SG_REL_ ATS_FD SG_ 1026 Warn_DisWrngSta3 1500;
BA_REL_ "GenSigTimeoutTime" BU_SG_REL_ BLTN_CAM_FD SG_ 1026 SMK_TrmnlCtrlGrpStaBDC 1500;
BA_REL_ "GenSigTimeoutTime" BU_SG_REL_ BLTN_CAM_FD SG_ 1026 SMK_TrmnlCtrlGrpStaBDCEV 1500;
BA_REL_ "GenSigTimeoutTime" BU_SG_REL_ CGW_CCU SG_ 193 BLTN_CAM_UI_Mode_Tmt_Req 0;
BA_REL_ "GenSigTimeoutTime" BU_SG_REL_ CGW_CCU SG_ 193 BLTN_CAM_PopUp_Req 0;
BA_REL_ "GenSigTimeoutTime" BU_SG_REL_ CGW_CCU SG_ 193 BLTN_CAM_File_List_Renew 0;
BA_REL_ "GenSigTimeoutTime" BU_SG_REL_ CGW_CCU SG_ 193 BLTN_CAM_Wifi_Pwd_Chg_State 0;
BA_REL_ "GenSigTimeoutTime" BU_SG_REL_ CGW_CCU SG_ 193 BLTN_CAM_Dis_Touch_BeepSound 0;
BA_REL_ "GenSigTimeoutTime" BU_SG_REL_ BLTN_CAM_FD SG_ 345 MainLBM_CurrVal 1500;
BA_REL_ "GenSigTimeoutTime" BU_SG_REL_ BLTN_CAM_FD SG_ 345 MainLBM_SocVal 1500;
BA_REL_ "GenSigTimeoutTime" BU_SG_REL_ BLTN_CAM_FD SG_ 345 MainLBM_VtgVal 1500;
BA_REL_ "GenSigTimeoutTime" BU_SG_REL_ BLTN_CAM_FD SG_ 345 MainLBM_TempVal 1500;
BA_REL_ "GenSigTimeoutTime" BU_SG_REL_ BLTN_CAM_FD SG_ 345 MainLBM_SocErrSta 1500;
BA_REL_ "GenSigTimeoutTime" BU_SG_REL_ BLTN_CAM_FD SG_ 345 MainLBM_SohVal 1500;
BA_REL_ "GenSigTimeoutTime" BU_SG_REL_ BLTN_CAM_FD SG_ 345 MainLBM_SnsrInvldSta 1500;
BA_REL_ "GenSigTimeoutTime" BU_SG_REL_ BLTN_CAM_FD SG_ 345 MainLBM_RspErrSta 1500;
BA_REL_ "GenSigTimeoutTime" BU_SG_REL_ BLTN_CAM_FD SG_ 345 MainLBM_CapacityVal 1500;
BA_REL_ "GenSigTimeoutTime" BU_SG_REL_ BLTN_CAM_FD SG_ 345 MainLBM_SohErrSta 1500;
BA_REL_ "GenSigTimeoutTime" BU_SG_REL_ BLTN_CAM_FD SG_ 194 xEV_AuxBattChrgReq_HS 0;
BA_REL_ "GenSigTimeoutTime" BU_SG_REL_ BLTN_CAM_FD SG_ 194 xEV_12VBatAlarmReq_HS 0;
BA_REL_ "GenSigTimeoutTime" BU_SG_REL_ BLTN_CAM_FD SG_ 1048 HU_MM_Altitude 5000;
BA_REL_ "GenSigTimeoutTime" BU_SG_REL_ BLTN_CAM_FD SG_ 1048 HU_MM_Heading 5000;
BA_REL_ "GenSigTimeoutTime" BU_SG_REL_ BLTN_CAM_FD SG_ 1048 GNSS_MM_type 5000;
BA_REL_ "GenSigTimeoutTime" BU_SG_REL_ BLTN_CAM_FD SG_ 1048 HU_MM_Latitude 5000;
BA_REL_ "GenSigTimeoutTime" BU_SG_REL_ BLTN_CAM_FD SG_ 1048 HU_MM_Longitude 5000;
BA_REL_ "GenSigTimeoutTime" BU_SG_REL_ ATS_FD SG_ 1051 HU_DisplayYear1 5000;
BA_REL_ "GenSigTimeoutTime" BU_SG_REL_ BLTN_CAM_FD SG_ 1051 HU_DisplayYear1 5000;
BA_REL_ "GenSigTimeoutTime" BU_SG_REL_ ATS_FD SG_ 1051 HU_DisplayYear2 5000;
BA_REL_ "GenSigTimeoutTime" BU_SG_REL_ BLTN_CAM_FD SG_ 1051 HU_DisplayYear2 5000;
BA_REL_ "GenSigTimeoutTime" BU_SG_REL_ ATS_FD SG_ 1051 HU_DisplayDay 5000;
BA_REL_ "GenSigTimeoutTime" BU_SG_REL_ BLTN_CAM_FD SG_ 1051 HU_DisplayDay 5000;
BA_REL_ "GenSigTimeoutTime" BU_SG_REL_ ATS_FD SG_ 1051 HU_AM_PM_INFO 5000;
BA_REL_ "GenSigTimeoutTime" BU_SG_REL_ BLTN_CAM_FD SG_ 1051 HU_AM_PM_INFO 5000;
BA_REL_ "GenSigTimeoutTime" BU_SG_REL_ ATS_FD SG_ 1051 HU_ComRefresh 5000;
BA_REL_ "GenSigTimeoutTime" BU_SG_REL_ BLTN_CAM_FD SG_ 1051 HU_ComRefresh 5000;
BA_REL_ "GenSigTimeoutTime" BU_SG_REL_ ATS_FD SG_ 1051 HU_ClockInfo 5000;
BA_REL_ "GenSigTimeoutTime" BU_SG_REL_ BLTN_CAM_FD SG_ 1051 HU_ClockInfo 5000;
BA_REL_ "GenSigTimeoutTime" BU_SG_REL_ ATS_FD SG_ 1051 HU_TimeSetting 5000;
BA_REL_ "GenSigTimeoutTime" BU_SG_REL_ BLTN_CAM_FD SG_ 1051 HU_TimeSetting 5000;
BA_REL_ "GenSigTimeoutTime" BU_SG_REL_ ATS_FD SG_ 1051 HU_Status 5000;
BA_REL_ "GenSigTimeoutTime" BU_SG_REL_ BLTN_CAM_FD SG_ 1051 HU_Status 5000;
BA_REL_ "GenSigTimeoutTime" BU_SG_REL_ ATS_FD SG_ 1051 HU_TimeFormat 5000;
BA_REL_ "GenSigTimeoutTime" BU_SG_REL_ BLTN_CAM_FD SG_ 1051 HU_TimeFormat 5000;
BA_REL_ "GenSigTimeoutTime" BU_SG_REL_ ATS_FD SG_ 1051 HU_DisplayHour 5000;
BA_REL_ "GenSigTimeoutTime" BU_SG_REL_ BLTN_CAM_FD SG_ 1051 HU_DisplayHour 5000;
BA_REL_ "GenSigTimeoutTime" BU_SG_REL_ ATS_FD SG_ 1051 HU_DisplayMinute 5000;
BA_REL_ "GenSigTimeoutTime" BU_SG_REL_ BLTN_CAM_FD SG_ 1051 HU_DisplayMinute 5000;
BA_REL_ "GenSigTimeoutTime" BU_SG_REL_ ATS_FD SG_ 1051 HU_DisplaySecond 5000;
BA_REL_ "GenSigTimeoutTime" BU_SG_REL_ BLTN_CAM_FD SG_ 1051 HU_DisplaySecond 5000;
BA_REL_ "GenSigTimeoutTime" BU_SG_REL_ ATS_FD SG_ 1051 HU_DisplayMonth 5000;
BA_REL_ "GenSigTimeoutTime" BU_SG_REL_ BLTN_CAM_FD SG_ 1051 HU_DisplayMonth 5000;
BA_REL_ "GenSigTimeoutTime" BU_SG_REL_ ATS_FD SG_ 1052 HU_LanguageInfo 5000;
BA_REL_ "GenSigTimeoutTime" BU_SG_REL_ BLTN_CAM_FD SG_ 1052 HU_LanguageInfo 5000;
BA_REL_ "GenSigTimeoutTime" BU_SG_REL_ DCM_FD SG_ 1052 HU_LanguageInfo 5000;
VAL_ 745 PDC_FD_Crc15Val 0 "0x0~0xFFFF:CRCValue" 65535 "0x0~0xFFFF:CRCValue" ;
VAL_ 745 PDC_CurrAtReset 0 "0x0~0xFFE:-40,940mA ~ 0mA" 4094 "0x0~0xFFE:-40,940mA ~ 0mA" 4095 "Error" ;
VAL_ 745 PDC_AvgCurrAtReset 0 "0x0~0xFFE:-40,940mA ~ 0mA" 4094 "0x0~0xFFE:-40,940mA ~ 0mA" 4095 "Error" ;
VAL_ 745 PDC_ResetReason 0 "No Reset" 1 "Reset By Non-Sleep" 2 "Reset By Current" 3 "RESERVED" 4 "RESERVED" 5 "RESERVED" 6 "RESERVED" 7 "RESERVED" ;
VAL_ 745 PDC_CumulativeCountOf12VReq 0 "0x0~0x3FF:0~1023" 1023 "0x0~0x3FF:0~1023" ;
VAL_ 745 PDC_CumulativeCountOfCCUReq 0 "0x0~0x3FF:0~1023" 1023 "0x0~0x3FF:0~1023" ;
VAL_ 745 PDC_VehCondiForReset 0 "Not Ready" 1 "Ready" 2 "RESERVED" 3 "Invalid" ;
VAL_ 745 PDC_FD_AlvCnt15Val 0 "0x0~0xFF:AlvCntValue" 255 "0x0~0xFF:AlvCntValue" ;
VAL_ 745 PDC_LDConReq 0 "Off (Default)" 1 "On" 2 "RESERVED" 3 "RESERVED" ;
VAL_ 745 PDC_LDConReq_By_LVBat 0 "Off (Default)" 1 "On" 2 "RESERVED" 3 "RESERVED" ;
VAL_ 745 PDC_LDConReq_By_OTA 0 "Off (Default)" 1 "On" 2 "RESERVED" 3 "RESERVED" ;
VAL_ 745 PDC_LDConReq_By_Load 0 "Off (Default)" 1 "On" 2 "RESERVED" 3 "RESERVED" ;
VAL_ 745 PDC_LDConReq_By_ActiveOn 0 "Off (Default)" 1 "On" 2 "RESERVED" 3 "RESERVED" ;
VAL_ 745 PDC_ResetPreWrngForCCU 0 "No Warning" 1 "Warning" 2 "RESERVED" 3 "Invalid" ;
VAL_ 745 PDC_ResetPreWrngForOthers 0 "No Warning" 1 "Warning" 2 "RESERVED" 3 "Invalid" ;
VAL_ 745 PDC_ResetReqForCCU 0 "No Requeset" 1 "Reset Requeset" 2 "RESERVED" 3 "Invalid" ;
VAL_ 745 PDC_ResetReqForOthers 0 "No Requeset" 1 "Reset Requeset" 2 "RESERVED" 3 "Invalid" ;
VAL_ 745 PDC_ResetFuncOpt 0 "Not Applied" 1 "Applied" 2 "RESERVED" 3 "Invalid" ;
VAL_ 745 PDC_12VRlyCtrl 0 "No Request" 1 "Relay On request" 2 "Relay Off request" 3 "Invalid" ;
VAL_ 745 PDC_CurrentValueForReset 0 "No Setting" 1 "1~0xFE:50mA ~ 12700mA" 254 "1~0xFE:50mA ~ 12700mA" 255 "Invalid" ;
VAL_ 745 PDC_WakeUpReqForReset 0 "No Wakeup(Default)" 1 "Wakeup" 2 "RESERVED" 3 "RESERVED" ;
VAL_ 745 PDC_TimeValueForReset 0 "No Setting" 1 "1~0xFE:0.5h ~ 127h" 254 "1~0xFE:0.5h ~ 127h" 255 "Invalid" ;
VAL_ 745 PDC_12VRlyOffHoldingTime 0 "No Setting" 1 "0.5s ~ 15s" 2 "0.5s ~ 15s" 3 "0.5s ~ 15s" 4 "0.5s ~ 15s" 5 "0.5s ~ 15s" 6 "0.5s ~ 15s" 7 "0.5s ~ 15s" 8 "0.5s ~ 15s" 9 "0.5s ~ 15s" 10 "0.5s ~ 15s" 11 "0.5s ~ 15s" 12 "0.5s ~ 15s" 13 "0.5s ~ 15s" 14 "0.5s ~ 15s" 15 "0.5s ~ 15s" 16 "0.5s ~ 15s" 17 "0.5s ~ 15s" 18 "0.5s ~ 15s" 19 "0.5s ~ 15s" 20 "0.5s ~ 15s" 21 "0.5s ~ 15s" 22 "0.5s ~ 15s" 23 "0.5s ~ 15s" 24 "0.5s ~ 15s" 25 "0.5s ~ 15s" 26 "0.5s ~ 15s" 27 "0.5s ~ 15s" 28 "0.5s ~ 15s" 29 "0.5s ~ 15s" 30 "0.5s ~ 15s" 31 "Invalid" ;
VAL_ 745 PDC_ResetCountSetting 0 "No Setting" 1 "1~3" 2 "1~3" 3 "1~3" ;
VAL_ 745 PDC_ResetCount 0 "No Setting" 1 "1~3" 2 "1~3" 3 "1~3" ;
VAL_ 745 PDC_ResetCumulativeCount 0 "0x0~0x3FF:0~1023" 1023 "0x0~0x3FF:0~1023" ;
VAL_ 745 PDC_ResetOpsta 0 "Normal" 1 "Reset Complete" 2 "Reset Fail" 3 "RESERVED" ;
VAL_ 745 PDC_ReadyTimeValueForReset 0 "No Setting" 1 "1~0xFE:10min~254min/0XFF: Invalid" 254 "1~0xFE:10min~254min/0XFF: Invalid" ;
VAL_ 64 TCU_DcmlVehSpdKphVal 0 "Error Indicator" ;
VAL_ 64 TCU_GearLmpBlnkngReq 0 "No blink" 1 "Request lamp blinking" 2 "Not used" 3 "Error Indicator" ;
VAL_ 64 TCU_FuelCutInhbtReq 0 "No request" 1 "Fuel cut inhibition request from TCU" 2 "Not used" 3 "Error Indicator" ;
VAL_ 64 TCU_IdleUpReq 0 "No IDLE UP request" 1 "IDLE UP request" 2 "Not used" 3 "Error Indicator" ;
VAL_ 64 TCU_EngRpmDis 65535 "Error Indicator" ;
VAL_ 64 TCU_EngSpdIncReq 0 "No request" 1 "Engine speed increase is requested" 2 "Not used" 3 "Error Indicator" ;
VAL_ 64 TCU_ObdSta 0 "Default" 2 "Failure information of TCU" 3 "Failure information of TCU" 4 "MIL on request" 5 "MIL on request" 6 "Failure information of TCU & MIL on request" 7 "Failure information of TCU & MIL on request" ;
VAL_ 64 TCU_SprtyIndxSta 0 "Invalid" 1 "Step 1" 2 "Step 2" 3 "Step 3" 4 "Step 4" 5 "Step 5" 6 "Step 6" 7 "Step 7" 8 "Step 8" 9 "Step 9" 10 "Step 10" 11 "Step 11" 12 "Step 12" 13 "Step 13" 14 "Step 14" 15 "Step 15" 16 "Step 16" 17 "Step 17" 18 "Step 18" 19 "Step 19" 20 "Step 20" 21 "Step 21" 22 "Step 22" 23 "Step 23" 24 "Step 24" 25 "Step 25" 26 "Invalid" 27 "Invalid" 28 "Invalid" 29 "Invalid" 30 "Invalid" 31 "Invalid" ;
VAL_ 64 TCU_DrvngModDis 0 "Inactive" 1 "Normal" 2 "Eco" 3 "Eco+" 4 "Sport" 5 "Sport+" 6 "Snow" 7 "Reserved" ;
VAL_ 64 TCU_DrvngModReq 0 "Inactive" 1 "Normal" 2 "Eco" 3 "Eco+" 4 "Sport" 5 "Sport+" 6 "Snow" 7 "Reserved" ;
VAL_ 64 TCU_SmrtShftSta 0 "Smart Shift not Applied" 1 "Smart Shift Applied" 2 "Not used" 3 "Error Indicator" ;
VAL_ 64 TCU_FrtStcShftSta 0 "First static shift function is not activated." 1 "First static shift function is activated" 2 "Not used" 3 "Error Indicator" ;
VAL_ 64 TCU_IsgInhbtReq 0 "TCU inhibits the ISG function" 1 "ISG is available" 2 "Not used" 3 "Error Indicator" ;
VAL_ 64 TCU_CdaInhbtReq 0 "CDA transition is available" 1 "TCU prohibits CDA transition" 2 "Not used" 3 "Error Indicator" ;
VAL_ 64 TCU_BrkOnReq 0 "No request" 1 "Brake On Request" 2 "Not used" 3 "Error Indicator" ;
VAL_ 64 TCU_TqGrdntLimVal 255 "No torque gradient limitation" ;
VAL_ 64 TCU_NetrlCtrlSta 0 "No NC" 1 "NC Entry" 2 "NC Applied" 3 "NC Exit" ;
VAL_ 64 TCU_ShftPtrnSta 0 "Normal (ECO)" 1 "Uphill 1 (Optional)" 2 "Uphill 2 (Optional)" 3 "Reserved" 4 "Downhill 1 (Optional)" 5 "Cruise (Optional)" 6 "Cruise_Uphill 1 (Optional)" 7 "Cruise_Uphill 2 (Optional)" 8 "Active ECO (Optional)" 9 "Sport Drive (Optional)" 15 "None of the above" ;
VAL_ 64 TCU_VgisInhbtReq 0 "There’s no request from TCU" 1 "TCU inhibits ECU from changing VGIS status" 2 "Not used" 3 "Error Indicator" ;
VAL_ 64 TCU_EngTqIncReqVal 0 "No request" 2047 "Max. Increase" 2048 "reduction to 0 torque" ;
VAL_ 64 TCU_EPBReq 0 "No Request (default)" 1 "EPB Request" ;
VAL_ 64 IMT_EOLstate 0 "display gear info using 'TCU_GearSlctDis'" 1 "display gear info by alphabet 'E'" ;
VAL_ 64 IMT_DisCmd 0 "Not Display" 1 "Display (Not blinking)" 2 "Display (blinking)" 3 "Reserved" ;
VAL_ 64 DCT_RegenInhbt 0 "No Inhibit" 1 "Regen. Inhibit" 2 "Not Used" 3 "Error Indicator" ;
VAL_ 64 DCT_EngIdleReq 0 "No Request" 1 "Idle Request" 2 "Not Used" 3 "Error Indicator" ;
VAL_ 64 DCT_CltchState 0 "Drivetrain (Both Clutch) Open" 1 "Odd Clutch Slipping" 2 "Even Clutch Slipping" 3 "Clutch Locked" ;
VAL_ 64 DCT_FuelCutReq 0 "No request" 1 "Fuel Cut Request" 2 "Not Used" 3 "Error Indicator" ;
VAL_ 64 DCT_TqIncReq 0 "No Request" 1 "Torque increase Request" 2 "Not Used" 3 "Error Indicator" ;
VAL_ 64 DCT_ShftTqReq 0 "No request" 2047 "Max. Increase" 2048 "reduction to 0 torque" ;
VAL_ 64 TCU_GearSlctDis 0 "P" 1 "L" 2 "2" 3 "3" 4 "DS Mode" 5 "D" 6 "N" 7 "R" 8 "sports mode / manual shift / paddle shift" 9 "Not Display at Cluster" 10 "Sub-Rom Communication" 11 "Sub-Rom Communication Error" 12 "Paddle shift (D-position)" 13 "Full-time manual shift" 14 "Intermediate Position" 15 "Unknown signal Detecting (Should not use on diagnosis)" ;
VAL_ 64 TCU_Typ 0 "Reserved" 1 "Step A" 2 "CVT" 3 "DCT" 4 "AMT" 5 "eClutch (2pedal)" 6 "eClutch (3pedal)" ;
VAL_ 64 TCU_TqRdctnVal 0 "Max. reduction" 2047 "No reduction" 2048 "reduction to 0 torque" ;
VAL_ 64 CF_TCU_AES_Flag 0 "Off" 1 "On" ;
VAL_ 64 TCU_GearStepTyp 3 "3 - Speed AT or DCT" 4 "4 - Speed AT or DCT" 5 "5 - Speed AT or DCT" 6 "6 - Speed AT or DCT" 7 "7- Speed AT or DCT" 8 "8 - Speed AT or DCT" ;
VAL_ 64 TCU_GearShftSta 0 "no gear change" 1 "gear change is active" 2 "Not used" 3 "Error Indicator" ;
VAL_ 64 TCU_TqCnvrtrSta 0 "No lock up control" 1 "Slip lock up" 2 "Fully lock up" 3 "Off slip lock up" ;
VAL_ 64 TCU_CurrGearSta 0 "if N or P are detected (no frictional connection)" 1 "1st speed" 2 "2nd speed" 3 "3rd speed" 4 "4th speed" 5 "5th speed" 6 "6th speed" 7 "7th speed" 8 "8th speed" 14 "Reverse speed" ;
VAL_ 64 TCU_TrgtGearSta 0 "if N or P are detected (no frictional connection)" 1 "1st speed" 2 "2nd speed" 3 "3rd speed" 4 "4th speed" 5 "5th speed" 6 "6th speed" 7 "7th speed" 8 "8th speed" 14 "Reverse speed" ;
VAL_ 64 TCU_CluTrgtGearSta 0 "if N or P are detected (no frictional connection)" 1 "1st speed" 2 "2nd speed" 3 "3rd speed" 4 "4th speed" 5 "5th speed" 6 "6th speed" 7 "7th speed" 8 "8th speed" 14 "Reverse speed" ;
VAL_ 64 TCH_EngTrgtGearSta 0 "if N or P are detected (no frictional connection)" 1 "1st speed" 2 "2nd speed" 3 "3rd speed" 4 "4th speed" 5 "5th speed" 6 "6th speed" 7 "7th speed" 8 "8th speed" 14 "Reverse speed" ;
VAL_ 64 TCU_EngTqLimVal 0 "Max. reduction" 2047 "No reduction" 2048 "reduction to 0 torque" ;
VAL_ 64 TCU_CluTrgtGearConfg 0 "TCU_TrgtGearSta" 1 "TCU_CluTrgtGearSta" 2 "Not Used" 3 "Error Indicator" ;
VAL_ 64 TCU_DesiBoost 0 "off" 1 "on" ;
VAL_ 64 TCU_VehSpdKphVal 255 "Error Indicator" ;
VAL_ 1308 VAPI_BltnCamInsideSwEnable_Set 0 "Default" 1 "Enable" 2 "Disable" 3 "Error indicator" ;
VAL_ 613 EMS_Crc8Val 0 "0x0~0xFFFF:CRCValue" 65535 "0x0~0xFFFF:CRCValue" ;
VAL_ 613 HEV_WarmUpReq_For_DATC 0 "Engine stop request" 1 "No engine stop request" ;
VAL_ 613 EMS_AlvCnt8Val 0 "0x0~0xFF:AlvCntValue" 255 "0x0~0xFF:AlvCntValue" ;
VAL_ 613 HEV_RbmInhbtSta 0 "applied options (See Description)" 1 "applied options (See Description)" 2 "applied options (See Description)" 3 "applied options (See Description)" ;
VAL_ 613 HEV_EhrsTempSta 0 "Normal" 1 "High" 3 "Fault" ;
VAL_ 613 HEV_Aaf_WrnLamp 0 "Lamp OFF" 1 "Lamp ON" ;
VAL_ 613 HEV_OPSFail 0 "Oil Pressure Warning Lamp OFF" 1 "Oil Pressure Warning Lamp ON" ;
VAL_ 613 HEV_EngDsplceTyp 255 "Error indicator" ;
VAL_ 613 HEV_EngTyp2 0 "LPI" 1 "MPI" 2 "GDI" 3 "TGDI" 4 "CVVL" 5 "CVVD" 6 "PDI" 7 "FFV" 8 "TCI" 9 "VGT" 10 "Turbo" 14 "Not used" 15 "Error indicator" ;
VAL_ 613 HEV_EngTyp1 0 "epsilon(ε)" 1 "gamma(γ)" 2 "kappa(κ)" 3 "theta(θ)" 4 "nu(ν)" 5 "lambda(λ)" 6 "tau(τ)" 10 "S" 11 "A" 12 "R" 13 "U" 14 "D" 15 "Error indicator" ;
VAL_ 613 HEV_S_F 0 "AMS" 1 "ISG" 2 "Reserved" 3 "Reserved" ;
VAL_ 613 HEV_S_F_GEN 0 "No AMS" 1 "1G Generation AMS" 2 "1.5G Generation AMS" 3 "2G Generation AMS" 4 "Reserved" 5 "Reserved" 6 "Reserved" 7 "Reserved" ;
VAL_ 613 HEV_RECTrigSta 0 "No detected" 1 "REC detected" ;
VAL_ 613 HEV_PendingTrigSta 0 "No detected" 1 "Pending detected" ;
VAL_ 613 HEV_OilLifeRatio 1 "Engine oil life ratio with % unit" 2 "Engine oil life ratio with % unit" 3 "Engine oil life ratio with % unit" 4 "Engine oil life ratio with % unit" 5 "Engine oil life ratio with % unit" 6 "Engine oil life ratio with % unit" 7 "Engine oil life ratio with % unit" 8 "Engine oil life ratio with % unit" 9 "Engine oil life ratio with % unit" 10 "Engine oil life ratio with % unit" 11 "Engine oil life ratio with % unit" 12 "Engine oil life ratio with % unit" 13 "Engine oil life ratio with % unit" 14 "Engine oil life ratio with % unit" 15 "Engine oil life ratio with % unit" 16 "Engine oil life ratio with % unit" 17 "Engine oil life ratio with % unit" 18 "Engine oil life ratio with % unit" 19 "Engine oil life ratio with % unit" 20 "Engine oil life ratio with % unit" 21 "Engine oil life ratio with % unit" 22 "Engine oil life ratio with % unit" 23 "Engine oil life ratio with % unit" 24 "Engine oil life ratio with % unit" 25 "Engine oil life ratio with % unit" 26 "Engine oil life ratio with % unit" 27 "Engine oil life ratio with % unit" 28 "Engine oil life ratio with % unit" 29 "Engine oil life ratio with % unit" 30 "Engine oil life ratio with % unit" 31 "Engine oil life ratio with % unit" 32 "Engine oil life ratio with % unit" 33 "Engine oil life ratio with % unit" 34 "Engine oil life ratio with % unit" 35 "Engine oil life ratio with % unit" 36 "Engine oil life ratio with % unit" 37 "Engine oil life ratio with % unit" 38 "Engine oil life ratio with % unit" 39 "Engine oil life ratio with % unit" 40 "Engine oil life ratio with % unit" 41 "Engine oil life ratio with % unit" 42 "Engine oil life ratio with % unit" 43 "Engine oil life ratio with % unit" 44 "Engine oil life ratio with % unit" 45 "Engine oil life ratio with % unit" 46 "Engine oil life ratio with % unit" 47 "Engine oil life ratio with % unit" 48 "Engine oil life ratio with % unit" 49 "Engine oil life ratio with % unit" 50 "Engine oil life ratio with % unit" 51 "Engine oil life ratio with % unit" 52 "Engine oil life ratio with % unit" 53 "Engine oil life ratio with % unit" 54 "Engine oil life ratio with % unit" 55 "Engine oil life ratio with % unit" 56 "Engine oil life ratio with % unit" 57 "Engine oil life ratio with % unit" 58 "Engine oil life ratio with % unit" 59 "Engine oil life ratio with % unit" 60 "Engine oil life ratio with % unit" 61 "Engine oil life ratio with % unit" 62 "Engine oil life ratio with % unit" 63 "Engine oil life ratio with % unit" 64 "Engine oil life ratio with % unit" 65 "Engine oil life ratio with % unit" 66 "Engine oil life ratio with % unit" 67 "Engine oil life ratio with % unit" 68 "Engine oil life ratio with % unit" 69 "Engine oil life ratio with % unit" 70 "Engine oil life ratio with % unit" 71 "Engine oil life ratio with % unit" 72 "Engine oil life ratio with % unit" 73 "Engine oil life ratio with % unit" 74 "Engine oil life ratio with % unit" 75 "Engine oil life ratio with % unit" 76 "Engine oil life ratio with % unit" 77 "Engine oil life ratio with % unit" 78 "Engine oil life ratio with % unit" 79 "Engine oil life ratio with % unit" 80 "Engine oil life ratio with % unit" 81 "Engine oil life ratio with % unit" 82 "Engine oil life ratio with % unit" 83 "Engine oil life ratio with % unit" 84 "Engine oil life ratio with % unit" 85 "Engine oil life ratio with % unit" 86 "Engine oil life ratio with % unit" 87 "Engine oil life ratio with % unit" 88 "Engine oil life ratio with % unit" 89 "Engine oil life ratio with % unit" 90 "Engine oil life ratio with % unit" 91 "Engine oil life ratio with % unit" 92 "Engine oil life ratio with % unit" 93 "Engine oil life ratio with % unit" 94 "Engine oil life ratio with % unit" 95 "Engine oil life ratio with % unit" 96 "Engine oil life ratio with % unit" 97 "Engine oil life ratio with % unit" 98 "Engine oil life ratio with % unit" 99 "Engine oil life ratio with % unit" 100 "Engine oil life ratio with % unit" 101 "Not used" 102 "Not used" 103 "Not used" 104 "Not used" 105 "Not used" 106 "Not used" 107 "Not used" 108 "Not used" 109 "Not used" 110 "Not used" 111 "Not used" 112 "Not used" 113 "Not used" 114 "Not used" 115 "Not used" 116 "Not used" 117 "Not used" 118 "Not used" 119 "Not used" 120 "Not used" 121 "Not used" 122 "Not used" 123 "Not used" 124 "Not used" 125 "Not used" 126 "Not used" 127 "Error" ;
VAL_ 613 HEV_OilLifeEna 0 "Oil life monitoring Not applied" 1 "Oil life monitoring Applied" 2 "Reserved" 3 "Error" ;
VAL_ 613 HEV_OilLifeWarn 0 "No display" 1 "'Change engine oil' warning, 1st step (Low urgency)" 2 "'Change engine oil' warning, 2nd step (High urgency)" 3 "Oil change question based on oil temperature" 4 "Oil change confirm based on oil temperature" 5 "Reserved" 6 "Reserved" 7 "Error" ;
VAL_ 613 HEV_VbOffActSta 0 "VB Off not Act" 1 "VB Off Act" 2 "Not used" 3 "Error indicator" ;
VAL_ 613 HEV_AirCompOffReq 0 "none" 1 "off request" 2 "Not used" 3 "Error indicator" ;
VAL_ 613 HEV_MilConfgVal 0 "No MIL" 1 "MIL/FMY treatment OBD1" 2 "MIL/FMY treatment OBD2" 3 "MIL/FMY treatment OBD2 (US)" 4 "MIL/FMY treatment EOBD" 5 "MIL/FMY treatment KOBD" ;
VAL_ 613 HEV_CF_EMS_LOCKUP 0 "Request Off" 1 "Request On" ;
VAL_ 613 HEV_OilLvlSta 0 "OIL LEVEL LAMP Off" 1 "OIL LEVEL LAMP On" 2 "Not used" 3 "Error indicator" ;
VAL_ 613 HEV_ImmoLmpReq 0 "Off" 1 "Blink" 2 "On" 3 "Error indicator" ;
VAL_ 613 HEV_MilReq 0 "Off" 1 "On" 2 "Not used" 3 "Error indicator" ;
VAL_ 613 HEV_WiperSwSta 0 "Off" 1 "On" 2 "Not used" 3 "Error indicator" ;
VAL_ 613 HEV_FanOpSta 0 "Off" 1 "On" 2 "Not used" 3 "Error indicator" ;
VAL_ 613 HEV_FanSta 0 "Off" 1 "Low" 2 "Middle" 3 "High" ;
VAL_ 613 HEV_BrkLtSwSta 0 "Not Support" 1 "Off" 2 "On" 3 "failure" ;
VAL_ 613 HEV_SoakTimeErrSta 0 "No failure detected" 1 "Failure detected" 2 "Not used" 3 "Error indicator" ;
VAL_ 613 HEV_SoakTimeOvrSta 0 "Engine soaking time < 360 min" 1 "Engine soaking time ≥ 360 min" 2 "Not used" 3 "Error indicator" ;
VAL_ 613 HEV_FuelRunOutSta 0 "None" 1 "Fuel RunOut" 2 "Not used" 3 "Error indicator" ;
VAL_ 613 HEV_FuelRunOutDetSta 0 "Inactive" 1 "Active" 2 "Not used" 3 "Error indicator" ;
VAL_ 1024 BVM_ViewMode 0 "Default" 1 "N Mode BVM" 2 "RESERVED" 3 "RESERVED" 4 "RESERVED" 5 "RESERVED" 6 "RESERVED" 7 "RESERVED" 8 "RESERVED" 9 "RESERVED" 10 "RESERVED" 11 "RESERVED" 12 "RESERVED" 13 "RESERVED" 14 "RESERVED" 15 "Invalid" ;
VAL_ 1024 SVM_CamConfgSta 5 "All cameras reset requested" 6 "All serdes reset requested" 7 "I2C back channel off" 0 "No Request (Default)" 1 "Start of configured" 2 "End of configured" 3 "Normal operation" 4 "All cameras/SerDes reset requested" 8 "RESERVED" 9 "RESERVED" 10 "RESERVED" 11 "RESERVED" 12 "RESERVED" 13 "RESERVED" 14 "RESERVED" 15 "Invalid" ;
VAL_ 1024 SVM_OperatSta 0 "Default (Not defined)" 1 "ADAS_PRK 3 Stand-by" 2 "RESERVED" 3 "RESERVED" 4 "ADAS_PRK 3 Normal operation" 5 "ADAS_PRK 3 End of operation" 6 "RESERVED" 7 "RESERVED" 8 "RESERVED" 9 "RESERVED" 10 "RESERVED" 11 "RESERVED" 12 "RESERVED" 13 "RESERVED" 14 "RESERVED" 15 "Invalid" ;
VAL_ 1024 BVM_View2Sta 0 "Off" 1 "Left (Drive, before 4 sec)" 2 "Left (Drive, after 4 sec)" 3 "Left (Stop)" 4 "Right (Drive, before 4 sec)" 5 "Right (Drive, after 4 sec)" 6 "Right (Stop)" 7 "Reserved" ;
VAL_ 1024 ADAS_PRK_ResetOpsta 0 "Normal" 1 "Reset Complete" 2 "Reset Fail" 3 "RESERVED" ;
VAL_ 1024 SVM_ExteriorColorRedNValueSta 0 "0x000~0x0FF:Red Color ( 0~255)" 255 "0x000~0x0FF:Red Color ( 0~255)" 256 "Default" 257 "101~0x1FE:Reserved" 510 "101~0x1FE:Reserved" 511 "Invalid" ;
VAL_ 1024 SVM_ExteriorColorGreenNValueSta 0 "0x000~0x0FF:Green Color (0~255)" 255 "0x000~0x0FF:Green Color (0~255)" 256 "Default" 257 "101~0x1FE:Reserved" 510 "101~0x1FE:Reserved" 511 "Invalid" ;
VAL_ 1024 SVM_ExteriorColorBlueNValueSta 0 "0x000~0x0FF:Blue Color (0~255)" 255 "0x000~0x0FF:Blue Color (0~255)" 256 "Default" 257 "101~0x1FE:Reserved" 510 "101~0x1FE:Reserved" 511 "Invalid" ;
VAL_ 1026 BDC_FD_SMK_Crc3Val 0 "0x0~0xFFFF:CRCValue" 65535 "0x0~0xFFFF:CRCValue" ;
VAL_ 1026 SMK_TrmnlCtrlStaBDCEV 0 "Off" 1 "Off_AuthWaiting" 2 "Off_CrankingAuthWaiting" 3 "Off_ESCLUnlockWaiting" 4 "PowerOn" 5 "PowerOn_ESCLUnlockWaiting" 6 "PowerOn_AuthWaiting" 7 "PowerOn_CrankingWait" 8 "Cranking" 9 "Ready" 10 "RESERVED" 11 "RESERVED" 12 "RESERVED" 13 "RESERVED" 14 "RESERVED" 15 "RESERVED" 16 "RESERVED" 17 "RESERVED" 18 "RESERVED" 19 "RESERVED" 20 "RESERVED" 21 "RESERVED" 22 "RESERVED" 23 "RESERVED" 24 "RESERVED" 25 "RESERVED" 26 "RESERVED" 27 "RESERVED" 28 "RESERVED" 29 "RESERVED" 30 "RESERVED" 31 "Error Indicator" ;
VAL_ 1026 SMK_PwrOnModeSta 0 "Off Mode" 1 "Power On Normal Mode" 2 "Utility Mode" 3 "Maintenance Service Mode" ;
VAL_ 1026 SMK_StndbyMdTmrMin 0 "Default (Timer Stop)" 1 "0min ~ 60min" 2 "0min ~ 60min" 3 "0min ~ 60min" 4 "0min ~ 60min" 5 "0min ~ 60min" 6 "0min ~ 60min" 7 "0min ~ 60min" 8 "0min ~ 60min" 9 "0min ~ 60min" 10 "0min ~ 60min" 11 "0min ~ 60min" 12 "0min ~ 60min" 13 "0min ~ 60min" 14 "0min ~ 60min" 15 "0min ~ 60min" 16 "0min ~ 60min" 17 "0min ~ 60min" 18 "0min ~ 60min" 19 "0min ~ 60min" 20 "0min ~ 60min" 21 "0min ~ 60min" 22 "0min ~ 60min" 23 "0min ~ 60min" 24 "0min ~ 60min" 25 "0min ~ 60min" 26 "0min ~ 60min" 27 "0min ~ 60min" 28 "0min ~ 60min" 29 "0min ~ 60min" 30 "0min ~ 60min" 31 "0min ~ 60min" 32 "0min ~ 60min" 33 "0min ~ 60min" 34 "0min ~ 60min" 35 "0min ~ 60min" 36 "0min ~ 60min" 37 "0min ~ 60min" 38 "0min ~ 60min" 39 "0min ~ 60min" 40 "0min ~ 60min" 41 "0min ~ 60min" 42 "0min ~ 60min" 43 "0min ~ 60min" 44 "0min ~ 60min" 45 "0min ~ 60min" 46 "0min ~ 60min" 47 "0min ~ 60min" 48 "0min ~ 60min" 49 "0min ~ 60min" 50 "0min ~ 60min" 51 "0min ~ 60min" 52 "0min ~ 60min" 53 "0min ~ 60min" 54 "0min ~ 60min" 55 "0min ~ 60min" 56 "0min ~ 60min" 57 "0min ~ 60min" 58 "0min ~ 60min" 59 "0min ~ 60min" 60 "0min ~ 60min" 61 "0min ~ 60min" 62 "RESERVED" 63 "Error Indicator" ;
VAL_ 1026 SMK_PwrTransitionReq 0 "Off" 1 "Request On" 2 "Not Used" 3 "Error Indicator" ;
VAL_ 1026 SMK_StndbyMdTmrSec 0 "Default (Timer Stop)" 1 "0sec ~ 59sec" 2 "0sec ~ 59sec" 3 "0sec ~ 59sec" 4 "0sec ~ 59sec" 5 "0sec ~ 59sec" 6 "0sec ~ 59sec" 7 "0sec ~ 59sec" 8 "0sec ~ 59sec" 9 "0sec ~ 59sec" 10 "0sec ~ 59sec" 11 "0sec ~ 59sec" 12 "0sec ~ 59sec" 13 "0sec ~ 59sec" 14 "0sec ~ 59sec" 15 "0sec ~ 59sec" 16 "0sec ~ 59sec" 17 "0sec ~ 59sec" 18 "0sec ~ 59sec" 19 "0sec ~ 59sec" 20 "0sec ~ 59sec" 21 "0sec ~ 59sec" 22 "0sec ~ 59sec" 23 "0sec ~ 59sec" 24 "0sec ~ 59sec" 25 "0sec ~ 59sec" 26 "0sec ~ 59sec" 27 "0sec ~ 59sec" 28 "0sec ~ 59sec" 29 "0sec ~ 59sec" 30 "0sec ~ 59sec" 31 "0sec ~ 59sec" 32 "0sec ~ 59sec" 33 "0sec ~ 59sec" 34 "0sec ~ 59sec" 35 "0sec ~ 59sec" 36 "0sec ~ 59sec" 37 "0sec ~ 59sec" 38 "0sec ~ 59sec" 39 "0sec ~ 59sec" 40 "0sec ~ 59sec" 41 "0sec ~ 59sec" 42 "0sec ~ 59sec" 43 "0sec ~ 59sec" 44 "0sec ~ 59sec" 45 "0sec ~ 59sec" 46 "0sec ~ 59sec" 47 "0sec ~ 59sec" 48 "0sec ~ 59sec" 49 "0sec ~ 59sec" 50 "0sec ~ 59sec" 51 "0sec ~ 59sec" 52 "0sec ~ 59sec" 53 "0sec ~ 59sec" 54 "0sec ~ 59sec" 55 "0sec ~ 59sec" 56 "0sec ~ 59sec" 57 "0sec ~ 59sec" 58 "0sec ~ 59sec" 59 "0sec ~ 59sec" 60 "0sec ~ 59sec" 61 "RESERVED" 62 "RESERVED" 63 "Error Indicator" ;
VAL_ 1026 SMK_VhclSlpSta 0 "Vehicle inclined(R/START not possible)" 1 "Vehicle flat or inclined within limit(R/START possible)" 2 "Not Used" 3 "Error Indicator" ;
VAL_ 1026 USM_SmrtSldngModSta 0 "Default Value" 1 "Smart Sliding Door Off" 2 "Smart Sliding Door On" 3 "Reserved" 4 "Invalid" 5 "Reserved" 6 "Not Used" 7 "Error Indicator" ;
VAL_ 1026 SMK_EVPwrOffReq 0 "Off" 1 "On" 2 "RESERVED" 3 "Error Indicator" ;
VAL_ 1026 SMK_MaintenanceSrvMdReq 0 "Request off" 1 "Request on" 2 "RESERVED" 3 "Error Indicator" ;
VAL_ 1026 Warn_DisWrngSta3 0 "Off" 1 "Tele/Monitor Position Not Confirmed(P-OIP)" 16 "AuthFail2(FP, RDY, w/o SSB)" 17 "AuthFail2(DKFP, IGN, w/o SSB)" 18 "AuthFail2(DKFP, RDY, w/o SSB)" 31 "Error Indicator" 2 "Swivel Seat Position Not Confirmed(P-OIP)" 3 "Power Transition Req(P-OIP)" 4 "Tele/Monitor Position Not Confirmed(CTS)" 5 "Swivel Seat Position Not Confirmed(CTS)" 6 "Power Transition Req(CTS)" 7 "Tele/Monitor Position Not Confirmed(ALL)" 8 "Swivel Seat Position Not Confirmed(ALL)" 9 "Power Transition Req(ALL)" 10 "ESCL NotUnlockedWarn(w/o SSB)" 11 "AuthFail2(SMK, IGN, w/o SSB)" 12 "AuthFail2(SMK, RDY, w/o SSB)" 13 "AuthFail2(DK, IGN, w/o SSB)" 14 "AuthFail2(DK, RDY, w/o SSB)" 15 "AuthFail2(FP, IGN, w/o SSB)" ;
VAL_ 1026 SMK_CCUOTACrankInhState 0 "Off" 1 "Cranking Inhibit" 2 "IGN, Cranking Inhibit" 3 "Error Indicator (Default)" ;
VAL_ 1026 SMK_NParkModePwrOFFResult 0 "Default" 1 "N Position Power OFF Complete" 2 "N Position Power OFF Failure" 3 "Error Indicator" ;
VAL_ 1026 SMK_TwoPressStrtSta 0 "Off" 1 "Wait(1Press)" 2 "RESERVED" 3 "Error Indicator" ;
VAL_ 1026 SMK_PwrOffDspBtnActvSta 0 "Default" 1 "Activate" 2 "Deactivate" 3 "Error Indicator" ;
VAL_ 1026 SMK_GetOffPopUpReq 0 "Off" 1 "Request On" 2 "Not Used" 3 "Error Indicator" ;
VAL_ 1026 SMK_PwrOffHardBtnPopupReq 0 "Off" 1 "Press On Driving" 2 "Press On Parking" 3 "Long or 3 Press On Driving" 4 "Not Used" 5 "Not Used" 6 "Not Used" 7 "Error Indicator" ;
VAL_ 1026 SMK_EVRdyOffReq 0 "Off" 1 "On" 2 "RESERVED" 3 "Error Indicator" ;
VAL_ 1026 SMK_NTowMdAuthFailSta 0 "Default" 1 "Authentication Fail" 2 "Not Used" 3 "Error Indicator" ;
VAL_ 1026 SMK_SftyMdExitOKSta 0 "Default" 1 "On" 2 "Not Used" 3 "Error Indicator" ;
VAL_ 1026 SMK_SftyMdPopup 0 "Default" 1 "Check Safety Mode Exit" 2 "Pushed Brake during Safety Mode" 3 "Startable" 4 "RESERVED" 5 "RESERVED" 6 "RESERVED" 7 "Error Indicator" ;
VAL_ 1026 BDC_FD_SMK_AlvCnt3Val 0 "0x0~0xFF:AlvCntValue" 255 "0x0~0xFF:AlvCntValue" ;
VAL_ 1026 SMK_HUOTACrankInhState 0 "Off" 1 "Cranking  inhibit" 2 "IGN, Cranking  inhibit" 3 "Error Indicator (default)" ;
VAL_ 1026 SMK_EasyPwrOffOpt 0 "NotApplied" 1 "Applied" 2 "Not Used" 3 "Error Indicator" ;
VAL_ 1026 SMK_EasyPwrOffInProgress 0 "Default" 1 "In Progress" 2 "Not Used" 3 "Error Indicator" ;
VAL_ 1026 ESCL_EsclMngrSta 0 "NOT_POWER_SUPPLIED" 1 "POWER_SUPPLIED_FOR_UNLOCK" 2 "POWER_SUPPLIED_FOR_LOCK" 3 "PWR_SUPPL_FOR_LEARNIGN_NEUTRAL" 4 "UNLOCK_IN_PROGRESS" 5 "LOCK_IN_PROGRESS" 6 "POWER_OFF_CONFIRMATION" 7 "ANTI_SCANNING" 8 "Reserved" 9 "Reserved" 10 "Reserved" 11 "Reserved" 12 "Reserved" 13 "Reserved" 14 "Not Used" 15 "Error Indicator" ;
VAL_ 1026 ESCL_EsclPwrSupSta 0 "Off" 1 "On" 2 "Not Used" 3 "Error Indicator" ;
VAL_ 1026 Fob_FoundExtrnlIntArea 0 "Default" 1 "Can't recognize" 2 "Fob recognized" 3 "Error Indicator" ;
VAL_ 1026 ESCL_EsclEnaSta 0 "Off" 1 "On" 2 "Not Used" 3 "Error Indicator" ;
VAL_ 1026 ESCL_EsclUnitSta 0 "Retry (Fault)" 1 "In progress (Busy)" 2 "Reserved" 3 "OK" 4 "Unknown" 5 "Reseved" 6 "Not Used" 7 "Error Indicator" ;
VAL_ 1026 ESCL_EsclBoltSta 0 "Intermediate" 1 "Locked" 2 "Unlocked" 3 "Failure" 4 "Unknown" 5 "Reseved" 6 "Not Used" 7 "Error Indicator" ;
VAL_ 1026 ESCL_EsclLoBattSta 0 "ESCL Low Battery Bit = 0" 1 "ESCL Low Battery Bit = 1" 2 "Unknown" 3 "Reserved" 4 "Reserved" 5 "Reseved" 6 "Not Used" 7 "Error Indicator" ;
VAL_ 1026 ESCL_EsclUnLkSwSta 0 "EsclNotPowerSupplied" 1 "EsclPowerSupplied&Unlocked" 2 "EsclPowerSupplied&NotUnlocked" 3 "Reserved" 4 "Reserved" 5 "Reseved" 6 "Not Used" 7 "Error Indicator" ;
VAL_ 1026 Fob_FoundRrLftArea 0 "Default" 1 "Fob Found(RrLft)" 2 "Not Used" 3 "Error Indicator" ;
VAL_ 1026 Fob_FoundRrRtArea 0 "Default" 1 "Fob Found(RrRt)" 2 "Not Used" 3 "Error Indicator" ;
VAL_ 1026 Warn_StrtStpBtnWrngSta 0 "Off" 1 "On" 2 "Not Used" 3 "Error Indicator" ;
VAL_ 1026 Warn_DeActvWrngSta 0 "Off" 1 "On" 2 "Not Used" 3 "Error Indicator" ;
VAL_ 1026 Warn_GearPosPWrngReq 0 "Warning Off" 1 "Warning On" 2 "Not Used" 3 "Error Indicator" ;
VAL_ 1026 Warn_ExtrnlBuzWrngSta 0 "Off" 1 "SMK Door Lock1" 2 "SMK Door Lock2" 3 "ID Out" 4 "Trunk Warning" 5 "SMK Key Reminder2" 6 "SMK Door Lock3" 7 "Invalid" 8 "RSPA State Inform" 9 "Hand Free Trunk" 10 "Hand Free Trunk2" 11 "BLE Access Check" 12 "FP Authfail" 13 "ID Out For RSPA" 14 "Frunk Warning" 15 "Error Indicator" ;
VAL_ 1026 Warn_IdOutWrngSta 0 "Off" 1 "On(2kHz)" 2 "On(1.9kHz)" 3 "Error Indicator" ;
VAL_ 1026 Warn_KeyBattLoWrngSta 0 "Off" 1 "On" 2 "Not Used" 3 "Error Indicator" ;
VAL_ 1026 Warn_KeyOutLmpOnReq 0 "Off" 1 "On" 2 "Not Used" 3 "Error Indicator" ;
VAL_ 1026 Warn_NotGearPosPWrngSta 0 "Off" 1 "On" 2 "Not Used" 3 "Error Indicator" ;
VAL_ 1026 Warn_EsclFlWrngSta 0 "Off" 1 "On" 2 "Not Used" 3 "Error Indicator" ;
VAL_ 1026 Warn_EsclNotLkWrngSta 0 "Off" 1 "On" 2 "Not Used" 3 "Error Indicator" ;
VAL_ 1026 Warn_EsclNotUnLkWrngSta 0 "Off" 1 "On" 2 "Not Used" 3 "Error Indicator" ;
VAL_ 1026 Warn_ImmoLmpOnReq 0 "Off" 1 "On" 2 "Not Used" 3 "Error Indicator" ;
VAL_ 1026 Warn_DisWrngSta2 0 "Off" 1 "RESERVED" 2 "RESERVED" 3 "RESERVED" 4 "Vehicle_is_on(China BLE)" 5 "Engine_Start_Operation_IND (Brake)" 6 "Engine_Start_Operation_IND (Clutch)" 7 "Engine_Start_Operation_IND (Brake & Clutch)" 8 "P_N Off Warning (BDC)" 9 "P Off Warning (BDC)" 10 "Auth_Fail_Warning For IAU" 11 "ReAuth_Warning(FOB)" 12 "Maintenance Service Mode Fail" 13 "Not Used" 14 "Not Used" 15 "Error Indicator" ;
VAL_ 1026 Warn_DisWrngSta 0 "Off" 1 "Shift_P_Warning" 16 "Vehicle_is_On(DigitalKey)" 17 "Power Auto Off Ready" 18 "Auth_Fail_Waring2 (non-SSB immo coil)" 19 "ReAuth_Warning (Digital Key)" 20 "ReAuth_Warning (FingerPrint)" 21 "ReAuth_Warning (Digital Key&FingerPrint)" 22 "ReAuth_Warning (FOB&Digital Key)" 23 "ReAuth_Warning (FOB&Finger Print)" 24 "Reauth_Warning 2 (FOB&Digital Key&Finger Print)" 25 "Key_Out_Warning (FOB&Digital Key)" 26 "Auth_Fail_Warning 2 (Seperated Immo Coil type)" 27 "Reauth_Warning 2 (RSPA)" 28 "Not Used" 29 "Not Used" 30 "Not Used" 31 "Error Indicator" 2 "Key_Bat_Discharge_Warning" 3 "Not_Unlocked_Warning" 4 "AC_Plug_Connected_Warning" 5 "Escl_Ecu_Fail_Warning" 6 "Engine_Start_Operation_IND" 7 "Auth_Fail_Warning" 8 "Key_Removal_IND" 9 "Key_Out_Warning" 10 "SSB_Warning" 11 "Auth_Fail_Warning2" 12 "Vehicle_Not_P_Warning" 13 "Stop Lamp Fuse Fail Warning" 14 "Not P_N Warning" 15 "Vehicle_is_On(FingerPrint)" ;
VAL_ 1026 SMK_OTACrankInhState 0 "Off(Default)" 1 "Cranking inhibit" 2 "IGN,Cranking inhibit" 3 "RESERVED" 4 "RESERVED" 5 "RESERVED" 6 "RESERVED" 7 "Error Indicator" ;
VAL_ 1026 SMK_TgltAwaySrchResult 0 "Default" 1 "Not Exist" 2 "Exist" 3 "Invalid" ;
VAL_ 1026 SMKFOBID_CHNAVNT 0 "None" 1 "ID1" 2 "ID2" 3 "ID3" 4 "ID4" 5 "Reserved" 6 "Reserved" 7 "Error Indicator" ;
VAL_ 1026 SMK_TrmnlCtrlGrpStaBDC 0 "Off" 1 "Acc" 2 "Ign" 3 "Cranking" 4 "Engine Running" 5 "RESERVED" 6 "RESERVED" 7 "Error Indicator" ;
VAL_ 1026 SMK_TrmnlCtrlGrpStaBDCEV 0 "Off" 1 "PowerOn" 2 "Cranking" 3 "Ready" 4 "RESERVED" 5 "RESERVED" 6 "RESERVED" 7 "Error Indicator" ;
VAL_ 1026 SMK_TrmnlCtrlStaBDC 0 "OFF" 1 "OFF_AUTHWAITING" 2 "OFF_CRANKINGAUTHWAITING" 3 "OFF_ESCLUNLOCKWAITING" 4 "ACC" 5 "ACC_AUTHWAITING" 6 "ACC_ESCLUNLOCKWAITING" 7 "IGN" 8 "IGN_AUTHWAITING" 9 "IGN_CRANKINGWAIT" 10 "CRANKING" 11 "ENGINERUNNING" 12 "RESERVED" 13 "RESERVED" 14 "RESERVED" 15 "RESERVED" 16 "RESERVED" 17 "RESERVED" 18 "RESERVED" 19 "RESERVED" 20 "RESERVED" 21 "RESERVED" 22 "RESERVED" 23 "RESERVED" 24 "RESERVED" 25 "RESERVED" 26 "RESERVED" 27 "RESERVED" 28 "RESERVED" 29 "RESERVED" 30 "RESERVED" 31 "Error Indicator" ;
VAL_ 193 BLTN_CAM_FD_Crc1Val 0 "0x0~0xFFFF:CRCValue" 65535 "0x0~0xFFFF:CRCValue" ;
VAL_ 193 BLTN_CAM_FD_AlvCnt1Val 0 "0x0~0xFF:AlvCntValue" 255 "0x0~0xFF:AlvCntValue" ;
VAL_ 193 BLTN_CAM_UI_Mode_Tmt_Req 0 "Default" 1 "BLTN_CAM UI Terminate Request" 2 "Reserved" 3 "invalid" ;
VAL_ 193 BLTN_CAM_PopUp_Req 14 "RESERVED" 0 "Default" 1 "Event Video Record On by manual switch" 2 "Time Lapse Record Started" 3 "Time Lapse Record Ended" 4 "micro SD card inserted" 5 "micro SD card removed" 6 "SD Card has problem(format required or need to be replaced)" 7 "Start Parking recording" 8 "Can not Start Parking recording (SD card is removed, not recognizable, or has problem)" 9 "Can not Record Event Video (SD card is removed, not recognizable, or has problem)" 10 "SD Card Unmounted" 11 "Time Lapse Record Ended without recorded file(Record frames are not enough to save.)" 12 "CAM Lens Pollution Warning" 13 "Can not Record Manual Button Event Video(ValetMode)" 15 "Invalid" ;
VAL_ 193 BLTN_CAM_File_List_Renew 0 "Defalut" 1 "the file list and storage space are renewed." 2 "reserved" 3 "Invalid" ;
VAL_ 193 BLTN_CAM_Wifi_Pwd_Chg_State 0 "Default" 1 "the password is changed" 2 "Failed, wrong password, can't change password" 3 "Invalid" ;
VAL_ 193 BLTN_CAM_Dis_Touch_BeepSound 0 "Off" 1 "ON" 2 "Keyboard On" 3 "invalid" ;
VAL_ 345 LBM_FD_Crc2Val 0 "0x0~0xFFFF:CRCValue" 65535 "0x0~0xFFFF:CRCValue" ;
VAL_ 345 MainLBM_NormalPwrVal 0 "0x0000~0xFFFE:0~65,534" 65534 "0x0000~0xFFFE:0~65,534" 65535 "Error Indicator" ;
VAL_ 345 MainLBM_NormalWhVal 0 "0x0000~0xFFFE:0~65,534" 65534 "0x0000~0xFFFE:0~65,534" 65535 "Error Indicator" ;
VAL_ 345 MainLBM_NormalReserveTimeVal 0 "0x00000~0xFFFFE:0~1,048,574" 1048574 "0x00000~0xFFFFE:0~1,048,574" 1048575 "Error Indicator" ;
VAL_ 345 LBM_FD_AlvCnt2Val 0 "0x0~0xFF:AlvCntValue" 255 "0x0~0xFF:AlvCntValue" ;
VAL_ 345 MainLBM_SleepReserveTimeVal 0 "0x00000~0xFFFFE:0~1,048,574" 1048574 "0x00000~0xFFFFE:0~1,048,574" 1048575 "Error Indicator" ;
VAL_ 345 MainLBM_CurrVal 65535 "Error Indicator" 0 "0~0xFFFE:Vaild Value" 65534 "0~0xFFFE:Vaild Value" ;
VAL_ 345 MainLBM_SocVal 0 "0x00~0x64:0% ~ 100 %" 100 "0x00~0x64:0% ~ 100 %" 101 "65~0xFE:Invalid" 254 "65~0xFE:Invalid" 255 "Error" ;
VAL_ 345 MainLBM_VtgVal 0 "0x0000~0x2EE0:6.000V ~ 18.000V" 12000 "0x0000~0x2EE0:6.000V ~ 18.000V" 12001 "2EE1~0x3FFE:Invalid" 16382 "2EE1~0x3FFE:Invalid" 16383 "Error" ;
VAL_ 345 MainLBM_TempVal 0 "0x000~0x14A:0~330" 330 "0x000~0x14A:0~330" 331 "14B~0x1FE:RESERVED" 510 "14B~0x1FE:RESERVED" 511 "Error" ;
VAL_ 345 MainLBM_SocErrSta 0 "Nomal State" 1 "Implausible State" 2 "Not used" 3 "Error indicator" ;
VAL_ 345 MainLBM_SohVal 0 "0x00~0x64:0~100" 100 "0x00~0x64:0~100" 101 "65~0xFE:RESERVED" 254 "65~0xFE:RESERVED" 255 "Error" ;
VAL_ 345 MainLBM_SnsrInvldSta 0 "Valid Condition" 1 "Invalid Condition" 2 "Not used" 3 "Error indicator" ;
VAL_ 345 MainLBM_RspErrSta 0 "Operating correctly" 1 "Response error" 2 "Not used" 3 "Error indicator" ;
VAL_ 345 MainLBM_CapacityVal 0 "0x0~0xFE:Capacity Value" 254 "0x0~0xFE:Capacity Value" 255 "Error Indicator" ;
VAL_ 345 MainLBM_SohErrSta 0 "SOH valid" 1 "SOH invalid" 2 "NotUsed" 3 "Error Indicate" ;
VAL_ 345 MainLBM_PeakLoadPwrVal 0 "0x0000~0xFFFE:0~65,534" 65534 "0x0000~0xFFFE:0~65,534" 65535 "Error Indicator" ;
VAL_ 74 IMU_Crc1Val 0 "0x0~0xFFFF:CRCValue" 65535 "0x0~0xFFFF:CRCValue" ;
VAL_ 74 IMU_AlvCnt1Val 0 "0x0~0xFF:AlvCntValue" 255 "0x0~0xFF:AlvCntValue" ;
VAL_ 194 BMS_FD_Crc1Val 0 "0x0~0xFFFF:CRCValue" 65535 "0x0~0xFFFF:CRCValue" ;
VAL_ 194 BMS_FD_AlvCnt1Val 0 "0x0~0xFF:AlvCntValue" 255 "0x0~0xFF:AlvCntValue" ;
VAL_ 194 xEV_BatEvtAlarm_HS 0 "Default" 1 "Level 1" 2 "Level 2" 3 "Level 3" 4 "Level 4" ;
VAL_ 194 xEV_BMS_WakeUpReqfor12V 0 "Default" 1 "Discharge Request" 2 "Reserved(Not Used)" 3 "Error Indicator" ;
VAL_ 194 xEV_AuxBattChrgReq_HS 0 "Charge Finish Request" 1 "LV2 Charge Request" 2 "LV1 Charge Request" 3 "Error Indicator" ;
VAL_ 194 xEV_12VBatAlarmReq_HS 0 "Normal" 1 "3rd Cut Off" 2 "Warn. MSG & 3rd Cut Off Req" 3 "Reserved(Not Used)" ;
VAL_ 194 BMS_ResetWakeup 0 "No Wakeup" 1 "Reset Wakeup" 2 "RESERVED" 3 "Invalid" ;
VAL_ 194 xEV_IG3OnReq 0 "Default" 1 "Request for Heating" 2 "Request for Cooling" 3 "RESERVED" 15 "Error Indicator" ;
VAL_ 1048 GNSS_Crc6Val 0 "0x0~0xFFFF:CRCValue" 65535 "0x0~0xFFFF:CRCValue" ;
VAL_ 1048 GNSS_AlvCnt6Val 0 "0x0~0xFF:AlvCntValue" 255 "0x0~0xFF:AlvCntValue" ;
VAL_ 1048 GNSS_MM_type 0 "WGS84" 1 "Bessel" 2 "Coordshift(for china)" 15 "invalid" ;
VAL_ 1051 HU_CLOCK_Crc1Val 0 "0x0~0xFFFF:CRCValue" 65535 "0x0~0xFFFF:CRCValue" ;
VAL_ 1051 HU_DisplayYear1 0 "19" 1 "20" 2 "21" 3 "invalid" ;
VAL_ 1051 HU_DisplayYear2 0 "00 year" 1 "01~99 year" 2 "01~99 year" 3 "01~99 year" 4 "01~99 year" 5 "01~99 year" 6 "01~99 year" 7 "01~99 year" 8 "01~99 year" 9 "01~99 year" 10 "01~99 year" 11 "01~99 year" 12 "01~99 year" 13 "01~99 year" 14 "01~99 year" 15 "01~99 year" 16 "01~99 year" 17 "01~99 year" 18 "01~99 year" 19 "01~99 year" 20 "01~99 year" 21 "01~99 year" 22 "01~99 year" 23 "01~99 year" 24 "01~99 year" 25 "01~99 year" 26 "01~99 year" 27 "01~99 year" 28 "01~99 year" 29 "01~99 year" 30 "01~99 year" 31 "01~99 year" 32 "01~99 year" 33 "01~99 year" 34 "01~99 year" 35 "01~99 year" 36 "01~99 year" 37 "01~99 year" 38 "01~99 year" 39 "01~99 year" 40 "01~99 year" 41 "01~99 year" 42 "01~99 year" 43 "01~99 year" 44 "01~99 year" 45 "01~99 year" 46 "01~99 year" 47 "01~99 year" 48 "01~99 year" 49 "01~99 year" 50 "01~99 year" 51 "01~99 year" 52 "01~99 year" 53 "01~99 year" 54 "01~99 year" 55 "01~99 year" 56 "01~99 year" 57 "01~99 year" 58 "01~99 year" 59 "01~99 year" 60 "01~99 year" 61 "01~99 year" 62 "01~99 year" 63 "01~99 year" 64 "01~99 year" 65 "01~99 year" 66 "01~99 year" 67 "01~99 year" 68 "01~99 year" 69 "01~99 year" 70 "01~99 year" 71 "01~99 year" 72 "01~99 year" 73 "01~99 year" 74 "01~99 year" 75 "01~99 year" 76 "01~99 year" 77 "01~99 year" 78 "01~99 year" 79 "01~99 year" 80 "01~99 year" 81 "01~99 year" 82 "01~99 year" 83 "01~99 year" 84 "01~99 year" 85 "01~99 year" 86 "01~99 year" 87 "01~99 year" 88 "01~99 year" 89 "01~99 year" 90 "01~99 year" 91 "01~99 year" 92 "01~99 year" 93 "01~99 year" 94 "01~99 year" 95 "01~99 year" 96 "01~99 year" 97 "01~99 year" 98 "01~99 year" 99 "01~99 year" 100 "64~0xFE:RESERVED" 254 "64~0xFE:RESERVED" 255 "Invalid" ;
VAL_ 1051 HU_DisplayDay 0 "Not used" 1 "1~31 day" 2 "1~31 day" 3 "1~31 day" 4 "1~31 day" 5 "1~31 day" 6 "1~31 day" 7 "1~31 day" 8 "1~31 day" 9 "1~31 day" 10 "1~31 day" 11 "1~31 day" 12 "1~31 day" 13 "1~31 day" 14 "1~31 day" 15 "1~31 day" 16 "1~31 day" 17 "1~31 day" 18 "1~31 day" 19 "1~31 day" 20 "1~31 day" 21 "1~31 day" 22 "1~31 day" 23 "1~31 day" 24 "1~31 day" 25 "1~31 day" 26 "1~31 day" 27 "1~31 day" 28 "1~31 day" 29 "1~31 day" 30 "1~31 day" 31 "1~31 day" 32 "20~0xFE:RESERVED" 254 "20~0xFE:RESERVED" 255 "Invalid" ;
VAL_ 1051 HU_AM_PM_INFO 0 "Not Used" 1 "AM" 2 "PM" 3 "invalid" ;
VAL_ 1051 HU_ComRefresh 0 "Not Used" 1 "Internal Clock None" 2 "Internal Clock Exist" 3 "Invalid" ;
VAL_ 1051 HU_ClockInfo 0 "Not Used" 1 "ACLOCK Refresh" 2 "Not Used" 3 "invalid" ;
VAL_ 1051 HU_CLOCK_AlvCnt1Val 0 "0x0~0xFF:AlvCntValue" 255 "0x0~0xFF:AlvCntValue" ;
VAL_ 1051 HU_TimeSetting 0 "not used" 1 "User Time" 2 "GPS Time" 3 "invalid" ;
VAL_ 1051 HU_Status 0 "Not used" 1 "Booting Head Unit" 2 "GPS receiving" 3 "Setting Mode" 4 "GPS Unavailable Mode" 5 "No GPS" 6 "RESERVED" 7 "RESERVED" 8 "RESERVED" 9 "RESERVED" 10 "RESERVED" 11 "RESERVED" 12 "RESERVED" 13 "RESERVED" 14 "RESERVED" 15 "Invalid" ;
VAL_ 1051 HU_TimeFormat 0 "Not used" 1 "12Hour" 2 "24Hour" 3 "invalid" ;
VAL_ 1051 HU_DisplayHour 0 "0 hour" 1 "1~23 hour" 2 "1~23 hour" 3 "1~23 hour" 4 "1~23 hour" 5 "1~23 hour" 6 "1~23 hour" 7 "1~23 hour" 8 "1~23 hour" 9 "1~23 hour" 10 "1~23 hour" 11 "1~23 hour" 12 "1~23 hour" 13 "1~23 hour" 14 "1~23 hour" 15 "1~23 hour" 16 "1~23 hour" 17 "1~23 hour" 18 "1~23 hour" 19 "1~23 hour" 20 "1~23 hour" 21 "1~23 hour" 22 "1~23 hour" 23 "1~23 hour" 24 "18~0xFE:RESERVED" 254 "18~0xFE:RESERVED" 255 "Invalid" ;
VAL_ 1051 HU_DisplayMinute 0 "0 minute" 1 "1~59 minute" 2 "1~59 minute" 3 "1~59 minute" 4 "1~59 minute" 5 "1~59 minute" 6 "1~59 minute" 7 "1~59 minute" 8 "1~59 minute" 9 "1~59 minute" 10 "1~59 minute" 11 "1~59 minute" 12 "1~59 minute" 13 "1~59 minute" 14 "1~59 minute" 15 "1~59 minute" 16 "1~59 minute" 17 "1~59 minute" 18 "1~59 minute" 19 "1~59 minute" 20 "1~59 minute" 21 "1~59 minute" 22 "1~59 minute" 23 "1~59 minute" 24 "1~59 minute" 25 "1~59 minute" 26 "1~59 minute" 27 "1~59 minute" 28 "1~59 minute" 29 "1~59 minute" 30 "1~59 minute" 31 "1~59 minute" 32 "1~59 minute" 33 "1~59 minute" 34 "1~59 minute" 35 "1~59 minute" 36 "1~59 minute" 37 "1~59 minute" 38 "1~59 minute" 39 "1~59 minute" 40 "1~59 minute" 41 "1~59 minute" 42 "1~59 minute" 43 "1~59 minute" 44 "1~59 minute" 45 "1~59 minute" 46 "1~59 minute" 47 "1~59 minute" 48 "1~59 minute" 49 "1~59 minute" 50 "1~59 minute" 51 "1~59 minute" 52 "1~59 minute" 53 "1~59 minute" 54 "1~59 minute" 55 "1~59 minute" 56 "1~59 minute" 57 "1~59 minute" 58 "1~59 minute" 59 "1~59 minute" 60 "3C~0xFE:RESERVED" 254 "3C~0xFE:RESERVED" 255 "Invalid" ;
VAL_ 1051 HU_DisplaySecond 0 "0 second" 1 "1~59 second" 2 "1~59 second" 3 "1~59 second" 4 "1~59 second" 5 "1~59 second" 6 "1~59 second" 7 "1~59 second" 8 "1~59 second" 9 "1~59 second" 10 "1~59 second" 11 "1~59 second" 12 "1~59 second" 13 "1~59 second" 14 "1~59 second" 15 "1~59 second" 16 "1~59 second" 17 "1~59 second" 18 "1~59 second" 19 "1~59 second" 20 "1~59 second" 21 "1~59 second" 22 "1~59 second" 23 "1~59 second" 24 "1~59 second" 25 "1~59 second" 26 "1~59 second" 27 "1~59 second" 28 "1~59 second" 29 "1~59 second" 30 "1~59 second" 31 "1~59 second" 32 "1~59 second" 33 "1~59 second" 34 "1~59 second" 35 "1~59 second" 36 "1~59 second" 37 "1~59 second" 38 "1~59 second" 39 "1~59 second" 40 "1~59 second" 41 "1~59 second" 42 "1~59 second" 43 "1~59 second" 44 "1~59 second" 45 "1~59 second" 46 "1~59 second" 47 "1~59 second" 48 "1~59 second" 49 "1~59 second" 50 "1~59 second" 51 "1~59 second" 52 "1~59 second" 53 "1~59 second" 54 "1~59 second" 55 "1~59 second" 56 "1~59 second" 57 "1~59 second" 58 "1~59 second" 59 "1~59 second" 60 "3C~0xFE:RESERVED" 254 "3C~0xFE:RESERVED" 255 "Invalid" ;
VAL_ 1051 HU_DisplayMonth 0 "Not used" 1 "1~12 month" 2 "1~12 month" 3 "1~12 month" 4 "1~12 month" 5 "1~12 month" 6 "1~12 month" 7 "1~12 month" 8 "1~12 month" 9 "1~12 month" 10 "1~12 month" 11 "1~12 month" 12 "1~12 month" 13 "RESERVED" 14 "RESERVED" 15 "Invalid" ;
VAL_ 1052 HU_CLU_Crc2Val 0 "0x0~0xFFFF:CRCValue" 65535 "0x0~0xFFFF:CRCValue" ;
VAL_ 1052 HU_EVSupport 0 "Not support" 1 "Support" 2 "RESERVED" 3 "Invalid" ;
VAL_ 1052 HU_DayNightState 0 "Default" 1 "Day" 2 "Night" 3 "Invalid" ;
VAL_ 1052 HU_AutoBrightState_New 0 "Default" 1 "1~0x3FE:Brightness" 1022 "1~0x3FE:Brightness" 1023 "Invalid" ;
VAL_ 1052 HU_CLU_AlvCnt2Val 0 "0x0~0xFF:AlvCntValue" 255 "0x0~0xFF:AlvCntValue" ;
VAL_ 1052 HU_OffloadBtnReq 0 "Default" 1 "Off" 2 "On" 3 "Invaild" ;
VAL_ 1052 HU_LanguageInfo 0 "Off" 1 "Korea" 2 "English(US)" 3 "English(UK)" 4 "Simplified chinese" 5 "Traditional chinese" 6 "French(EU)" 7 "Spanish(EU)" 8 "Arabic" 9 "Czech" 10 "Danish" 11 "German" 12 "Italian" 13 "Dutch" 14 "Polish" 15 "Portuguese" 16 "Russain" 17 "Slovak" 18 "Swedish" 19 "Turkish" 20 "French(US)" 21 "Spanish(US)" 22 "English(India)" 23 "Norwegian" 24 "Finnish" 25 "Indonesian" 26 "Brazilian Portuguese" 27 "Malay" 28 "Hungarian" 29 "English (Australia)" 30 "Japanese" 31 "Hindi" 32 "Hebrew" 33 "Greek" 34 "Ukrainian" 35 "Slovenian" 36 "Bulgarian" 37 "Croatian" 38 "Romanian" 39 "Bengali" 40 "Marathi" 41 "Telugu" 42 "Tamil" 43 "Gujarati" 44 "Kannada" 45 "Odia" 46 "Malayalam" 47 "Punjabi" 48 "Thai" 49 "Tagalog" 50 "Vietnamese" 51 "Lithuanian" 52 "Latvian" 53 "Estonian" 54 "36~0xFE:RESERVED" 254 "36~0xFE:RESERVED" 255 "Invalid" ;
VAL_ 1052 HU_MuteStatus 0 "Off" 1 "Mute On" 2 "RESERVED" 3 "Invalid" ;
VAL_ 1052 HU_WelcomeReady 0 "Default" 1 "Welcome ready" 2 "Goodbye ready" 3 "Invalid" ;
VAL_ 1052 HU_UsmSupport 0 "Not support" 1 "Support" 2 "RESERVED" 3 "Invalid" ;
VAL_ 1052 HU_NaviStatus 0 "Booting" 1 "Normal Operation" 2 "No SD Card(Map)" 3 "Invalid" ;
VAL_ 1052 HU_NaviDisp 0 "Non_Navi" 1 "Navi" 2 "RESERVED" 3 "Invalid" ;
VAL_ 1052 HU_BVM_Display_Message 0 "Not Used" 1 "No Message" 2 "Rain_Warning Message" 3 "RESERVED" 4 "RESERVED" 5 "RESERVED" 6 "RESERVED" 7 "Invalid" ;
VAL_ 1052 HU_NaviCamSettingStatus 0 "Navi Camera Alert Setting Status" 1 "Navi Camera Alert Setting Status" 2 "Navi Camera Alert Setting Status" 3 "Navi Camera Alert Setting Status" 4 "Navi Camera Alert Setting Status" 5 "Navi Camera Alert Setting Status" 6 "Navi Camera Alert Setting Status" 7 "Navi Camera Alert Setting Status" 8 "Navi Camera Alert Setting Status" 9 "Navi Camera Alert Setting Status" 10 "Navi Camera Alert Setting Status" 11 "Navi Camera Alert Setting Status" 12 "Navi Camera Alert Setting Status" 13 "Navi Camera Alert Setting Status" 14 "Navi Camera Alert Setting Status" 15 "Navi Camera Alert Setting Status" 16 "Navi Camera Alert Setting Status" 17 "Navi Camera Alert Setting Status" 18 "Navi Camera Alert Setting Status" 19 "Navi Camera Alert Setting Status" 20 "Navi Camera Alert Setting Status" 21 "Navi Camera Alert Setting Status" 22 "Navi Camera Alert Setting Status" 23 "Navi Camera Alert Setting Status" 24 "Navi Camera Alert Setting Status" 25 "Navi Camera Alert Setting Status" 26 "Navi Camera Alert Setting Status" 27 "Navi Camera Alert Setting Status" 28 "Navi Camera Alert Setting Status" 29 "Navi Camera Alert Setting Status" 30 "Navi Camera Alert Setting Status" 31 "Navi Camera Alert Setting Status" 32 "20~0xFE:RESERVED" 254 "20~0xFE:RESERVED" 255 "Invalid" ;
